[part 1 of 3: package /Svc_Dem]
AUTOSAR XML (schema 00047)
package /Svc_Dem
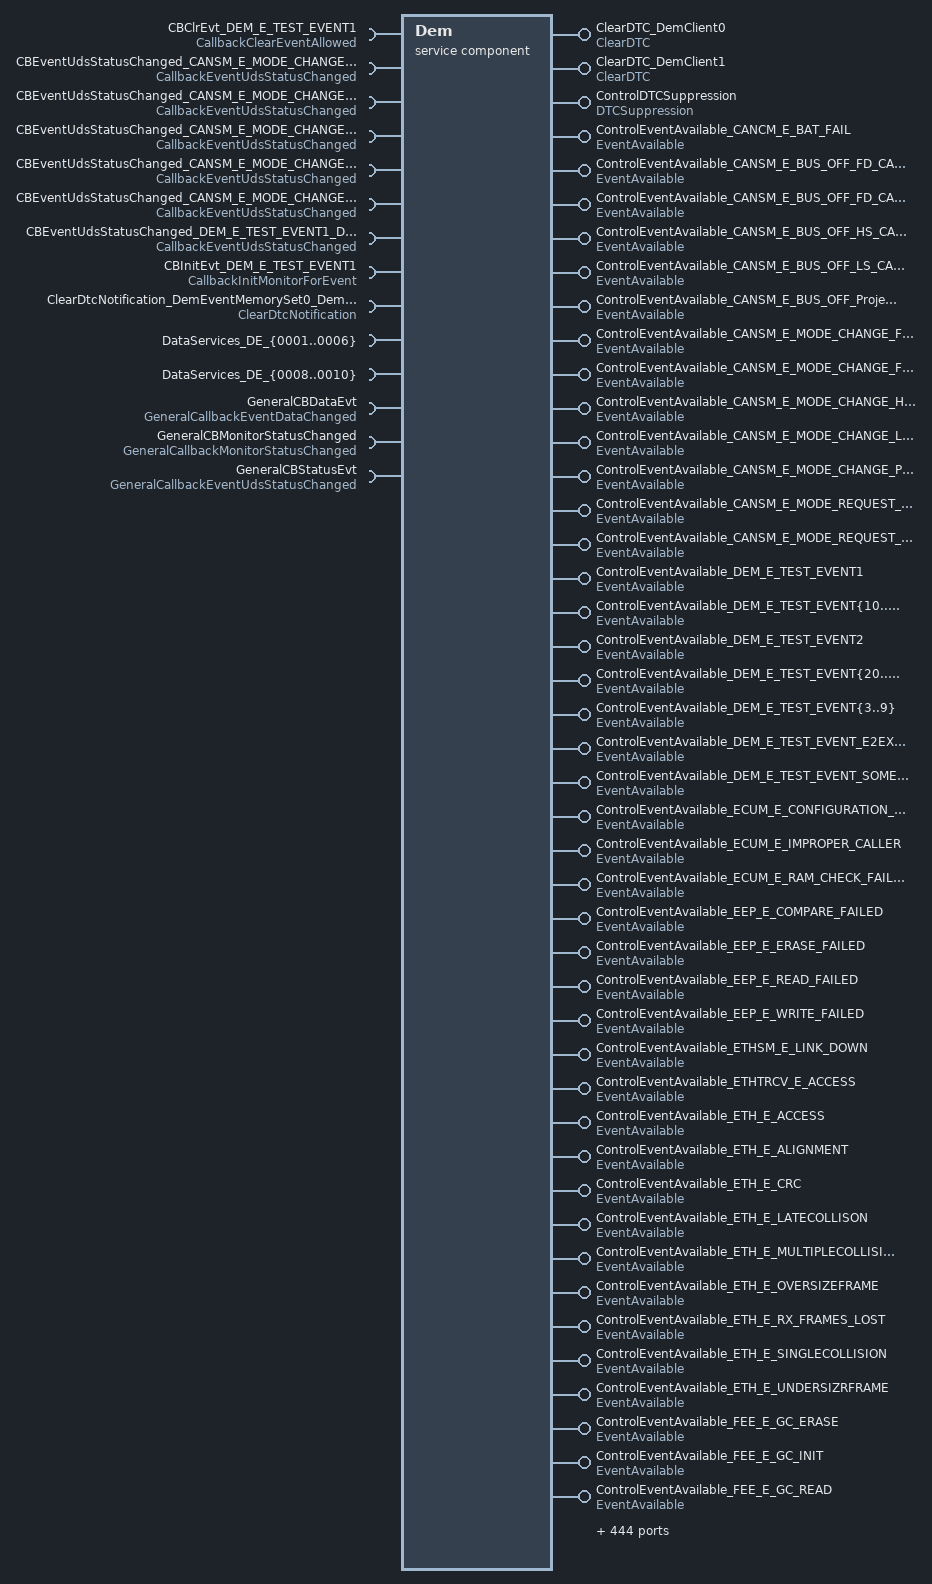
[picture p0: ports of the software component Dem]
  service sw component type Dem
    8 x require port:
      CBClrEvt_DEM_E_TEST_EVENT1: client-com-spec=ClearEventAllowed, required-interface=CallbackClearEventAllowed
      CBEventUdsStatusChanged_CANSM_E_MODE_CHANGE_FD_CAN1_DemCallbackEventUdsStatusChanged0: client-com-spec=CallbackEventUdsStatusChanged, required-interface=CallbackEventUdsStatusChanged
      CBEventUdsStatusChanged_CANSM_E_MODE_CHANGE_FD_CAN2_DemCallbackEventUdsStatusChanged0: client-com-spec=CallbackEventUdsStatusChanged, required-interface=CallbackEventUdsStatusChanged
      CBEventUdsStatusChanged_CANSM_E_MODE_CHANGE_HS_CAN1_DemCallbackEventUdsStatusChanged0: client-com-spec=CallbackEventUdsStatusChanged, required-interface=CallbackEventUdsStatusChanged
      CBEventUdsStatusChanged_CANSM_E_MODE_CHANGE_LS_CAN1_DemCallbackEventUdsStatusChanged0: client-com-spec=CallbackEventUdsStatusChanged, required-interface=CallbackEventUdsStatusChanged
      CBEventUdsStatusChanged_CANSM_E_MODE_CHANGE_Project_DemCallbackEventUdsStatusChanged0: client-com-spec=CallbackEventUdsStatusChanged, required-interface=CallbackEventUdsStatusChanged
      CBEventUdsStatusChanged_DEM_E_TEST_EVENT1_DemCallbackEventUdsStatusChanged0: client-com-spec=CallbackEventUdsStatusChanged, required-interface=CallbackEventUdsStatusChanged
      CBInitEvt_DEM_E_TEST_EVENT1: client-com-spec=InitMonitorForEvent, required-interface=CallbackInitMonitorForEvent
    provide port ClearDTC_DemClient0: provided-com-specs=[{operation=ClearDTC, queue-length=1}, {operation=SelectDTC, queue-length=1}], provided-interface=ClearDTC  # This port provides the Supervision interface of DemClient0 to a SWC.
    provide port ClearDTC_DemClient1: provided-com-specs=[{operation=ClearDTC, queue-length=1}, {operation=SelectDTC, queue-length=1}], provided-interface=ClearDTC  # This port provides the Supervision interface of DemClient1 to a SWC.
    require port ClearDtcNotification_DemEventMemorySet0_DemClearDTCNotification0: client-com-spec=ClearDtcNotification, required-interface=ClearDtcNotification
    108 x provide port:
      ControlDTCSuppression: provided-com-specs=[{operation=GetDTCSuppression, queue-length=1}, {operation=SetDTCSuppression, queue-length=1}], provided-interface=DTCSuppression  # This port provides the Supervision interface of ControlDTCSuppression to a SWC.
      ControlEventAvailable_CANCM_E_BAT_FAIL: server-com-spec{operation=SetEventAvailable, queue-length=1}, provided-interface=EventAvailable  # This port provides the Supervision interface of CANCM_E_BAT_FAIL to a SWC.
      ControlEventAvailable_CANSM_E_BUS_OFF_FD_CAN1: server-com-spec{operation=SetEventAvailable, queue-length=1}, provided-interface=EventAvailable  # This port provides the Supervision interface of CANSM_E_BUS_OFF_FD_CAN1 to a SWC.
      ControlEventAvailable_CANSM_E_BUS_OFF_FD_CAN2: server-com-spec{operation=SetEventAvailable, queue-length=1}, provided-interface=EventAvailable  # This port provides the Supervision interface of CANSM_E_BUS_OFF_FD_CAN2 to a SWC.
      ControlEventAvailable_CANSM_E_BUS_OFF_HS_CAN1: server-com-spec{operation=SetEventAvailable, queue-length=1}, provided-interface=EventAvailable  # This port provides the Supervision interface of CANSM_E_BUS_OFF_HS_CAN1 to a SWC.
      ControlEventAvailable_CANSM_E_BUS_OFF_LS_CAN1: server-com-spec{operation=SetEventAvailable, queue-length=1}, provided-interface=EventAvailable  # This port provides the Supervision interface of CANSM_E_BUS_OFF_LS_CAN1 to a SWC.
      ControlEventAvailable_CANSM_E_BUS_OFF_Project: server-com-spec{operation=SetEventAvailable, queue-length=1}, provided-interface=EventAvailable  # This port provides the Supervision interface of CANSM_E_BUS_OFF_Project to a SWC.
      ControlEventAvailable_CANSM_E_MODE_CHANGE_FD_CAN1: server-com-spec{operation=SetEventAvailable, queue-length=1}, provided-interface=EventAvailable  # This port provides the Supervision interface of CANSM_E_MODE_CHANGE_FD_CAN1 to a SWC.
      ControlEventAvailable_CANSM_E_MODE_CHANGE_FD_CAN2: server-com-spec{operation=SetEventAvailable, queue-length=1}, provided-interface=EventAvailable  # This port provides the Supervision interface of CANSM_E_MODE_CHANGE_FD_CAN2 to a SWC.
      ControlEventAvailable_CANSM_E_MODE_CHANGE_HS_CAN1: server-com-spec{operation=SetEventAvailable, queue-length=1}, provided-interface=EventAvailable  # This port provides the Supervision interface of CANSM_E_MODE_CHANGE_HS_CAN1 to a SWC.
      ControlEventAvailable_CANSM_E_MODE_CHANGE_LS_CAN1: server-com-spec{operation=SetEventAvailable, queue-length=1}, provided-interface=EventAvailable  # This port provides the Supervision interface of CANSM_E_MODE_CHANGE_LS_CAN1 to a SWC.
      ControlEventAvailable_CANSM_E_MODE_CHANGE_Project: server-com-spec{operation=SetEventAvailable, queue-length=1}, provided-interface=EventAvailable  # This port provides the Supervision interface of CANSM_E_MODE_CHANGE_Project to a SWC.
      ControlEventAvailable_CANSM_E_MODE_REQUEST_TIMEOUT_FD_CAN1: server-com-spec{operation=SetEventAvailable, queue-length=1}, provided-interface=EventAvailable  # This port provides the Supervision interface of CANSM_E_MODE_REQUEST_TIMEOUT_FD_CAN1 to a SWC.
      ControlEventAvailable_CANSM_E_MODE_REQUEST_TIMEOUT_HS_CAN1: server-com-spec{operation=SetEventAvailable, queue-length=1}, provided-interface=EventAvailable  # This port provides the Supervision interface of CANSM_E_MODE_REQUEST_TIMEOUT_HS_CAN1 to a SWC.
      ControlEventAvailable_DEM_E_TEST_EVENT1: server-com-spec{operation=SetEventAvailable, queue-length=1}, provided-interface=EventAvailable  # This port provides the Supervision interface of DEM_E_TEST_EVENT1 to a SWC.
      ControlEventAvailable_DEM_E_TEST_EVENT{10..19}: server-com-spec{operation=SetEventAvailable, queue-length=1}, provided-interface=EventAvailable  # This port provides the Supervision interface of DEM_E_TEST_EVENT{10..19} to a SWC.
      ControlEventAvailable_DEM_E_TEST_EVENT2: server-com-spec{operation=SetEventAvailable, queue-length=1}, provided-interface=EventAvailable  # This port provides the Supervision interface of DEM_E_TEST_EVENT2 to a SWC.
      ControlEventAvailable_DEM_E_TEST_EVENT{20..22}: server-com-spec{operation=SetEventAvailable, queue-length=1}, provided-interface=EventAvailable  # This port provides the Supervision interface of DEM_E_TEST_EVENT{20..22} to a SWC.
      ControlEventAvailable_DEM_E_TEST_EVENT{3..9}: server-com-spec{operation=SetEventAvailable, queue-length=1}, provided-interface=EventAvailable  # This port provides the Supervision interface of DEM_E_TEST_EVENT{3..9} to a SWC.
      ControlEventAvailable_DEM_E_TEST_EVENT_E2EXF_MALFORMED_MESSAGE: server-com-spec{operation=SetEventAvailable, queue-length=1}, provided-interface=EventAvailable  # This port provides the Supervision interface of DEM_E_TEST_EVENT_E2EXF_MALFORMED_MESSAGE to a SWC.
      ControlEventAvailable_DEM_E_TEST_EVENT_SOMEIPXF_MALFORMED_MESSAGE: server-com-spec{operation=SetEventAvailable, queue-length=1}, provided-interface=EventAvailable  # This port provides the Supervision interface of DEM_E_TEST_EVENT_SOMEIPXF_MALFORMED_MESSAGE to a SWC.
      ControlEventAvailable_ECUM_E_CONFIGURATION_DATA_INCONSISTENT: server-com-spec{operation=SetEventAvailable, queue-length=1}, provided-interface=EventAvailable  # This port provides the Supervision interface of ECUM_E_CONFIGURATION_DATA_INCONSISTENT to a SWC.
      ControlEventAvailable_ECUM_E_IMPROPER_CALLER: server-com-spec{operation=SetEventAvailable, queue-length=1}, provided-interface=EventAvailable  # This port provides the Supervision interface of ECUM_E_IMPROPER_CALLER to a SWC.
      ControlEventAvailable_ECUM_E_RAM_CHECK_FAILED: server-com-spec{operation=SetEventAvailable, queue-length=1}, provided-interface=EventAvailable  # This port provides the Supervision interface of ECUM_E_RAM_CHECK_FAILED to a SWC.
      ControlEventAvailable_EEP_E_COMPARE_FAILED: server-com-spec{operation=SetEventAvailable, queue-length=1}, provided-interface=EventAvailable  # This port provides the Supervision interface of EEP_E_COMPARE_FAILED to a SWC.
      ControlEventAvailable_EEP_E_ERASE_FAILED: server-com-spec{operation=SetEventAvailable, queue-length=1}, provided-interface=EventAvailable  # This port provides the Supervision interface of EEP_E_ERASE_FAILED to a SWC.
      ControlEventAvailable_EEP_E_READ_FAILED: server-com-spec{operation=SetEventAvailable, queue-length=1}, provided-interface=EventAvailable  # This port provides the Supervision interface of EEP_E_READ_FAILED to a SWC.
      ControlEventAvailable_EEP_E_WRITE_FAILED: server-com-spec{operation=SetEventAvailable, queue-length=1}, provided-interface=EventAvailable  # This port provides the Supervision interface of EEP_E_WRITE_FAILED to a SWC.
      ControlEventAvailable_ETHSM_E_LINK_DOWN: server-com-spec{operation=SetEventAvailable, queue-length=1}, provided-interface=EventAvailable  # This port provides the Supervision interface of ETHSM_E_LINK_DOWN to a SWC.
      ControlEventAvailable_ETHTRCV_E_ACCESS: server-com-spec{operation=SetEventAvailable, queue-length=1}, provided-interface=EventAvailable  # This port provides the Supervision interface of ETHTRCV_E_ACCESS to a SWC.
      ControlEventAvailable_ETH_E_ACCESS: server-com-spec{operation=SetEventAvailable, queue-length=1}, provided-interface=EventAvailable  # This port provides the Supervision interface of ETH_E_ACCESS to a SWC.
      ControlEventAvailable_ETH_E_ALIGNMENT: server-com-spec{operation=SetEventAvailable, queue-length=1}, provided-interface=EventAvailable  # This port provides the Supervision interface of ETH_E_ALIGNMENT to a SWC.
      ControlEventAvailable_ETH_E_CRC: server-com-spec{operation=SetEventAvailable, queue-length=1}, provided-interface=EventAvailable  # This port provides the Supervision interface of ETH_E_CRC to a SWC.
      ControlEventAvailable_ETH_E_LATECOLLISON: server-com-spec{operation=SetEventAvailable, queue-length=1}, provided-interface=EventAvailable  # This port provides the Supervision interface of ETH_E_LATECOLLISON to a SWC.
      ControlEventAvailable_ETH_E_MULTIPLECOLLISION: server-com-spec{operation=SetEventAvailable, queue-length=1}, provided-interface=EventAvailable  # This port provides the Supervision interface of ETH_E_MULTIPLECOLLISION to a SWC.
      ControlEventAvailable_ETH_E_OVERSIZEFRAME: server-com-spec{operation=SetEventAvailable, queue-length=1}, provided-interface=EventAvailable  # This port provides the Supervision interface of ETH_E_OVERSIZEFRAME to a SWC.
      ControlEventAvailable_ETH_E_RX_FRAMES_LOST: server-com-spec{operation=SetEventAvailable, queue-length=1}, provided-interface=EventAvailable  # This port provides the Supervision interface of ETH_E_RX_FRAMES_LOST to a SWC.
      ControlEventAvailable_ETH_E_SINGLECOLLISION: server-com-spec{operation=SetEventAvailable, queue-length=1}, provided-interface=EventAvailable  # This port provides the Supervision interface of ETH_E_SINGLECOLLISION to a SWC.
      ControlEventAvailable_ETH_E_UNDERSIZRFRAME: server-com-spec{operation=SetEventAvailable, queue-length=1}, provided-interface=EventAvailable  # This port provides the Supervision interface of ETH_E_UNDERSIZRFRAME to a SWC.
      ControlEventAvailable_FEE_E_GC_ERASE: server-com-spec{operation=SetEventAvailable, queue-length=1}, provided-interface=EventAvailable  # This port provides the Supervision interface of FEE_E_GC_ERASE to a SWC.
      ControlEventAvailable_FEE_E_GC_INIT: server-com-spec{operation=SetEventAvailable, queue-length=1}, provided-interface=EventAvailable  # This port provides the Supervision interface of FEE_E_GC_INIT to a SWC.
      ControlEventAvailable_FEE_E_GC_READ: server-com-spec{operation=SetEventAvailable, queue-length=1}, provided-interface=EventAvailable  # This port provides the Supervision interface of FEE_E_GC_READ to a SWC.
      ControlEventAvailable_FEE_E_GC_TRIG: server-com-spec{operation=SetEventAvailable, queue-length=1}, provided-interface=EventAvailable  # This port provides the Supervision interface of FEE_E_GC_TRIG to a SWC.
      ControlEventAvailable_FEE_E_GC_WRITE: server-com-spec{operation=SetEventAvailable, queue-length=1}, provided-interface=EventAvailable  # This port provides the Supervision interface of FEE_E_GC_WRITE to a SWC.
      ControlEventAvailable_FEE_E_INVALIDATE: server-com-spec{operation=SetEventAvailable, queue-length=1}, provided-interface=EventAvailable  # This port provides the Supervision interface of FEE_E_INVALIDATE to a SWC.
      ControlEventAvailable_FEE_E_READ: server-com-spec{operation=SetEventAvailable, queue-length=1}, provided-interface=EventAvailable  # This port provides the Supervision interface of FEE_E_READ to a SWC.
      ControlEventAvailable_FEE_E_UNCONFIG_BLK_EXCEEDED: server-com-spec{operation=SetEventAvailable, queue-length=1}, provided-interface=EventAvailable  # This port provides the Supervision interface of FEE_E_UNCONFIG_BLK_EXCEEDED to a SWC.
      ControlEventAvailable_FEE_E_WRITE: server-com-spec{operation=SetEventAvailable, queue-length=1}, provided-interface=EventAvailable  # This port provides the Supervision interface of FEE_E_WRITE to a SWC.
      ControlEventAvailable_FEE_E_WRITE_CYCLES_EXHAUSTED: server-com-spec{operation=SetEventAvailable, queue-length=1}, provided-interface=EventAvailable  # This port provides the Supervision interface of FEE_E_WRITE_CYCLES_EXHAUSTED to a SWC.
      ControlEventAvailable_FLS_E_COMPARE_FAILED: server-com-spec{operation=SetEventAvailable, queue-length=1}, provided-interface=EventAvailable  # This port provides the Supervision interface of FLS_E_COMPARE_FAILED to a SWC.
      ControlEventAvailable_FLS_E_ERASE_FAILED: server-com-spec{operation=SetEventAvailable, queue-length=1}, provided-interface=EventAvailable  # This port provides the Supervision interface of FLS_E_ERASE_FAILED to a SWC.
      ControlEventAvailable_FLS_E_READ_FAILED: server-com-spec{operation=SetEventAvailable, queue-length=1}, provided-interface=EventAvailable  # This port provides the Supervision interface of FLS_E_READ_FAILED to a SWC.
      ControlEventAvailable_FLS_E_UNEXPECTED_FLASH_ID: server-com-spec{operation=SetEventAvailable, queue-length=1}, provided-interface=EventAvailable  # This port provides the Supervision interface of FLS_E_UNEXPECTED_FLASH_ID to a SWC.
      ControlEventAvailable_FLS_E_WRITE_FAILED: server-com-spec{operation=SetEventAvailable, queue-length=1}, provided-interface=EventAvailable  # This port provides the Supervision interface of FLS_E_WRITE_FAILED to a SWC.
      ControlEventAvailable_IOHWAB_E_BUSY: server-com-spec{operation=SetEventAvailable, queue-length=1}, provided-interface=EventAvailable  # This port provides the Supervision interface of IOHWAB_E_BUSY to a SWC.
      ControlEventAvailable_IOHWAB_E_PROC_FAIL: server-com-spec{operation=SetEventAvailable, queue-length=1}, provided-interface=EventAvailable  # This port provides the Supervision interface of IOHWAB_E_PROC_FAIL to a SWC.
      ControlEventAvailable_IOHWAB_E_SETUP_FAIL: server-com-spec{operation=SetEventAvailable, queue-length=1}, provided-interface=EventAvailable  # This port provides the Supervision interface of IOHWAB_E_SETUP_FAIL to a SWC.
      ControlEventAvailable_IOHWAB_E_WRONG_PARAM: server-com-spec{operation=SetEventAvailable, queue-length=1}, provided-interface=EventAvailable  # This port provides the Supervision interface of IOHWAB_E_WRONG_PARAM to a SWC.
      ControlEventAvailable_IOHWAB_E_WRONG_SETTING: server-com-spec{operation=SetEventAvailable, queue-length=1}, provided-interface=EventAvailable  # This port provides the Supervision interface of IOHWAB_E_WRONG_SETTING to a SWC.
      ControlEventAvailable_IOHWAB_E_WRONG_STATE: server-com-spec{operation=SetEventAvailable, queue-length=1}, provided-interface=EventAvailable  # This port provides the Supervision interface of IOHWAB_E_WRONG_STATE to a SWC.
      ControlEventAvailable_MCU_E_CCU6_CLC_DISABLE_ERR: server-com-spec{operation=SetEventAvailable, queue-length=1}, provided-interface=EventAvailable  # This port provides the Supervision interface of MCU_E_CCU6_CLC_DISABLE_ERR to a SWC.
      ControlEventAvailable_MCU_E_CCU6_CLC_ENABLE_ERR: server-com-spec{operation=SetEventAvailable, queue-length=1}, provided-interface=EventAvailable  # This port provides the Supervision interface of MCU_E_CCU6_CLC_ENABLE_ERR to a SWC.
      ControlEventAvailable_MCU_E_CCUCON_UPDATE_ERR: server-com-spec{operation=SetEventAvailable, queue-length=1}, provided-interface=EventAvailable  # This port provides the Supervision interface of MCU_E_CCUCON_UPDATE_ERR to a SWC.
      ControlEventAvailable_MCU_E_CLOCK_FAILURE: server-com-spec{operation=SetEventAvailable, queue-length=1}, provided-interface=EventAvailable  # This port provides the Supervision interface of MCU_E_CLOCK_FAILURE to a SWC.
      ControlEventAvailable_MCU_E_CONVCTRL_CLC_DISABLE_ERR: server-com-spec{operation=SetEventAvailable, queue-length=1}, provided-interface=EventAvailable  # This port provides the Supervision interface of MCU_E_CONVCTRL_CLC_DISABLE_ERR to a SWC.
      ControlEventAvailable_MCU_E_CONVCTRL_CLC_ENABLE_ERR: server-com-spec{operation=SetEventAvailable, queue-length=1}, provided-interface=EventAvailable  # This port provides the Supervision interface of MCU_E_CONVCTRL_CLC_ENABLE_ERR to a SWC.
      ControlEventAvailable_MCU_E_GPT12_CLC_DISABLE_ERR: server-com-spec{operation=SetEventAvailable, queue-length=1}, provided-interface=EventAvailable  # This port provides the Supervision interface of MCU_E_GPT12_CLC_DISABLE_ERR to a SWC.
      ControlEventAvailable_MCU_E_GPT12_CLC_ENABLE_ERR: server-com-spec{operation=SetEventAvailable, queue-length=1}, provided-interface=EventAvailable  # This port provides the Supervision interface of MCU_E_GPT12_CLC_ENABLE_ERR to a SWC.
      ControlEventAvailable_MCU_E_GTM_CLC_DISABLE_ERR: server-com-spec{operation=SetEventAvailable, queue-length=1}, provided-interface=EventAvailable  # This port provides the Supervision interface of MCU_E_GTM_CLC_DISABLE_ERR to a SWC.
      ControlEventAvailable_MCU_E_GTM_CLC_ENABLE_ERR: server-com-spec{operation=SetEventAvailable, queue-length=1}, provided-interface=EventAvailable  # This port provides the Supervision interface of MCU_E_GTM_CLC_ENABLE_ERR to a SWC.
      ControlEventAvailable_MCU_E_OSC_FAILURE: server-com-spec{operation=SetEventAvailable, queue-length=1}, provided-interface=EventAvailable  # This port provides the Supervision interface of MCU_E_OSC_FAILURE to a SWC.
      ControlEventAvailable_MCU_E_PERIPHERAL_PLL_LOCK_LOSS: server-com-spec{operation=SetEventAvailable, queue-length=1}, provided-interface=EventAvailable  # This port provides the Supervision interface of MCU_E_PERIPHERAL_PLL_LOCK_LOSS to a SWC.
      ControlEventAvailable_MCU_E_PERIPHERAL_PLL_TIMEOUT_ERR: server-com-spec{operation=SetEventAvailable, queue-length=1}, provided-interface=EventAvailable  # This port provides the Supervision interface of MCU_E_PERIPHERAL_PLL_TIMEOUT_ERR to a SWC.
      ControlEventAvailable_MCU_E_PMSWCR_UPDATE_ERR: server-com-spec{operation=SetEventAvailable, queue-length=1}, provided-interface=EventAvailable  # This port provides the Supervision interface of MCU_E_PMSWCR_UPDATE_ERR to a SWC.
      ControlEventAvailable_MCU_E_SYSTEM_PLL_LOCK_LOSS: server-com-spec{operation=SetEventAvailable, queue-length=1}, provided-interface=EventAvailable  # This port provides the Supervision interface of MCU_E_SYSTEM_PLL_LOCK_LOSS to a SWC.
      ControlEventAvailable_MCU_E_SYSTEM_PLL_TIMEOUT_ERR: server-com-spec{operation=SetEventAvailable, queue-length=1}, provided-interface=EventAvailable  # This port provides the Supervision interface of MCU_E_SYSTEM_PLL_TIMEOUT_ERR to a SWC.
      ControlEventAvailable_NVM_E_INTEGRITY_FAILED: server-com-spec{operation=SetEventAvailable, queue-length=1}, provided-interface=EventAvailable  # This port provides the Supervision interface of NVM_E_INTEGRITY_FAILED to a SWC.
      ControlEventAvailable_NVM_E_LOSS_OF_REDUNDANCY: server-com-spec{operation=SetEventAvailable, queue-length=1}, provided-interface=EventAvailable  # This port provides the Supervision interface of NVM_E_LOSS_OF_REDUNDANCY to a SWC.
      ControlEventAvailable_NVM_E_QUEUE_OVERFLOW: server-com-spec{operation=SetEventAvailable, queue-length=1}, provided-interface=EventAvailable  # This port provides the Supervision interface of NVM_E_QUEUE_OVERFLOW to a SWC.
      ControlEventAvailable_NVM_E_REQ_FAILED: server-com-spec{operation=SetEventAvailable, queue-length=1}, provided-interface=EventAvailable  # This port provides the Supervision interface of NVM_E_REQ_FAILED to a SWC.
      ControlEventAvailable_NVM_E_VERIFY_FAILED: server-com-spec{operation=SetEventAvailable, queue-length=1}, provided-interface=EventAvailable  # This port provides the Supervision interface of NVM_E_VERIFY_FAILED to a SWC.
      ControlEventAvailable_NVM_E_WRITE_PROTECTED: server-com-spec{operation=SetEventAvailable, queue-length=1}, provided-interface=EventAvailable  # This port provides the Supervision interface of NVM_E_WRITE_PROTECTED to a SWC.
      ControlEventAvailable_NVM_E_WRONG_BLOCK_ID: server-com-spec{operation=SetEventAvailable, queue-length=1}, provided-interface=EventAvailable  # This port provides the Supervision interface of NVM_E_WRONG_BLOCK_ID to a SWC.
      ControlEventAvailable_SPI_E_HARDWARE_ERROR: server-com-spec{operation=SetEventAvailable, queue-length=1}, provided-interface=EventAvailable  # This port provides the Supervision interface of SPI_E_HARDWARE_ERROR to a SWC.
      ControlEventAvailable_WDGM_E_IMPROPER_CALLER: server-com-spec{operation=SetEventAvailable, queue-length=1}, provided-interface=EventAvailable  # This port provides the Supervision interface of WDGM_E_IMPROPER_CALLER to a SWC.
      ControlEventAvailable_WDGM_E_MONITORING: server-com-spec{operation=SetEventAvailable, queue-length=1}, provided-interface=EventAvailable  # This port provides the Supervision interface of WDGM_E_MONITORING to a SWC.
      ControlEventAvailable_WDGM_E_SET_MODE: server-com-spec{operation=SetEventAvailable, queue-length=1}, provided-interface=EventAvailable  # This port provides the Supervision interface of WDGM_E_SET_MODE to a SWC.
      ControlEventAvailable_WDG_76_ACW_E_DISABLE_REJECTED: server-com-spec{operation=SetEventAvailable, queue-length=1}, provided-interface=EventAvailable  # This port provides the Supervision interface of WDG_76_ACW_E_DISABLE_REJECTED to a SWC.
      ControlEventAvailable_WDG_76_ACW_E_MODE_FAILED: server-com-spec{operation=SetEventAvailable, queue-length=1}, provided-interface=EventAvailable  # This port provides the Supervision interface of WDG_76_ACW_E_MODE_FAILED to a SWC.
      ControlEventAvailable_WDG_E_DISABLE_REJECTED: server-com-spec{operation=SetEventAvailable, queue-length=1}, provided-interface=EventAvailable  # This port provides the Supervision interface of WDG_E_DISABLE_REJECTED to a SWC.
      ControlEventAvailable_WDG_E_MODE_FAILED: server-com-spec{operation=SetEventAvailable, queue-length=1}, provided-interface=EventAvailable  # This port provides the Supervision interface of WDG_E_MODE_FAILED to a SWC.
    9 x require port:
      DataServices_DE_{0001..0006}: client-com-spec=DataServices_DE_{0001..0006}/ReadData, required-interface=DataServices_DE_{0001..0006}
      DataServices_DE_{0008..0010}: client-com-spec=DataServices_DE_{0008..0010}/ReadData, required-interface=DataServices_DE_{0008..0010}
    429 x provide port:
      DiagnosticMonitor_MonitorData_CANCM_E_BAT_FAIL: server-com-spec{operation=DiagnosticMonitor_MonitorData/SetEventStatusWithMonitorData, queue-length=1}, provided-interface=DiagnosticMonitor_MonitorData  # This port provides the Supervision interface of CANCM_E_BAT_FAIL to a SWC.
      DiagnosticMonitor_MonitorData_CANSM_E_BUS_OFF_FD_CAN1: server-com-spec{operation=DiagnosticMonitor_MonitorData/SetEventStatusWithMonitorData, queue-length=1}, provided-interface=DiagnosticMonitor_MonitorData  # This port provides the Supervision interface of CANSM_E_BUS_OFF_FD_CAN1 to a SWC.
      DiagnosticMonitor_MonitorData_CANSM_E_BUS_OFF_FD_CAN2: server-com-spec{operation=DiagnosticMonitor_MonitorData/SetEventStatusWithMonitorData, queue-length=1}, provided-interface=DiagnosticMonitor_MonitorData  # This port provides the Supervision interface of CANSM_E_BUS_OFF_FD_CAN2 to a SWC.
      DiagnosticMonitor_MonitorData_CANSM_E_BUS_OFF_HS_CAN1: server-com-spec{operation=DiagnosticMonitor_MonitorData/SetEventStatusWithMonitorData, queue-length=1}, provided-interface=DiagnosticMonitor_MonitorData  # This port provides the Supervision interface of CANSM_E_BUS_OFF_HS_CAN1 to a SWC.
      DiagnosticMonitor_MonitorData_CANSM_E_BUS_OFF_LS_CAN1: server-com-spec{operation=DiagnosticMonitor_MonitorData/SetEventStatusWithMonitorData, queue-length=1}, provided-interface=DiagnosticMonitor_MonitorData  # This port provides the Supervision interface of CANSM_E_BUS_OFF_LS_CAN1 to a SWC.
      DiagnosticMonitor_MonitorData_CANSM_E_BUS_OFF_Project: server-com-spec{operation=DiagnosticMonitor_MonitorData/SetEventStatusWithMonitorData, queue-length=1}, provided-interface=DiagnosticMonitor_MonitorData  # This port provides the Supervision interface of CANSM_E_BUS_OFF_Project to a SWC.
      DiagnosticMonitor_MonitorData_CANSM_E_MODE_CHANGE_FD_CAN1: server-com-spec{operation=DiagnosticMonitor_MonitorData/SetEventStatusWithMonitorData, queue-length=1}, provided-interface=DiagnosticMonitor_MonitorData  # This port provides the Supervision interface of CANSM_E_MODE_CHANGE_FD_CAN1 to a SWC.
      DiagnosticMonitor_MonitorData_CANSM_E_MODE_CHANGE_FD_CAN2: server-com-spec{operation=DiagnosticMonitor_MonitorData/SetEventStatusWithMonitorData, queue-length=1}, provided-interface=DiagnosticMonitor_MonitorData  # This port provides the Supervision interface of CANSM_E_MODE_CHANGE_FD_CAN2 to a SWC.
      DiagnosticMonitor_MonitorData_CANSM_E_MODE_CHANGE_HS_CAN1: server-com-spec{operation=DiagnosticMonitor_MonitorData/SetEventStatusWithMonitorData, queue-length=1}, provided-interface=DiagnosticMonitor_MonitorData  # This port provides the Supervision interface of CANSM_E_MODE_CHANGE_HS_CAN1 to a SWC.
      DiagnosticMonitor_MonitorData_CANSM_E_MODE_CHANGE_LS_CAN1: server-com-spec{operation=DiagnosticMonitor_MonitorData/SetEventStatusWithMonitorData, queue-length=1}, provided-interface=DiagnosticMonitor_MonitorData  # This port provides the Supervision interface of CANSM_E_MODE_CHANGE_LS_CAN1 to a SWC.
      DiagnosticMonitor_MonitorData_CANSM_E_MODE_CHANGE_Project: server-com-spec{operation=DiagnosticMonitor_MonitorData/SetEventStatusWithMonitorData, queue-length=1}, provided-interface=DiagnosticMonitor_MonitorData  # This port provides the Supervision interface of CANSM_E_MODE_CHANGE_Project to a SWC.
      DiagnosticMonitor_MonitorData_CANSM_E_MODE_REQUEST_TIMEOUT_FD_CAN1: server-com-spec{operation=DiagnosticMonitor_MonitorData/SetEventStatusWithMonitorData, queue-length=1}, provided-interface=DiagnosticMonitor_MonitorData  # This port provides the Supervision interface of CANSM_E_MODE_REQUEST_TIMEOUT_FD_CAN1 to a SWC.
      DiagnosticMonitor_MonitorData_CANSM_E_MODE_REQUEST_TIMEOUT_HS_CAN1: server-com-spec{operation=DiagnosticMonitor_MonitorData/SetEventStatusWithMonitorData, queue-length=1}, provided-interface=DiagnosticMonitor_MonitorData  # This port provides the Supervision interface of CANSM_E_MODE_REQUEST_TIMEOUT_HS_CAN1 to a SWC.
      DiagnosticMonitor_MonitorData_DEM_E_TEST_EVENT1: server-com-spec{operation=DiagnosticMonitor_MonitorData/SetEventStatusWithMonitorData, queue-length=1}, provided-interface=DiagnosticMonitor_MonitorData  # This port provides the Supervision interface of DEM_E_TEST_EVENT1 to a SWC.
      DiagnosticMonitor_MonitorData_DEM_E_TEST_EVENT{10..19}: server-com-spec{operation=DiagnosticMonitor_MonitorData/SetEventStatusWithMonitorData, queue-length=1}, provided-interface=DiagnosticMonitor_MonitorData  # This port provides the Supervision interface of DEM_E_TEST_EVENT{10..19} to a SWC.
      DiagnosticMonitor_MonitorData_DEM_E_TEST_EVENT2: server-com-spec{operation=DiagnosticMonitor_MonitorData/SetEventStatusWithMonitorData, queue-length=1}, provided-interface=DiagnosticMonitor_MonitorData  # This port provides the Supervision interface of DEM_E_TEST_EVENT2 to a SWC.
      DiagnosticMonitor_MonitorData_DEM_E_TEST_EVENT{20..22}: server-com-spec{operation=DiagnosticMonitor_MonitorData/SetEventStatusWithMonitorData, queue-length=1}, provided-interface=DiagnosticMonitor_MonitorData  # This port provides the Supervision interface of DEM_E_TEST_EVENT{20..22} to a SWC.
      DiagnosticMonitor_MonitorData_DEM_E_TEST_EVENT{3..9}: server-com-spec{operation=DiagnosticMonitor_MonitorData/SetEventStatusWithMonitorData, queue-length=1}, provided-interface=DiagnosticMonitor_MonitorData  # This port provides the Supervision interface of DEM_E_TEST_EVENT{3..9} to a SWC.
      DiagnosticMonitor_MonitorData_DEM_E_TEST_EVENT_E2EXF_MALFORMED_MESSAGE: server-com-spec{operation=DiagnosticMonitor_MonitorData/SetEventStatusWithMonitorData, queue-length=1}, provided-interface=DiagnosticMonitor_MonitorData  # This port provides the Supervision interface of DEM_E_TEST_EVENT_E2EXF_MALFORMED_MESSAGE to a SWC.
      DiagnosticMonitor_MonitorData_DEM_E_TEST_EVENT_SOMEIPXF_MALFORMED_MESSAGE: server-com-spec{operation=DiagnosticMonitor_MonitorData/SetEventStatusWithMonitorData, queue-length=1}, provided-interface=DiagnosticMonitor_MonitorData  # This port provides the Supervision interface of DEM_E_TEST_EVENT_SOMEIPXF_MALFORMED_MESSAGE to a SWC.
      DiagnosticMonitor_MonitorData_ECUM_E_CONFIGURATION_DATA_INCONSISTENT: server-com-spec{operation=DiagnosticMonitor_MonitorData/SetEventStatusWithMonitorData, queue-length=1}, provided-interface=DiagnosticMonitor_MonitorData  # This port provides the Supervision interface of ECUM_E_CONFIGURATION_DATA_INCONSISTENT to a SWC.
      DiagnosticMonitor_MonitorData_ECUM_E_IMPROPER_CALLER: server-com-spec{operation=DiagnosticMonitor_MonitorData/SetEventStatusWithMonitorData, queue-length=1}, provided-interface=DiagnosticMonitor_MonitorData  # This port provides the Supervision interface of ECUM_E_IMPROPER_CALLER to a SWC.
      DiagnosticMonitor_MonitorData_ECUM_E_RAM_CHECK_FAILED: server-com-spec{operation=DiagnosticMonitor_MonitorData/SetEventStatusWithMonitorData, queue-length=1}, provided-interface=DiagnosticMonitor_MonitorData  # This port provides the Supervision interface of ECUM_E_RAM_CHECK_FAILED to a SWC.
      DiagnosticMonitor_MonitorData_EEP_E_COMPARE_FAILED: server-com-spec{operation=DiagnosticMonitor_MonitorData/SetEventStatusWithMonitorData, queue-length=1}, provided-interface=DiagnosticMonitor_MonitorData  # This port provides the Supervision interface of EEP_E_COMPARE_FAILED to a SWC.
      DiagnosticMonitor_MonitorData_EEP_E_ERASE_FAILED: server-com-spec{operation=DiagnosticMonitor_MonitorData/SetEventStatusWithMonitorData, queue-length=1}, provided-interface=DiagnosticMonitor_MonitorData  # This port provides the Supervision interface of EEP_E_ERASE_FAILED to a SWC.
      DiagnosticMonitor_MonitorData_EEP_E_READ_FAILED: server-com-spec{operation=DiagnosticMonitor_MonitorData/SetEventStatusWithMonitorData, queue-length=1}, provided-interface=DiagnosticMonitor_MonitorData  # This port provides the Supervision interface of EEP_E_READ_FAILED to a SWC.
      DiagnosticMonitor_MonitorData_EEP_E_WRITE_FAILED: server-com-spec{operation=DiagnosticMonitor_MonitorData/SetEventStatusWithMonitorData, queue-length=1}, provided-interface=DiagnosticMonitor_MonitorData  # This port provides the Supervision interface of EEP_E_WRITE_FAILED to a SWC.
      DiagnosticMonitor_MonitorData_ETHSM_E_LINK_DOWN: server-com-spec{operation=DiagnosticMonitor_MonitorData/SetEventStatusWithMonitorData, queue-length=1}, provided-interface=DiagnosticMonitor_MonitorData  # This port provides the Supervision interface of ETHSM_E_LINK_DOWN to a SWC.
      DiagnosticMonitor_MonitorData_ETHTRCV_E_ACCESS: server-com-spec{operation=DiagnosticMonitor_MonitorData/SetEventStatusWithMonitorData, queue-length=1}, provided-interface=DiagnosticMonitor_MonitorData  # This port provides the Supervision interface of ETHTRCV_E_ACCESS to a SWC.
      DiagnosticMonitor_MonitorData_ETH_E_ACCESS: server-com-spec{operation=DiagnosticMonitor_MonitorData/SetEventStatusWithMonitorData, queue-length=1}, provided-interface=DiagnosticMonitor_MonitorData  # This port provides the Supervision interface of ETH_E_ACCESS to a SWC.
      DiagnosticMonitor_MonitorData_ETH_E_ALIGNMENT: server-com-spec{operation=DiagnosticMonitor_MonitorData/SetEventStatusWithMonitorData, queue-length=1}, provided-interface=DiagnosticMonitor_MonitorData  # This port provides the Supervision interface of ETH_E_ALIGNMENT to a SWC.
      DiagnosticMonitor_MonitorData_ETH_E_CRC: server-com-spec{operation=DiagnosticMonitor_MonitorData/SetEventStatusWithMonitorData, queue-length=1}, provided-interface=DiagnosticMonitor_MonitorData  # This port provides the Supervision interface of ETH_E_CRC to a SWC.
      DiagnosticMonitor_MonitorData_ETH_E_LATECOLLISON: server-com-spec{operation=DiagnosticMonitor_MonitorData/SetEventStatusWithMonitorData, queue-length=1}, provided-interface=DiagnosticMonitor_MonitorData  # This port provides the Supervision interface of ETH_E_LATECOLLISON to a SWC.
      DiagnosticMonitor_MonitorData_ETH_E_MULTIPLECOLLISION: server-com-spec{operation=DiagnosticMonitor_MonitorData/SetEventStatusWithMonitorData, queue-length=1}, provided-interface=DiagnosticMonitor_MonitorData  # This port provides the Supervision interface of ETH_E_MULTIPLECOLLISION to a SWC.
      DiagnosticMonitor_MonitorData_ETH_E_OVERSIZEFRAME: server-com-spec{operation=DiagnosticMonitor_MonitorData/SetEventStatusWithMonitorData, queue-length=1}, provided-interface=DiagnosticMonitor_MonitorData  # This port provides the Supervision interface of ETH_E_OVERSIZEFRAME to a SWC.
      DiagnosticMonitor_MonitorData_ETH_E_RX_FRAMES_LOST: server-com-spec{operation=DiagnosticMonitor_MonitorData/SetEventStatusWithMonitorData, queue-length=1}, provided-interface=DiagnosticMonitor_MonitorData  # This port provides the Supervision interface of ETH_E_RX_FRAMES_LOST to a SWC.
      DiagnosticMonitor_MonitorData_ETH_E_SINGLECOLLISION: server-com-spec{operation=DiagnosticMonitor_MonitorData/SetEventStatusWithMonitorData, queue-length=1}, provided-interface=DiagnosticMonitor_MonitorData  # This port provides the Supervision interface of ETH_E_SINGLECOLLISION to a SWC.
      DiagnosticMonitor_MonitorData_ETH_E_UNDERSIZRFRAME: server-com-spec{operation=DiagnosticMonitor_MonitorData/SetEventStatusWithMonitorData, queue-length=1}, provided-interface=DiagnosticMonitor_MonitorData  # This port provides the Supervision interface of ETH_E_UNDERSIZRFRAME to a SWC.
      DiagnosticMonitor_MonitorData_FEE_E_GC_ERASE: server-com-spec{operation=DiagnosticMonitor_MonitorData/SetEventStatusWithMonitorData, queue-length=1}, provided-interface=DiagnosticMonitor_MonitorData  # This port provides the Supervision interface of FEE_E_GC_ERASE to a SWC.
      DiagnosticMonitor_MonitorData_FEE_E_GC_INIT: server-com-spec{operation=DiagnosticMonitor_MonitorData/SetEventStatusWithMonitorData, queue-length=1}, provided-interface=DiagnosticMonitor_MonitorData  # This port provides the Supervision interface of FEE_E_GC_INIT to a SWC.
      DiagnosticMonitor_MonitorData_FEE_E_GC_READ: server-com-spec{operation=DiagnosticMonitor_MonitorData/SetEventStatusWithMonitorData, queue-length=1}, provided-interface=DiagnosticMonitor_MonitorData  # This port provides the Supervision interface of FEE_E_GC_READ to a SWC.
      DiagnosticMonitor_MonitorData_FEE_E_GC_TRIG: server-com-spec{operation=DiagnosticMonitor_MonitorData/SetEventStatusWithMonitorData, queue-length=1}, provided-interface=DiagnosticMonitor_MonitorData  # This port provides the Supervision interface of FEE_E_GC_TRIG to a SWC.
      DiagnosticMonitor_MonitorData_FEE_E_GC_WRITE: server-com-spec{operation=DiagnosticMonitor_MonitorData/SetEventStatusWithMonitorData, queue-length=1}, provided-interface=DiagnosticMonitor_MonitorData  # This port provides the Supervision interface of FEE_E_GC_WRITE to a SWC.
      DiagnosticMonitor_MonitorData_FEE_E_INVALIDATE: server-com-spec{operation=DiagnosticMonitor_MonitorData/SetEventStatusWithMonitorData, queue-length=1}, provided-interface=DiagnosticMonitor_MonitorData  # This port provides the Supervision interface of FEE_E_INVALIDATE to a SWC.
      DiagnosticMonitor_MonitorData_FEE_E_READ: server-com-spec{operation=DiagnosticMonitor_MonitorData/SetEventStatusWithMonitorData, queue-length=1}, provided-interface=DiagnosticMonitor_MonitorData  # This port provides the Supervision interface of FEE_E_READ to a SWC.
      DiagnosticMonitor_MonitorData_FEE_E_UNCONFIG_BLK_EXCEEDED: server-com-spec{operation=DiagnosticMonitor_MonitorData/SetEventStatusWithMonitorData, queue-length=1}, provided-interface=DiagnosticMonitor_MonitorData  # This port provides the Supervision interface of FEE_E_UNCONFIG_BLK_EXCEEDED to a SWC.
      DiagnosticMonitor_MonitorData_FEE_E_WRITE: server-com-spec{operation=DiagnosticMonitor_MonitorData/SetEventStatusWithMonitorData, queue-length=1}, provided-interface=DiagnosticMonitor_MonitorData  # This port provides the Supervision interface of FEE_E_WRITE to a SWC.
      DiagnosticMonitor_MonitorData_FEE_E_WRITE_CYCLES_EXHAUSTED: server-com-spec{operation=DiagnosticMonitor_MonitorData/SetEventStatusWithMonitorData, queue-length=1}, provided-interface=DiagnosticMonitor_MonitorData  # This port provides the Supervision interface of FEE_E_WRITE_CYCLES_EXHAUSTED to a SWC.
      DiagnosticMonitor_MonitorData_FLS_E_COMPARE_FAILED: server-com-spec{operation=DiagnosticMonitor_MonitorData/SetEventStatusWithMonitorData, queue-length=1}, provided-interface=DiagnosticMonitor_MonitorData  # This port provides the Supervision interface of FLS_E_COMPARE_FAILED to a SWC.
      DiagnosticMonitor_MonitorData_FLS_E_ERASE_FAILED: server-com-spec{operation=DiagnosticMonitor_MonitorData/SetEventStatusWithMonitorData, queue-length=1}, provided-interface=DiagnosticMonitor_MonitorData  # This port provides the Supervision interface of FLS_E_ERASE_FAILED to a SWC.
      DiagnosticMonitor_MonitorData_FLS_E_READ_FAILED: server-com-spec{operation=DiagnosticMonitor_MonitorData/SetEventStatusWithMonitorData, queue-length=1}, provided-interface=DiagnosticMonitor_MonitorData  # This port provides the Supervision interface of FLS_E_READ_FAILED to a SWC.
      DiagnosticMonitor_MonitorData_FLS_E_UNEXPECTED_FLASH_ID: server-com-spec{operation=DiagnosticMonitor_MonitorData/SetEventStatusWithMonitorData, queue-length=1}, provided-interface=DiagnosticMonitor_MonitorData  # This port provides the Supervision interface of FLS_E_UNEXPECTED_FLASH_ID to a SWC.
      DiagnosticMonitor_MonitorData_FLS_E_WRITE_FAILED: server-com-spec{operation=DiagnosticMonitor_MonitorData/SetEventStatusWithMonitorData, queue-length=1}, provided-interface=DiagnosticMonitor_MonitorData  # This port provides the Supervision interface of FLS_E_WRITE_FAILED to a SWC.
      DiagnosticMonitor_MonitorData_IOHWAB_E_BUSY: server-com-spec{operation=DiagnosticMonitor_MonitorData/SetEventStatusWithMonitorData, queue-length=1}, provided-interface=DiagnosticMonitor_MonitorData  # This port provides the Supervision interface of IOHWAB_E_BUSY to a SWC.
      DiagnosticMonitor_MonitorData_IOHWAB_E_PROC_FAIL: server-com-spec{operation=DiagnosticMonitor_MonitorData/SetEventStatusWithMonitorData, queue-length=1}, provided-interface=DiagnosticMonitor_MonitorData  # This port provides the Supervision interface of IOHWAB_E_PROC_FAIL to a SWC.
      DiagnosticMonitor_MonitorData_IOHWAB_E_SETUP_FAIL: server-com-spec{operation=DiagnosticMonitor_MonitorData/SetEventStatusWithMonitorData, queue-length=1}, provided-interface=DiagnosticMonitor_MonitorData  # This port provides the Supervision interface of IOHWAB_E_SETUP_FAIL to a SWC.
      DiagnosticMonitor_MonitorData_IOHWAB_E_WRONG_PARAM: server-com-spec{operation=DiagnosticMonitor_MonitorData/SetEventStatusWithMonitorData, queue-length=1}, provided-interface=DiagnosticMonitor_MonitorData  # This port provides the Supervision interface of IOHWAB_E_WRONG_PARAM to a SWC.
      DiagnosticMonitor_MonitorData_IOHWAB_E_WRONG_SETTING: server-com-spec{operation=DiagnosticMonitor_MonitorData/SetEventStatusWithMonitorData, queue-length=1}, provided-interface=DiagnosticMonitor_MonitorData  # This port provides the Supervision interface of IOHWAB_E_WRONG_SETTING to a SWC.
      DiagnosticMonitor_MonitorData_IOHWAB_E_WRONG_STATE: server-com-spec{operation=DiagnosticMonitor_MonitorData/SetEventStatusWithMonitorData, queue-length=1}, provided-interface=DiagnosticMonitor_MonitorData  # This port provides the Supervision interface of IOHWAB_E_WRONG_STATE to a SWC.
      DiagnosticMonitor_MonitorData_MCU_E_CCU6_CLC_DISABLE_ERR: server-com-spec{operation=DiagnosticMonitor_MonitorData/SetEventStatusWithMonitorData, queue-length=1}, provided-interface=DiagnosticMonitor_MonitorData  # This port provides the Supervision interface of MCU_E_CCU6_CLC_DISABLE_ERR to a SWC.
      DiagnosticMonitor_MonitorData_MCU_E_CCU6_CLC_ENABLE_ERR: server-com-spec{operation=DiagnosticMonitor_MonitorData/SetEventStatusWithMonitorData, queue-length=1}, provided-interface=DiagnosticMonitor_MonitorData  # This port provides the Supervision interface of MCU_E_CCU6_CLC_ENABLE_ERR to a SWC.
      DiagnosticMonitor_MonitorData_MCU_E_CCUCON_UPDATE_ERR: server-com-spec{operation=DiagnosticMonitor_MonitorData/SetEventStatusWithMonitorData, queue-length=1}, provided-interface=DiagnosticMonitor_MonitorData  # This port provides the Supervision interface of MCU_E_CCUCON_UPDATE_ERR to a SWC.
      DiagnosticMonitor_MonitorData_MCU_E_CLOCK_FAILURE: server-com-spec{operation=DiagnosticMonitor_MonitorData/SetEventStatusWithMonitorData, queue-length=1}, provided-interface=DiagnosticMonitor_MonitorData  # This port provides the Supervision interface of MCU_E_CLOCK_FAILURE to a SWC.
      DiagnosticMonitor_MonitorData_MCU_E_CONVCTRL_CLC_DISABLE_ERR: server-com-spec{operation=DiagnosticMonitor_MonitorData/SetEventStatusWithMonitorData, queue-length=1}, provided-interface=DiagnosticMonitor_MonitorData  # This port provides the Supervision interface of MCU_E_CONVCTRL_CLC_DISABLE_ERR to a SWC.
      DiagnosticMonitor_MonitorData_MCU_E_CONVCTRL_CLC_ENABLE_ERR: server-com-spec{operation=DiagnosticMonitor_MonitorData/SetEventStatusWithMonitorData, queue-length=1}, provided-interface=DiagnosticMonitor_MonitorData  # This port provides the Supervision interface of MCU_E_CONVCTRL_CLC_ENABLE_ERR to a SWC.
      DiagnosticMonitor_MonitorData_MCU_E_GPT12_CLC_DISABLE_ERR: server-com-spec{operation=DiagnosticMonitor_MonitorData/SetEventStatusWithMonitorData, queue-length=1}, provided-interface=DiagnosticMonitor_MonitorData  # This port provides the Supervision interface of MCU_E_GPT12_CLC_DISABLE_ERR to a SWC.
      DiagnosticMonitor_MonitorData_MCU_E_GPT12_CLC_ENABLE_ERR: server-com-spec{operation=DiagnosticMonitor_MonitorData/SetEventStatusWithMonitorData, queue-length=1}, provided-interface=DiagnosticMonitor_MonitorData  # This port provides the Supervision interface of MCU_E_GPT12_CLC_ENABLE_ERR to a SWC.
      DiagnosticMonitor_MonitorData_MCU_E_GTM_CLC_DISABLE_ERR: server-com-spec{operation=DiagnosticMonitor_MonitorData/SetEventStatusWithMonitorData, queue-length=1}, provided-interface=DiagnosticMonitor_MonitorData  # This port provides the Supervision interface of MCU_E_GTM_CLC_DISABLE_ERR to a SWC.
      DiagnosticMonitor_MonitorData_MCU_E_GTM_CLC_ENABLE_ERR: server-com-spec{operation=DiagnosticMonitor_MonitorData/SetEventStatusWithMonitorData, queue-length=1}, provided-interface=DiagnosticMonitor_MonitorData  # This port provides the Supervision interface of MCU_E_GTM_CLC_ENABLE_ERR to a SWC.
      DiagnosticMonitor_MonitorData_MCU_E_OSC_FAILURE: server-com-spec{operation=DiagnosticMonitor_MonitorData/SetEventStatusWithMonitorData, queue-length=1}, provided-interface=DiagnosticMonitor_MonitorData  # This port provides the Supervision interface of MCU_E_OSC_FAILURE to a SWC.
      DiagnosticMonitor_MonitorData_MCU_E_PERIPHERAL_PLL_LOCK_LOSS: server-com-spec{operation=DiagnosticMonitor_MonitorData/SetEventStatusWithMonitorData, queue-length=1}, provided-interface=DiagnosticMonitor_MonitorData  # This port provides the Supervision interface of MCU_E_PERIPHERAL_PLL_LOCK_LOSS to a SWC.
      DiagnosticMonitor_MonitorData_MCU_E_PERIPHERAL_PLL_TIMEOUT_ERR: server-com-spec{operation=DiagnosticMonitor_MonitorData/SetEventStatusWithMonitorData, queue-length=1}, provided-interface=DiagnosticMonitor_MonitorData  # This port provides the Supervision interface of MCU_E_PERIPHERAL_PLL_TIMEOUT_ERR to a SWC.
      DiagnosticMonitor_MonitorData_MCU_E_PMSWCR_UPDATE_ERR: server-com-spec{operation=DiagnosticMonitor_MonitorData/SetEventStatusWithMonitorData, queue-length=1}, provided-interface=DiagnosticMonitor_MonitorData  # This port provides the Supervision interface of MCU_E_PMSWCR_UPDATE_ERR to a SWC.
      DiagnosticMonitor_MonitorData_MCU_E_SYSTEM_PLL_LOCK_LOSS: server-com-spec{operation=DiagnosticMonitor_MonitorData/SetEventStatusWithMonitorData, queue-length=1}, provided-interface=DiagnosticMonitor_MonitorData  # This port provides the Supervision interface of MCU_E_SYSTEM_PLL_LOCK_LOSS to a SWC.
      DiagnosticMonitor_MonitorData_MCU_E_SYSTEM_PLL_TIMEOUT_ERR: server-com-spec{operation=DiagnosticMonitor_MonitorData/SetEventStatusWithMonitorData, queue-length=1}, provided-interface=DiagnosticMonitor_MonitorData  # This port provides the Supervision interface of MCU_E_SYSTEM_PLL_TIMEOUT_ERR to a SWC.
      DiagnosticMonitor_MonitorData_NVM_E_INTEGRITY_FAILED: server-com-spec{operation=DiagnosticMonitor_MonitorData/SetEventStatusWithMonitorData, queue-length=1}, provided-interface=DiagnosticMonitor_MonitorData  # This port provides the Supervision interface of NVM_E_INTEGRITY_FAILED to a SWC.
      DiagnosticMonitor_MonitorData_NVM_E_LOSS_OF_REDUNDANCY: server-com-spec{operation=DiagnosticMonitor_MonitorData/SetEventStatusWithMonitorData, queue-length=1}, provided-interface=DiagnosticMonitor_MonitorData  # This port provides the Supervision interface of NVM_E_LOSS_OF_REDUNDANCY to a SWC.
      DiagnosticMonitor_MonitorData_NVM_E_QUEUE_OVERFLOW: server-com-spec{operation=DiagnosticMonitor_MonitorData/SetEventStatusWithMonitorData, queue-length=1}, provided-interface=DiagnosticMonitor_MonitorData  # This port provides the Supervision interface of NVM_E_QUEUE_OVERFLOW to a SWC.
      DiagnosticMonitor_MonitorData_NVM_E_REQ_FAILED: server-com-spec{operation=DiagnosticMonitor_MonitorData/SetEventStatusWithMonitorData, queue-length=1}, provided-interface=DiagnosticMonitor_MonitorData  # This port provides the Supervision interface of NVM_E_REQ_FAILED to a SWC.
      DiagnosticMonitor_MonitorData_NVM_E_VERIFY_FAILED: server-com-spec{operation=DiagnosticMonitor_MonitorData/SetEventStatusWithMonitorData, queue-length=1}, provided-interface=DiagnosticMonitor_MonitorData  # This port provides the Supervision interface of NVM_E_VERIFY_FAILED to a SWC.
      DiagnosticMonitor_MonitorData_NVM_E_WRITE_PROTECTED: server-com-spec{operation=DiagnosticMonitor_MonitorData/SetEventStatusWithMonitorData, queue-length=1}, provided-interface=DiagnosticMonitor_MonitorData  # This port provides the Supervision interface of NVM_E_WRITE_PROTECTED to a SWC.
      DiagnosticMonitor_MonitorData_NVM_E_WRONG_BLOCK_ID: server-com-spec{operation=DiagnosticMonitor_MonitorData/SetEventStatusWithMonitorData, queue-length=1}, provided-interface=DiagnosticMonitor_MonitorData  # This port provides the Supervision interface of NVM_E_WRONG_BLOCK_ID to a SWC.
      DiagnosticMonitor_MonitorData_SPI_E_HARDWARE_ERROR: server-com-spec{operation=DiagnosticMonitor_MonitorData/SetEventStatusWithMonitorData, queue-length=1}, provided-interface=DiagnosticMonitor_MonitorData  # This port provides the Supervision interface of SPI_E_HARDWARE_ERROR to a SWC.
      DiagnosticMonitor_MonitorData_WDGM_E_IMPROPER_CALLER: server-com-spec{operation=DiagnosticMonitor_MonitorData/SetEventStatusWithMonitorData, queue-length=1}, provided-interface=DiagnosticMonitor_MonitorData  # This port provides the Supervision interface of WDGM_E_IMPROPER_CALLER to a SWC.
      DiagnosticMonitor_MonitorData_WDGM_E_MONITORING: server-com-spec{operation=DiagnosticMonitor_MonitorData/SetEventStatusWithMonitorData, queue-length=1}, provided-interface=DiagnosticMonitor_MonitorData  # This port provides the Supervision interface of WDGM_E_MONITORING to a SWC.
      DiagnosticMonitor_MonitorData_WDGM_E_SET_MODE: server-com-spec{operation=DiagnosticMonitor_MonitorData/SetEventStatusWithMonitorData, queue-length=1}, provided-interface=DiagnosticMonitor_MonitorData  # This port provides the Supervision interface of WDGM_E_SET_MODE to a SWC.
      DiagnosticMonitor_MonitorData_WDG_76_ACW_E_DISABLE_REJECTED: server-com-spec{operation=DiagnosticMonitor_MonitorData/SetEventStatusWithMonitorData, queue-length=1}, provided-interface=DiagnosticMonitor_MonitorData  # This port provides the Supervision interface of WDG_76_ACW_E_DISABLE_REJECTED to a SWC.
      DiagnosticMonitor_MonitorData_WDG_76_ACW_E_MODE_FAILED: server-com-spec{operation=DiagnosticMonitor_MonitorData/SetEventStatusWithMonitorData, queue-length=1}, provided-interface=DiagnosticMonitor_MonitorData  # This port provides the Supervision interface of WDG_76_ACW_E_MODE_FAILED to a SWC.
      DiagnosticMonitor_MonitorData_WDG_E_DISABLE_REJECTED: server-com-spec{operation=DiagnosticMonitor_MonitorData/SetEventStatusWithMonitorData, queue-length=1}, provided-interface=DiagnosticMonitor_MonitorData  # This port provides the Supervision interface of WDG_E_DISABLE_REJECTED to a SWC.
      DiagnosticMonitor_MonitorData_WDG_E_MODE_FAILED: server-com-spec{operation=DiagnosticMonitor_MonitorData/SetEventStatusWithMonitorData, queue-length=1}, provided-interface=DiagnosticMonitor_MonitorData  # This port provides the Supervision interface of WDG_E_MODE_FAILED to a SWC.
      EnableCond_DemEnableCondition0: server-com-spec{operation=SetEnableCondition, queue-length=1}, provided-interface=EnableCondition  # This port provides the Supervision interface of DemEnableCondition0 to a SWC.
      EventInfo_CANCM_E_BAT_FAIL: provided-interface=DiagnosticInfo  # This port provides the Supervision interface of CANCM_E_BAT_FAIL to a SWC.
        provided-com-specs:
          operation=DiagnosticInfo/GetDTCOfEvent, queue-length=1
          operation=DiagnosticInfo/GetDebouncingOfEvent, queue-length=1
          operation=GetEventExtendedDataRecordEx, queue-length=1
          operation=GetEventFreezeFrameDataEx, queue-length=1
          operation=DiagnosticInfo/GetEventUdsStatus, queue-length=1
          operation=DiagnosticInfo/GetFaultDetectionCounter, queue-length=1
          operation=DiagnosticInfo/GetMonitorStatus, queue-length=1
      EventInfo_CANSM_E_BUS_OFF_FD_CAN1: provided-interface=DiagnosticInfo  # This port provides the Supervision interface of CANSM_E_BUS_OFF_FD_CAN1 to a SWC.
        provided-com-specs:
          operation=DiagnosticInfo/GetDTCOfEvent, queue-length=1
          operation=DiagnosticInfo/GetDebouncingOfEvent, queue-length=1
          operation=GetEventExtendedDataRecordEx, queue-length=1
          operation=GetEventFreezeFrameDataEx, queue-length=1
          operation=DiagnosticInfo/GetEventUdsStatus, queue-length=1
          operation=DiagnosticInfo/GetFaultDetectionCounter, queue-length=1
          operation=DiagnosticInfo/GetMonitorStatus, queue-length=1
      EventInfo_CANSM_E_BUS_OFF_FD_CAN2: provided-interface=DiagnosticInfo  # This port provides the Supervision interface of CANSM_E_BUS_OFF_FD_CAN2 to a SWC.
        provided-com-specs:
          operation=DiagnosticInfo/GetDTCOfEvent, queue-length=1
          operation=DiagnosticInfo/GetDebouncingOfEvent, queue-length=1
          operation=GetEventExtendedDataRecordEx, queue-length=1
          operation=GetEventFreezeFrameDataEx, queue-length=1
          operation=DiagnosticInfo/GetEventUdsStatus, queue-length=1
          operation=DiagnosticInfo/GetFaultDetectionCounter, queue-length=1
          operation=DiagnosticInfo/GetMonitorStatus, queue-length=1
      EventInfo_CANSM_E_BUS_OFF_HS_CAN1: provided-interface=DiagnosticInfo  # This port provides the Supervision interface of CANSM_E_BUS_OFF_HS_CAN1 to a SWC.
        provided-com-specs:
          operation=DiagnosticInfo/GetDTCOfEvent, queue-length=1
          operation=DiagnosticInfo/GetDebouncingOfEvent, queue-length=1
          operation=GetEventExtendedDataRecordEx, queue-length=1
          operation=GetEventFreezeFrameDataEx, queue-length=1
          operation=DiagnosticInfo/GetEventUdsStatus, queue-length=1
          operation=DiagnosticInfo/GetFaultDetectionCounter, queue-length=1
          operation=DiagnosticInfo/GetMonitorStatus, queue-length=1
      EventInfo_CANSM_E_BUS_OFF_LS_CAN1: provided-interface=DiagnosticInfo  # This port provides the Supervision interface of CANSM_E_BUS_OFF_LS_CAN1 to a SWC.
        provided-com-specs:
          operation=DiagnosticInfo/GetDTCOfEvent, queue-length=1
          operation=DiagnosticInfo/GetDebouncingOfEvent, queue-length=1
          operation=GetEventExtendedDataRecordEx, queue-length=1
          operation=GetEventFreezeFrameDataEx, queue-length=1
          operation=DiagnosticInfo/GetEventUdsStatus, queue-length=1
          operation=DiagnosticInfo/GetFaultDetectionCounter, queue-length=1
          operation=DiagnosticInfo/GetMonitorStatus, queue-length=1
      EventInfo_CANSM_E_BUS_OFF_Project: provided-interface=DiagnosticInfo  # This port provides the Supervision interface of CANSM_E_BUS_OFF_Project to a SWC.
        provided-com-specs:
          operation=DiagnosticInfo/GetDTCOfEvent, queue-length=1
          operation=DiagnosticInfo/GetDebouncingOfEvent, queue-length=1
          operation=GetEventExtendedDataRecordEx, queue-length=1
          operation=GetEventFreezeFrameDataEx, queue-length=1
          operation=DiagnosticInfo/GetEventUdsStatus, queue-length=1
          operation=DiagnosticInfo/GetFaultDetectionCounter, queue-length=1
          operation=DiagnosticInfo/GetMonitorStatus, queue-length=1
      EventInfo_CANSM_E_MODE_CHANGE_FD_CAN1: provided-interface=DiagnosticInfo  # This port provides the Supervision interface of CANSM_E_MODE_CHANGE_FD_CAN1 to a SWC.
        provided-com-specs:
          operation=DiagnosticInfo/GetDTCOfEvent, queue-length=1
          operation=DiagnosticInfo/GetDebouncingOfEvent, queue-length=1
          operation=GetEventExtendedDataRecordEx, queue-length=1
          operation=GetEventFreezeFrameDataEx, queue-length=1
          operation=DiagnosticInfo/GetEventUdsStatus, queue-length=1
          operation=DiagnosticInfo/GetFaultDetectionCounter, queue-length=1
          operation=DiagnosticInfo/GetMonitorStatus, queue-length=1
      EventInfo_CANSM_E_MODE_CHANGE_FD_CAN2: provided-interface=DiagnosticInfo  # This port provides the Supervision interface of CANSM_E_MODE_CHANGE_FD_CAN2 to a SWC.
        provided-com-specs:
          operation=DiagnosticInfo/GetDTCOfEvent, queue-length=1
          operation=DiagnosticInfo/GetDebouncingOfEvent, queue-length=1
          operation=GetEventExtendedDataRecordEx, queue-length=1
          operation=GetEventFreezeFrameDataEx, queue-length=1
          operation=DiagnosticInfo/GetEventUdsStatus, queue-length=1
          operation=DiagnosticInfo/GetFaultDetectionCounter, queue-length=1
          operation=DiagnosticInfo/GetMonitorStatus, queue-length=1
      EventInfo_CANSM_E_MODE_CHANGE_HS_CAN1: provided-interface=DiagnosticInfo  # This port provides the Supervision interface of CANSM_E_MODE_CHANGE_HS_CAN1 to a SWC.
        provided-com-specs:
          operation=DiagnosticInfo/GetDTCOfEvent, queue-length=1
          operation=DiagnosticInfo/GetDebouncingOfEvent, queue-length=1
          operation=GetEventExtendedDataRecordEx, queue-length=1
          operation=GetEventFreezeFrameDataEx, queue-length=1
          operation=DiagnosticInfo/GetEventUdsStatus, queue-length=1
          operation=DiagnosticInfo/GetFaultDetectionCounter, queue-length=1
          operation=DiagnosticInfo/GetMonitorStatus, queue-length=1
      EventInfo_CANSM_E_MODE_CHANGE_LS_CAN1: provided-interface=DiagnosticInfo  # This port provides the Supervision interface of CANSM_E_MODE_CHANGE_LS_CAN1 to a SWC.
        provided-com-specs:
          operation=DiagnosticInfo/GetDTCOfEvent, queue-length=1
          operation=DiagnosticInfo/GetDebouncingOfEvent, queue-length=1
          operation=GetEventExtendedDataRecordEx, queue-length=1
          operation=GetEventFreezeFrameDataEx, queue-length=1
          operation=DiagnosticInfo/GetEventUdsStatus, queue-length=1
          operation=DiagnosticInfo/GetFaultDetectionCounter, queue-length=1
          operation=DiagnosticInfo/GetMonitorStatus, queue-length=1
      EventInfo_CANSM_E_MODE_CHANGE_Project: provided-interface=DiagnosticInfo  # This port provides the Supervision interface of CANSM_E_MODE_CHANGE_Project to a SWC.
        provided-com-specs:
          operation=DiagnosticInfo/GetDTCOfEvent, queue-length=1
          operation=DiagnosticInfo/GetDebouncingOfEvent, queue-length=1
          operation=GetEventExtendedDataRecordEx, queue-length=1
          operation=GetEventFreezeFrameDataEx, queue-length=1
          operation=DiagnosticInfo/GetEventUdsStatus, queue-length=1
          operation=DiagnosticInfo/GetFaultDetectionCounter, queue-length=1
          operation=DiagnosticInfo/GetMonitorStatus, queue-length=1
      EventInfo_CANSM_E_MODE_REQUEST_TIMEOUT_FD_CAN1: provided-interface=DiagnosticInfo  # This port provides the Supervision interface of CANSM_E_MODE_REQUEST_TIMEOUT_FD_CAN1 to a SWC.
        provided-com-specs:
          operation=DiagnosticInfo/GetDTCOfEvent, queue-length=1
          operation=DiagnosticInfo/GetDebouncingOfEvent, queue-length=1
          operation=GetEventExtendedDataRecordEx, queue-length=1
          operation=GetEventFreezeFrameDataEx, queue-length=1
          operation=DiagnosticInfo/GetEventUdsStatus, queue-length=1
          operation=DiagnosticInfo/GetFaultDetectionCounter, queue-length=1
          operation=DiagnosticInfo/GetMonitorStatus, queue-length=1
      EventInfo_CANSM_E_MODE_REQUEST_TIMEOUT_HS_CAN1: provided-interface=DiagnosticInfo  # This port provides the Supervision interface of CANSM_E_MODE_REQUEST_TIMEOUT_HS_CAN1 to a SWC.
        provided-com-specs:
          operation=DiagnosticInfo/GetDTCOfEvent, queue-length=1
          operation=DiagnosticInfo/GetDebouncingOfEvent, queue-length=1
          operation=GetEventExtendedDataRecordEx, queue-length=1
          operation=GetEventFreezeFrameDataEx, queue-length=1
          operation=DiagnosticInfo/GetEventUdsStatus, queue-length=1
          operation=DiagnosticInfo/GetFaultDetectionCounter, queue-length=1
          operation=DiagnosticInfo/GetMonitorStatus, queue-length=1
      EventInfo_DEM_E_TEST_EVENT1: provided-interface=DiagnosticInfo  # This port provides the Supervision interface of DEM_E_TEST_EVENT1 to a SWC.
        provided-com-specs:
          operation=DiagnosticInfo/GetDTCOfEvent, queue-length=1
          operation=DiagnosticInfo/GetDebouncingOfEvent, queue-length=1
          operation=GetEventExtendedDataRecordEx, queue-length=1
          operation=GetEventFreezeFrameDataEx, queue-length=1
          operation=DiagnosticInfo/GetEventUdsStatus, queue-length=1
          operation=DiagnosticInfo/GetFaultDetectionCounter, queue-length=1
          operation=DiagnosticInfo/GetMonitorStatus, queue-length=1
      EventInfo_DEM_E_TEST_EVENT10: provided-interface=DiagnosticInfo  # This port provides the Supervision interface of DEM_E_TEST_EVENT10 to a SWC.
        provided-com-specs:
          operation=DiagnosticInfo/GetDTCOfEvent, queue-length=1
          operation=DiagnosticInfo/GetDebouncingOfEvent, queue-length=1
          operation=GetEventExtendedDataRecordEx, queue-length=1
          operation=GetEventFreezeFrameDataEx, queue-length=1
          operation=DiagnosticInfo/GetEventUdsStatus, queue-length=1
          operation=DiagnosticInfo/GetFaultDetectionCounter, queue-length=1
          operation=DiagnosticInfo/GetMonitorStatus, queue-length=1
      EventInfo_DEM_E_TEST_EVENT11: provided-interface=DiagnosticInfo  # This port provides the Supervision interface of DEM_E_TEST_EVENT11 to a SWC.
        provided-com-specs:
          operation=DiagnosticInfo/GetDTCOfEvent, queue-length=1
          operation=DiagnosticInfo/GetDebouncingOfEvent, queue-length=1
          operation=GetEventExtendedDataRecordEx, queue-length=1
          operation=GetEventFreezeFrameDataEx, queue-length=1
          operation=DiagnosticInfo/GetEventUdsStatus, queue-length=1
          operation=DiagnosticInfo/GetFaultDetectionCounter, queue-length=1
          operation=DiagnosticInfo/GetMonitorStatus, queue-length=1
      EventInfo_DEM_E_TEST_EVENT12: provided-interface=DiagnosticInfo  # This port provides the Supervision interface of DEM_E_TEST_EVENT12 to a SWC.
        provided-com-specs:
          operation=DiagnosticInfo/GetDTCOfEvent, queue-length=1
          operation=DiagnosticInfo/GetDebouncingOfEvent, queue-length=1
          operation=GetEventExtendedDataRecordEx, queue-length=1
          operation=GetEventFreezeFrameDataEx, queue-length=1
          operation=DiagnosticInfo/GetEventUdsStatus, queue-length=1
          operation=DiagnosticInfo/GetFaultDetectionCounter, queue-length=1
          operation=DiagnosticInfo/GetMonitorStatus, queue-length=1
      EventInfo_DEM_E_TEST_EVENT13: provided-interface=DiagnosticInfo  # This port provides the Supervision interface of DEM_E_TEST_EVENT13 to a SWC.
        provided-com-specs:
          operation=DiagnosticInfo/GetDTCOfEvent, queue-length=1
          operation=DiagnosticInfo/GetDebouncingOfEvent, queue-length=1
          operation=GetEventExtendedDataRecordEx, queue-length=1
          operation=GetEventFreezeFrameDataEx, queue-length=1
          operation=DiagnosticInfo/GetEventUdsStatus, queue-length=1
          operation=DiagnosticInfo/GetFaultDetectionCounter, queue-length=1
          operation=DiagnosticInfo/GetMonitorStatus, queue-length=1
      EventInfo_DEM_E_TEST_EVENT14: provided-interface=DiagnosticInfo  # This port provides the Supervision interface of DEM_E_TEST_EVENT14 to a SWC.
        provided-com-specs:
          operation=DiagnosticInfo/GetDTCOfEvent, queue-length=1
          operation=DiagnosticInfo/GetDebouncingOfEvent, queue-length=1
          operation=GetEventExtendedDataRecordEx, queue-length=1
          operation=GetEventFreezeFrameDataEx, queue-length=1
          operation=DiagnosticInfo/GetEventUdsStatus, queue-length=1
          operation=DiagnosticInfo/GetFaultDetectionCounter, queue-length=1
          operation=DiagnosticInfo/GetMonitorStatus, queue-length=1
      EventInfo_DEM_E_TEST_EVENT15: provided-interface=DiagnosticInfo  # This port provides the Supervision interface of DEM_E_TEST_EVENT15 to a SWC.
        provided-com-specs:
          operation=DiagnosticInfo/GetDTCOfEvent, queue-length=1
          operation=DiagnosticInfo/GetDebouncingOfEvent, queue-length=1
          operation=GetEventExtendedDataRecordEx, queue-length=1
          operation=GetEventFreezeFrameDataEx, queue-length=1
          operation=DiagnosticInfo/GetEventUdsStatus, queue-length=1
          operation=DiagnosticInfo/GetFaultDetectionCounter, queue-length=1
          operation=DiagnosticInfo/GetMonitorStatus, queue-length=1
      EventInfo_DEM_E_TEST_EVENT16: provided-interface=DiagnosticInfo  # This port provides the Supervision interface of DEM_E_TEST_EVENT16 to a SWC.
        provided-com-specs:
          operation=DiagnosticInfo/GetDTCOfEvent, queue-length=1
          operation=DiagnosticInfo/GetDebouncingOfEvent, queue-length=1
          operation=GetEventExtendedDataRecordEx, queue-length=1
          operation=GetEventFreezeFrameDataEx, queue-length=1
          operation=DiagnosticInfo/GetEventUdsStatus, queue-length=1
          operation=DiagnosticInfo/GetFaultDetectionCounter, queue-length=1
          operation=DiagnosticInfo/GetMonitorStatus, queue-length=1
      EventInfo_DEM_E_TEST_EVENT17: provided-interface=DiagnosticInfo  # This port provides the Supervision interface of DEM_E_TEST_EVENT17 to a SWC.
        provided-com-specs:
          operation=DiagnosticInfo/GetDTCOfEvent, queue-length=1
          operation=DiagnosticInfo/GetDebouncingOfEvent, queue-length=1
          operation=GetEventExtendedDataRecordEx, queue-length=1
          operation=GetEventFreezeFrameDataEx, queue-length=1
          operation=DiagnosticInfo/GetEventUdsStatus, queue-length=1
          operation=DiagnosticInfo/GetFaultDetectionCounter, queue-length=1
          operation=DiagnosticInfo/GetMonitorStatus, queue-length=1
      EventInfo_DEM_E_TEST_EVENT18: provided-interface=DiagnosticInfo  # This port provides the Supervision interface of DEM_E_TEST_EVENT18 to a SWC.
        provided-com-specs:
          operation=DiagnosticInfo/GetDTCOfEvent, queue-length=1
          operation=DiagnosticInfo/GetDebouncingOfEvent, queue-length=1
          operation=GetEventExtendedDataRecordEx, queue-length=1
          operation=GetEventFreezeFrameDataEx, queue-length=1
          operation=DiagnosticInfo/GetEventUdsStatus, queue-length=1
          operation=DiagnosticInfo/GetFaultDetectionCounter, queue-length=1
          operation=DiagnosticInfo/GetMonitorStatus, queue-length=1
      EventInfo_DEM_E_TEST_EVENT19: provided-interface=DiagnosticInfo  # This port provides the Supervision interface of DEM_E_TEST_EVENT19 to a SWC.
        provided-com-specs:
          operation=DiagnosticInfo/GetDTCOfEvent, queue-length=1
          operation=DiagnosticInfo/GetDebouncingOfEvent, queue-length=1
          operation=GetEventExtendedDataRecordEx, queue-length=1
          operation=GetEventFreezeFrameDataEx, queue-length=1
          operation=DiagnosticInfo/GetEventUdsStatus, queue-length=1
          operation=DiagnosticInfo/GetFaultDetectionCounter, queue-length=1
          operation=DiagnosticInfo/GetMonitorStatus, queue-length=1
      EventInfo_DEM_E_TEST_EVENT2: provided-interface=DiagnosticInfo  # This port provides the Supervision interface of DEM_E_TEST_EVENT2 to a SWC.
        provided-com-specs:
          operation=DiagnosticInfo/GetDTCOfEvent, queue-length=1
          operation=DiagnosticInfo/GetDebouncingOfEvent, queue-length=1
          operation=GetEventExtendedDataRecordEx, queue-length=1
          operation=GetEventFreezeFrameDataEx, queue-length=1
          operation=DiagnosticInfo/GetEventUdsStatus, queue-length=1
          operation=DiagnosticInfo/GetFaultDetectionCounter, queue-length=1
          operation=DiagnosticInfo/GetMonitorStatus, queue-length=1
      EventInfo_DEM_E_TEST_EVENT20: provided-interface=DiagnosticInfo  # This port provides the Supervision interface of DEM_E_TEST_EVENT20 to a SWC.
        provided-com-specs:
          operation=DiagnosticInfo/GetDTCOfEvent, queue-length=1
          operation=DiagnosticInfo/GetDebouncingOfEvent, queue-length=1
          operation=GetEventExtendedDataRecordEx, queue-length=1
          operation=GetEventFreezeFrameDataEx, queue-length=1
          operation=DiagnosticInfo/GetEventUdsStatus, queue-length=1
          operation=DiagnosticInfo/GetFaultDetectionCounter, queue-length=1
          operation=DiagnosticInfo/GetMonitorStatus, queue-length=1
      EventInfo_DEM_E_TEST_EVENT21: provided-interface=DiagnosticInfo  # This port provides the Supervision interface of DEM_E_TEST_EVENT21 to a SWC.
        provided-com-specs:
          operation=DiagnosticInfo/GetDTCOfEvent, queue-length=1
          operation=DiagnosticInfo/GetDebouncingOfEvent, queue-length=1
          operation=GetEventExtendedDataRecordEx, queue-length=1
          operation=GetEventFreezeFrameDataEx, queue-length=1
          operation=DiagnosticInfo/GetEventUdsStatus, queue-length=1
          operation=DiagnosticInfo/GetFaultDetectionCounter, queue-length=1
          operation=DiagnosticInfo/GetMonitorStatus, queue-length=1
      EventInfo_DEM_E_TEST_EVENT22: provided-interface=DiagnosticInfo  # This port provides the Supervision interface of DEM_E_TEST_EVENT22 to a SWC.
        provided-com-specs:
          operation=DiagnosticInfo/GetDTCOfEvent, queue-length=1
          operation=DiagnosticInfo/GetDebouncingOfEvent, queue-length=1
          operation=GetEventExtendedDataRecordEx, queue-length=1
          operation=GetEventFreezeFrameDataEx, queue-length=1
          operation=DiagnosticInfo/GetEventUdsStatus, queue-length=1
          operation=DiagnosticInfo/GetFaultDetectionCounter, queue-length=1
          operation=DiagnosticInfo/GetMonitorStatus, queue-length=1
      EventInfo_DEM_E_TEST_EVENT3: provided-interface=DiagnosticInfo  # This port provides the Supervision interface of DEM_E_TEST_EVENT3 to a SWC.
        provided-com-specs:
          operation=DiagnosticInfo/GetDTCOfEvent, queue-length=1
          operation=DiagnosticInfo/GetDebouncingOfEvent, queue-length=1
          operation=GetEventExtendedDataRecordEx, queue-length=1
          operation=GetEventFreezeFrameDataEx, queue-length=1
          operation=DiagnosticInfo/GetEventUdsStatus, queue-length=1
          operation=DiagnosticInfo/GetFaultDetectionCounter, queue-length=1
          operation=DiagnosticInfo/GetMonitorStatus, queue-length=1
      EventInfo_DEM_E_TEST_EVENT4: provided-interface=DiagnosticInfo  # This port provides the Supervision interface of DEM_E_TEST_EVENT4 to a SWC.
        provided-com-specs:
          operation=DiagnosticInfo/GetDTCOfEvent, queue-length=1
          operation=DiagnosticInfo/GetDebouncingOfEvent, queue-length=1
          operation=GetEventExtendedDataRecordEx, queue-length=1
          operation=GetEventFreezeFrameDataEx, queue-length=1
          operation=DiagnosticInfo/GetEventUdsStatus, queue-length=1
          operation=DiagnosticInfo/GetFaultDetectionCounter, queue-length=1
          operation=DiagnosticInfo/GetMonitorStatus, queue-length=1
      EventInfo_DEM_E_TEST_EVENT5: provided-interface=DiagnosticInfo  # This port provides the Supervision interface of DEM_E_TEST_EVENT5 to a SWC.
        provided-com-specs:
          operation=DiagnosticInfo/GetDTCOfEvent, queue-length=1
          operation=DiagnosticInfo/GetDebouncingOfEvent, queue-length=1
          operation=GetEventExtendedDataRecordEx, queue-length=1
          operation=GetEventFreezeFrameDataEx, queue-length=1
          operation=DiagnosticInfo/GetEventUdsStatus, queue-length=1
          operation=DiagnosticInfo/GetFaultDetectionCounter, queue-length=1
          operation=DiagnosticInfo/GetMonitorStatus, queue-length=1
      EventInfo_DEM_E_TEST_EVENT6: provided-interface=DiagnosticInfo  # This port provides the Supervision interface of DEM_E_TEST_EVENT6 to a SWC.
        provided-com-specs:
          operation=DiagnosticInfo/GetDTCOfEvent, queue-length=1
          operation=DiagnosticInfo/GetDebouncingOfEvent, queue-length=1
          operation=GetEventExtendedDataRecordEx, queue-length=1
          operation=GetEventFreezeFrameDataEx, queue-length=1
          operation=DiagnosticInfo/GetEventUdsStatus, queue-length=1
          operation=DiagnosticInfo/GetFaultDetectionCounter, queue-length=1
          operation=DiagnosticInfo/GetMonitorStatus, queue-length=1
      EventInfo_DEM_E_TEST_EVENT7: provided-interface=DiagnosticInfo  # This port provides the Supervision interface of DEM_E_TEST_EVENT7 to a SWC.
        provided-com-specs:
          operation=DiagnosticInfo/GetDTCOfEvent, queue-length=1
          operation=DiagnosticInfo/GetDebouncingOfEvent, queue-length=1
          operation=GetEventExtendedDataRecordEx, queue-length=1
          operation=GetEventFreezeFrameDataEx, queue-length=1
          operation=DiagnosticInfo/GetEventUdsStatus, queue-length=1
          operation=DiagnosticInfo/GetFaultDetectionCounter, queue-length=1
          operation=DiagnosticInfo/GetMonitorStatus, queue-length=1
      EventInfo_DEM_E_TEST_EVENT8: provided-interface=DiagnosticInfo  # This port provides the Supervision interface of DEM_E_TEST_EVENT8 to a SWC.
        provided-com-specs:
          operation=DiagnosticInfo/GetDTCOfEvent, queue-length=1
          operation=DiagnosticInfo/GetDebouncingOfEvent, queue-length=1
          operation=GetEventExtendedDataRecordEx, queue-length=1
          operation=GetEventFreezeFrameDataEx, queue-length=1
          operation=DiagnosticInfo/GetEventUdsStatus, queue-length=1
          operation=DiagnosticInfo/GetFaultDetectionCounter, queue-length=1
          operation=DiagnosticInfo/GetMonitorStatus, queue-length=1
      EventInfo_DEM_E_TEST_EVENT9: provided-interface=DiagnosticInfo  # This port provides the Supervision interface of DEM_E_TEST_EVENT9 to a SWC.
        provided-com-specs:
          operation=DiagnosticInfo/GetDTCOfEvent, queue-length=1
          operation=DiagnosticInfo/GetDebouncingOfEvent, queue-length=1
          operation=GetEventExtendedDataRecordEx, queue-length=1
          operation=GetEventFreezeFrameDataEx, queue-length=1
          operation=DiagnosticInfo/GetEventUdsStatus, queue-length=1
          operation=DiagnosticInfo/GetFaultDetectionCounter, queue-length=1
          operation=DiagnosticInfo/GetMonitorStatus, queue-length=1
      EventInfo_DEM_E_TEST_EVENT_E2EXF_MALFORMED_MESSAGE: provided-interface=DiagnosticInfo  # This port provides the Supervision interface of DEM_E_TEST_EVENT_E2EXF_MALFORMED_MESSAGE to a SWC.
        provided-com-specs:
          operation=DiagnosticInfo/GetDTCOfEvent, queue-length=1
          operation=DiagnosticInfo/GetDebouncingOfEvent, queue-length=1
          operation=GetEventExtendedDataRecordEx, queue-length=1
          operation=GetEventFreezeFrameDataEx, queue-length=1
          operation=DiagnosticInfo/GetEventUdsStatus, queue-length=1
          operation=DiagnosticInfo/GetFaultDetectionCounter, queue-length=1
          operation=DiagnosticInfo/GetMonitorStatus, queue-length=1
      EventInfo_DEM_E_TEST_EVENT_SOMEIPXF_MALFORMED_MESSAGE: provided-interface=DiagnosticInfo  # This port provides the Supervision interface of DEM_E_TEST_EVENT_SOMEIPXF_MALFORMED_MESSAGE to a SWC.
        provided-com-specs:
          operation=DiagnosticInfo/GetDTCOfEvent, queue-length=1
          operation=DiagnosticInfo/GetDebouncingOfEvent, queue-length=1
          operation=GetEventExtendedDataRecordEx, queue-length=1
          operation=GetEventFreezeFrameDataEx, queue-length=1
          operation=DiagnosticInfo/GetEventUdsStatus, queue-length=1
          operation=DiagnosticInfo/GetFaultDetectionCounter, queue-length=1
          operation=DiagnosticInfo/GetMonitorStatus, queue-length=1
      EventInfo_ECUM_E_CONFIGURATION_DATA_INCONSISTENT: provided-interface=DiagnosticInfo  # This port provides the Supervision interface of ECUM_E_CONFIGURATION_DATA_INCONSISTENT to a SWC.
        provided-com-specs:
          operation=DiagnosticInfo/GetDTCOfEvent, queue-length=1
          operation=DiagnosticInfo/GetDebouncingOfEvent, queue-length=1
          operation=GetEventExtendedDataRecordEx, queue-length=1
          operation=GetEventFreezeFrameDataEx, queue-length=1
          operation=DiagnosticInfo/GetEventUdsStatus, queue-length=1
          operation=DiagnosticInfo/GetFaultDetectionCounter, queue-length=1
          operation=DiagnosticInfo/GetMonitorStatus, queue-length=1
      EventInfo_ECUM_E_IMPROPER_CALLER: provided-interface=DiagnosticInfo  # This port provides the Supervision interface of ECUM_E_IMPROPER_CALLER to a SWC.
        provided-com-specs:
          operation=DiagnosticInfo/GetDTCOfEvent, queue-length=1
          operation=DiagnosticInfo/GetDebouncingOfEvent, queue-length=1
          operation=GetEventExtendedDataRecordEx, queue-length=1
          operation=GetEventFreezeFrameDataEx, queue-length=1
          operation=DiagnosticInfo/GetEventUdsStatus, queue-length=1
          operation=DiagnosticInfo/GetFaultDetectionCounter, queue-length=1
          operation=DiagnosticInfo/GetMonitorStatus, queue-length=1
      EventInfo_ECUM_E_RAM_CHECK_FAILED: provided-interface=DiagnosticInfo  # This port provides the Supervision interface of ECUM_E_RAM_CHECK_FAILED to a SWC.
        provided-com-specs:
          operation=DiagnosticInfo/GetDTCOfEvent, queue-length=1
          operation=DiagnosticInfo/GetDebouncingOfEvent, queue-length=1
          operation=GetEventExtendedDataRecordEx, queue-length=1
          operation=GetEventFreezeFrameDataEx, queue-length=1
          operation=DiagnosticInfo/GetEventUdsStatus, queue-length=1
          operation=DiagnosticInfo/GetFaultDetectionCounter, queue-length=1
          operation=DiagnosticInfo/GetMonitorStatus, queue-length=1
      EventInfo_EEP_E_COMPARE_FAILED: provided-interface=DiagnosticInfo  # This port provides the Supervision interface of EEP_E_COMPARE_FAILED to a SWC.
        provided-com-specs:
          operation=DiagnosticInfo/GetDTCOfEvent, queue-length=1
          operation=DiagnosticInfo/GetDebouncingOfEvent, queue-length=1
          operation=GetEventExtendedDataRecordEx, queue-length=1
          operation=GetEventFreezeFrameDataEx, queue-length=1
          operation=DiagnosticInfo/GetEventUdsStatus, queue-length=1
          operation=DiagnosticInfo/GetFaultDetectionCounter, queue-length=1
          operation=DiagnosticInfo/GetMonitorStatus, queue-length=1
      EventInfo_EEP_E_ERASE_FAILED: provided-interface=DiagnosticInfo  # This port provides the Supervision interface of EEP_E_ERASE_FAILED to a SWC.
        provided-com-specs:
          operation=DiagnosticInfo/GetDTCOfEvent, queue-length=1
          operation=DiagnosticInfo/GetDebouncingOfEvent, queue-length=1
          operation=GetEventExtendedDataRecordEx, queue-length=1
          operation=GetEventFreezeFrameDataEx, queue-length=1
          operation=DiagnosticInfo/GetEventUdsStatus, queue-length=1
          operation=DiagnosticInfo/GetFaultDetectionCounter, queue-length=1
          operation=DiagnosticInfo/GetMonitorStatus, queue-length=1
      EventInfo_EEP_E_READ_FAILED: provided-interface=DiagnosticInfo  # This port provides the Supervision interface of EEP_E_READ_FAILED to a SWC.
        provided-com-specs:
          operation=DiagnosticInfo/GetDTCOfEvent, queue-length=1
          operation=DiagnosticInfo/GetDebouncingOfEvent, queue-length=1
          operation=GetEventExtendedDataRecordEx, queue-length=1
          operation=GetEventFreezeFrameDataEx, queue-length=1
          operation=DiagnosticInfo/GetEventUdsStatus, queue-length=1
          operation=DiagnosticInfo/GetFaultDetectionCounter, queue-length=1
          operation=DiagnosticInfo/GetMonitorStatus, queue-length=1
      EventInfo_EEP_E_WRITE_FAILED: provided-interface=DiagnosticInfo  # This port provides the Supervision interface of EEP_E_WRITE_FAILED to a SWC.
        provided-com-specs:
          operation=DiagnosticInfo/GetDTCOfEvent, queue-length=1
          operation=DiagnosticInfo/GetDebouncingOfEvent, queue-length=1
          operation=GetEventExtendedDataRecordEx, queue-length=1
          operation=GetEventFreezeFrameDataEx, queue-length=1
          operation=DiagnosticInfo/GetEventUdsStatus, queue-length=1
          operation=DiagnosticInfo/GetFaultDetectionCounter, queue-length=1
          operation=DiagnosticInfo/GetMonitorStatus, queue-length=1
      EventInfo_ETHSM_E_LINK_DOWN: provided-interface=DiagnosticInfo  # This port provides the Supervision interface of ETHSM_E_LINK_DOWN to a SWC.
        provided-com-specs:
          operation=DiagnosticInfo/GetDTCOfEvent, queue-length=1
          operation=DiagnosticInfo/GetDebouncingOfEvent, queue-length=1
          operation=GetEventExtendedDataRecordEx, queue-length=1
          operation=GetEventFreezeFrameDataEx, queue-length=1
          operation=DiagnosticInfo/GetEventUdsStatus, queue-length=1
          operation=DiagnosticInfo/GetFaultDetectionCounter, queue-length=1
          operation=DiagnosticInfo/GetMonitorStatus, queue-length=1
      EventInfo_ETHTRCV_E_ACCESS: provided-interface=DiagnosticInfo  # This port provides the Supervision interface of ETHTRCV_E_ACCESS to a SWC.
        provided-com-specs:
          operation=DiagnosticInfo/GetDTCOfEvent, queue-length=1
          operation=DiagnosticInfo/GetDebouncingOfEvent, queue-length=1
          operation=GetEventExtendedDataRecordEx, queue-length=1
          operation=GetEventFreezeFrameDataEx, queue-length=1
          operation=DiagnosticInfo/GetEventUdsStatus, queue-length=1
          operation=DiagnosticInfo/GetFaultDetectionCounter, queue-length=1
          operation=DiagnosticInfo/GetMonitorStatus, queue-length=1
      EventInfo_ETH_E_ACCESS: provided-interface=DiagnosticInfo  # This port provides the Supervision interface of ETH_E_ACCESS to a SWC.
        provided-com-specs:
          operation=DiagnosticInfo/GetDTCOfEvent, queue-length=1
          operation=DiagnosticInfo/GetDebouncingOfEvent, queue-length=1
          operation=GetEventExtendedDataRecordEx, queue-length=1
          operation=GetEventFreezeFrameDataEx, queue-length=1
          operation=DiagnosticInfo/GetEventUdsStatus, queue-length=1
          operation=DiagnosticInfo/GetFaultDetectionCounter, queue-length=1
          operation=DiagnosticInfo/GetMonitorStatus, queue-length=1
      EventInfo_ETH_E_ALIGNMENT: provided-interface=DiagnosticInfo  # This port provides the Supervision interface of ETH_E_ALIGNMENT to a SWC.
        provided-com-specs:
          operation=DiagnosticInfo/GetDTCOfEvent, queue-length=1
          operation=DiagnosticInfo/GetDebouncingOfEvent, queue-length=1
          operation=GetEventExtendedDataRecordEx, queue-length=1
          operation=GetEventFreezeFrameDataEx, queue-length=1
          operation=DiagnosticInfo/GetEventUdsStatus, queue-length=1
          operation=DiagnosticInfo/GetFaultDetectionCounter, queue-length=1
          operation=DiagnosticInfo/GetMonitorStatus, queue-length=1
      EventInfo_ETH_E_CRC: provided-interface=DiagnosticInfo  # This port provides the Supervision interface of ETH_E_CRC to a SWC.
        provided-com-specs:
          operation=DiagnosticInfo/GetDTCOfEvent, queue-length=1
          operation=DiagnosticInfo/GetDebouncingOfEvent, queue-length=1
          operation=GetEventExtendedDataRecordEx, queue-length=1
          operation=GetEventFreezeFrameDataEx, queue-length=1
          operation=DiagnosticInfo/GetEventUdsStatus, queue-length=1
          operation=DiagnosticInfo/GetFaultDetectionCounter, queue-length=1
          operation=DiagnosticInfo/GetMonitorStatus, queue-length=1
      EventInfo_ETH_E_LATECOLLISON: provided-interface=DiagnosticInfo  # This port provides the Supervision interface of ETH_E_LATECOLLISON to a SWC.
        provided-com-specs:
          operation=DiagnosticInfo/GetDTCOfEvent, queue-length=1
          operation=DiagnosticInfo/GetDebouncingOfEvent, queue-length=1
          operation=GetEventExtendedDataRecordEx, queue-length=1
          operation=GetEventFreezeFrameDataEx, queue-length=1
          operation=DiagnosticInfo/GetEventUdsStatus, queue-length=1
          operation=DiagnosticInfo/GetFaultDetectionCounter, queue-length=1
          operation=DiagnosticInfo/GetMonitorStatus, queue-length=1
      EventInfo_ETH_E_MULTIPLECOLLISION: provided-interface=DiagnosticInfo  # This port provides the Supervision interface of ETH_E_MULTIPLECOLLISION to a SWC.
        provided-com-specs:
          operation=DiagnosticInfo/GetDTCOfEvent, queue-length=1
          operation=DiagnosticInfo/GetDebouncingOfEvent, queue-length=1
          operation=GetEventExtendedDataRecordEx, queue-length=1
          operation=GetEventFreezeFrameDataEx, queue-length=1
          operation=DiagnosticInfo/GetEventUdsStatus, queue-length=1
          operation=DiagnosticInfo/GetFaultDetectionCounter, queue-length=1
          operation=DiagnosticInfo/GetMonitorStatus, queue-length=1
      EventInfo_ETH_E_OVERSIZEFRAME: provided-interface=DiagnosticInfo  # This port provides the Supervision interface of ETH_E_OVERSIZEFRAME to a SWC.
        provided-com-specs:
          operation=DiagnosticInfo/GetDTCOfEvent, queue-length=1
          operation=DiagnosticInfo/GetDebouncingOfEvent, queue-length=1
          operation=GetEventExtendedDataRecordEx, queue-length=1
          operation=GetEventFreezeFrameDataEx, queue-length=1
          operation=DiagnosticInfo/GetEventUdsStatus, queue-length=1
          operation=DiagnosticInfo/GetFaultDetectionCounter, queue-length=1
          operation=DiagnosticInfo/GetMonitorStatus, queue-length=1
      EventInfo_ETH_E_RX_FRAMES_LOST: provided-interface=DiagnosticInfo  # This port provides the Supervision interface of ETH_E_RX_FRAMES_LOST to a SWC.
        provided-com-specs:
          operation=DiagnosticInfo/GetDTCOfEvent, queue-length=1
          operation=DiagnosticInfo/GetDebouncingOfEvent, queue-length=1
          operation=GetEventExtendedDataRecordEx, queue-length=1
          operation=GetEventFreezeFrameDataEx, queue-length=1
          operation=DiagnosticInfo/GetEventUdsStatus, queue-length=1
          operation=DiagnosticInfo/GetFaultDetectionCounter, queue-length=1
          operation=DiagnosticInfo/GetMonitorStatus, queue-length=1
      EventInfo_ETH_E_SINGLECOLLISION: provided-interface=DiagnosticInfo  # This port provides the Supervision interface of ETH_E_SINGLECOLLISION to a SWC.
        provided-com-specs:
          operation=DiagnosticInfo/GetDTCOfEvent, queue-length=1
          operation=DiagnosticInfo/GetDebouncingOfEvent, queue-length=1
          operation=GetEventExtendedDataRecordEx, queue-length=1
          operation=GetEventFreezeFrameDataEx, queue-length=1
          operation=DiagnosticInfo/GetEventUdsStatus, queue-length=1
          operation=DiagnosticInfo/GetFaultDetectionCounter, queue-length=1
          operation=DiagnosticInfo/GetMonitorStatus, queue-length=1
      EventInfo_ETH_E_UNDERSIZRFRAME: provided-interface=DiagnosticInfo  # This port provides the Supervision interface of ETH_E_UNDERSIZRFRAME to a SWC.
        provided-com-specs:
          operation=DiagnosticInfo/GetDTCOfEvent, queue-length=1
          operation=DiagnosticInfo/GetDebouncingOfEvent, queue-length=1
          operation=GetEventExtendedDataRecordEx, queue-length=1
          operation=GetEventFreezeFrameDataEx, queue-length=1
          operation=DiagnosticInfo/GetEventUdsStatus, queue-length=1
          operation=DiagnosticInfo/GetFaultDetectionCounter, queue-length=1
          operation=DiagnosticInfo/GetMonitorStatus, queue-length=1
      EventInfo_FEE_E_GC_ERASE: provided-interface=DiagnosticInfo  # This port provides the Supervision interface of FEE_E_GC_ERASE to a SWC.
        provided-com-specs:
          operation=DiagnosticInfo/GetDTCOfEvent, queue-length=1
          operation=DiagnosticInfo/GetDebouncingOfEvent, queue-length=1
          operation=GetEventExtendedDataRecordEx, queue-length=1
          operation=GetEventFreezeFrameDataEx, queue-length=1
          operation=DiagnosticInfo/GetEventUdsStatus, queue-length=1
          operation=DiagnosticInfo/GetFaultDetectionCounter, queue-length=1
          operation=DiagnosticInfo/GetMonitorStatus, queue-length=1
      EventInfo_FEE_E_GC_INIT: provided-interface=DiagnosticInfo  # This port provides the Supervision interface of FEE_E_GC_INIT to a SWC.
        provided-com-specs:
          operation=DiagnosticInfo/GetDTCOfEvent, queue-length=1
          operation=DiagnosticInfo/GetDebouncingOfEvent, queue-length=1
          operation=GetEventExtendedDataRecordEx, queue-length=1
          operation=GetEventFreezeFrameDataEx, queue-length=1
          operation=DiagnosticInfo/GetEventUdsStatus, queue-length=1
          operation=DiagnosticInfo/GetFaultDetectionCounter, queue-length=1
          operation=DiagnosticInfo/GetMonitorStatus, queue-length=1
      EventInfo_FEE_E_GC_READ: provided-interface=DiagnosticInfo  # This port provides the Supervision interface of FEE_E_GC_READ to a SWC.
        provided-com-specs:
          operation=DiagnosticInfo/GetDTCOfEvent, queue-length=1
          operation=DiagnosticInfo/GetDebouncingOfEvent, queue-length=1
          operation=GetEventExtendedDataRecordEx, queue-length=1
          operation=GetEventFreezeFrameDataEx, queue-length=1
          operation=DiagnosticInfo/GetEventUdsStatus, queue-length=1
          operation=DiagnosticInfo/GetFaultDetectionCounter, queue-length=1
          operation=DiagnosticInfo/GetMonitorStatus, queue-length=1
      EventInfo_FEE_E_GC_TRIG: provided-interface=DiagnosticInfo  # This port provides the Supervision interface of FEE_E_GC_TRIG to a SWC.
        provided-com-specs:
          operation=DiagnosticInfo/GetDTCOfEvent, queue-length=1
          operation=DiagnosticInfo/GetDebouncingOfEvent, queue-length=1
          operation=GetEventExtendedDataRecordEx, queue-length=1
          operation=GetEventFreezeFrameDataEx, queue-length=1
          operation=DiagnosticInfo/GetEventUdsStatus, queue-length=1
          operation=DiagnosticInfo/GetFaultDetectionCounter, queue-length=1
          operation=DiagnosticInfo/GetMonitorStatus, queue-length=1
      EventInfo_FEE_E_GC_WRITE: provided-interface=DiagnosticInfo  # This port provides the Supervision interface of FEE_E_GC_WRITE to a SWC.
        provided-com-specs:
          operation=DiagnosticInfo/GetDTCOfEvent, queue-length=1
          operation=DiagnosticInfo/GetDebouncingOfEvent, queue-length=1
          operation=GetEventExtendedDataRecordEx, queue-length=1
          operation=GetEventFreezeFrameDataEx, queue-length=1
          operation=DiagnosticInfo/GetEventUdsStatus, queue-length=1
          operation=DiagnosticInfo/GetFaultDetectionCounter, queue-length=1
          operation=DiagnosticInfo/GetMonitorStatus, queue-length=1
      EventInfo_FEE_E_INVALIDATE: provided-interface=DiagnosticInfo  # This port provides the Supervision interface of FEE_E_INVALIDATE to a SWC.
        provided-com-specs:
          operation=DiagnosticInfo/GetDTCOfEvent, queue-length=1
          operation=DiagnosticInfo/GetDebouncingOfEvent, queue-length=1
          operation=GetEventExtendedDataRecordEx, queue-length=1
          operation=GetEventFreezeFrameDataEx, queue-length=1
          operation=DiagnosticInfo/GetEventUdsStatus, queue-length=1
          operation=DiagnosticInfo/GetFaultDetectionCounter, queue-length=1
          operation=DiagnosticInfo/GetMonitorStatus, queue-length=1
      EventInfo_FEE_E_READ: provided-interface=DiagnosticInfo  # This port provides the Supervision interface of FEE_E_READ to a SWC.
        provided-com-specs:
          operation=DiagnosticInfo/GetDTCOfEvent, queue-length=1
          operation=DiagnosticInfo/GetDebouncingOfEvent, queue-length=1
          operation=GetEventExtendedDataRecordEx, queue-length=1
          operation=GetEventFreezeFrameDataEx, queue-length=1
          operation=DiagnosticInfo/GetEventUdsStatus, queue-length=1
          operation=DiagnosticInfo/GetFaultDetectionCounter, queue-length=1
          operation=DiagnosticInfo/GetMonitorStatus, queue-length=1
      EventInfo_FEE_E_UNCONFIG_BLK_EXCEEDED: provided-interface=DiagnosticInfo  # This port provides the Supervision interface of FEE_E_UNCONFIG_BLK_EXCEEDED to a SWC.
        provided-com-specs:
          operation=DiagnosticInfo/GetDTCOfEvent, queue-length=1
          operation=DiagnosticInfo/GetDebouncingOfEvent, queue-length=1
          operation=GetEventExtendedDataRecordEx, queue-length=1
          operation=GetEventFreezeFrameDataEx, queue-length=1
          operation=DiagnosticInfo/GetEventUdsStatus, queue-length=1
          operation=DiagnosticInfo/GetFaultDetectionCounter, queue-length=1
          operation=DiagnosticInfo/GetMonitorStatus, queue-length=1
      EventInfo_FEE_E_WRITE: provided-interface=DiagnosticInfo  # This port provides the Supervision interface of FEE_E_WRITE to a SWC.
        provided-com-specs:
          operation=DiagnosticInfo/GetDTCOfEvent, queue-length=1
          operation=DiagnosticInfo/GetDebouncingOfEvent, queue-length=1
          operation=GetEventExtendedDataRecordEx, queue-length=1
          operation=GetEventFreezeFrameDataEx, queue-length=1
          operation=DiagnosticInfo/GetEventUdsStatus, queue-length=1
          operation=DiagnosticInfo/GetFaultDetectionCounter, queue-length=1
          operation=DiagnosticInfo/GetMonitorStatus, queue-length=1
      EventInfo_FEE_E_WRITE_CYCLES_EXHAUSTED: provided-interface=DiagnosticInfo  # This port provides the Supervision interface of FEE_E_WRITE_CYCLES_EXHAUSTED to a SWC.
        provided-com-specs:
          operation=DiagnosticInfo/GetDTCOfEvent, queue-length=1
          operation=DiagnosticInfo/GetDebouncingOfEvent, queue-length=1
          operation=GetEventExtendedDataRecordEx, queue-length=1
          operation=GetEventFreezeFrameDataEx, queue-length=1
          operation=DiagnosticInfo/GetEventUdsStatus, queue-length=1
          operation=DiagnosticInfo/GetFaultDetectionCounter, queue-length=1
          operation=DiagnosticInfo/GetMonitorStatus, queue-length=1
      EventInfo_FLS_E_COMPARE_FAILED: provided-interface=DiagnosticInfo  # This port provides the Supervision interface of FLS_E_COMPARE_FAILED to a SWC.
        provided-com-specs:
          operation=DiagnosticInfo/GetDTCOfEvent, queue-length=1
          operation=DiagnosticInfo/GetDebouncingOfEvent, queue-length=1
          operation=GetEventExtendedDataRecordEx, queue-length=1
          operation=GetEventFreezeFrameDataEx, queue-length=1
          operation=DiagnosticInfo/GetEventUdsStatus, queue-length=1
          operation=DiagnosticInfo/GetFaultDetectionCounter, queue-length=1
          operation=DiagnosticInfo/GetMonitorStatus, queue-length=1
      EventInfo_FLS_E_ERASE_FAILED: provided-interface=DiagnosticInfo  # This port provides the Supervision interface of FLS_E_ERASE_FAILED to a SWC.
        provided-com-specs:
          operation=DiagnosticInfo/GetDTCOfEvent, queue-length=1
          operation=DiagnosticInfo/GetDebouncingOfEvent, queue-length=1
          operation=GetEventExtendedDataRecordEx, queue-length=1
          operation=GetEventFreezeFrameDataEx, queue-length=1
          operation=DiagnosticInfo/GetEventUdsStatus, queue-length=1
          operation=DiagnosticInfo/GetFaultDetectionCounter, queue-length=1
          operation=DiagnosticInfo/GetMonitorStatus, queue-length=1
      EventInfo_FLS_E_READ_FAILED: provided-interface=DiagnosticInfo  # This port provides the Supervision interface of FLS_E_READ_FAILED to a SWC.
        provided-com-specs:
          operation=DiagnosticInfo/GetDTCOfEvent, queue-length=1
          operation=DiagnosticInfo/GetDebouncingOfEvent, queue-length=1
          operation=GetEventExtendedDataRecordEx, queue-length=1
          operation=GetEventFreezeFrameDataEx, queue-length=1
          operation=DiagnosticInfo/GetEventUdsStatus, queue-length=1
          operation=DiagnosticInfo/GetFaultDetectionCounter, queue-length=1
          operation=DiagnosticInfo/GetMonitorStatus, queue-length=1
      EventInfo_FLS_E_UNEXPECTED_FLASH_ID: provided-interface=DiagnosticInfo  # This port provides the Supervision interface of FLS_E_UNEXPECTED_FLASH_ID to a SWC.
        provided-com-specs:
          operation=DiagnosticInfo/GetDTCOfEvent, queue-length=1
          operation=DiagnosticInfo/GetDebouncingOfEvent, queue-length=1
          operation=GetEventExtendedDataRecordEx, queue-length=1
          operation=GetEventFreezeFrameDataEx, queue-length=1
          operation=DiagnosticInfo/GetEventUdsStatus, queue-length=1
          operation=DiagnosticInfo/GetFaultDetectionCounter, queue-length=1
          operation=DiagnosticInfo/GetMonitorStatus, queue-length=1
      EventInfo_FLS_E_WRITE_FAILED: provided-interface=DiagnosticInfo  # This port provides the Supervision interface of FLS_E_WRITE_FAILED to a SWC.
        provided-com-specs:
          operation=DiagnosticInfo/GetDTCOfEvent, queue-length=1
          operation=DiagnosticInfo/GetDebouncingOfEvent, queue-length=1
          operation=GetEventExtendedDataRecordEx, queue-length=1
          operation=GetEventFreezeFrameDataEx, queue-length=1
          operation=DiagnosticInfo/GetEventUdsStatus, queue-length=1
          operation=DiagnosticInfo/GetFaultDetectionCounter, queue-length=1
          operation=DiagnosticInfo/GetMonitorStatus, queue-length=1
      EventInfo_IOHWAB_E_BUSY: provided-interface=DiagnosticInfo  # This port provides the Supervision interface of IOHWAB_E_BUSY to a SWC.
        provided-com-specs:
          operation=DiagnosticInfo/GetDTCOfEvent, queue-length=1
          operation=DiagnosticInfo/GetDebouncingOfEvent, queue-length=1
          operation=GetEventExtendedDataRecordEx, queue-length=1
          operation=GetEventFreezeFrameDataEx, queue-length=1
          operation=DiagnosticInfo/GetEventUdsStatus, queue-length=1
          operation=DiagnosticInfo/GetFaultDetectionCounter, queue-length=1
          operation=DiagnosticInfo/GetMonitorStatus, queue-length=1
      EventInfo_IOHWAB_E_PROC_FAIL: provided-interface=DiagnosticInfo  # This port provides the Supervision interface of IOHWAB_E_PROC_FAIL to a SWC.
        provided-com-specs:
          operation=DiagnosticInfo/GetDTCOfEvent, queue-length=1
          operation=DiagnosticInfo/GetDebouncingOfEvent, queue-length=1
          operation=GetEventExtendedDataRecordEx, queue-length=1
          operation=GetEventFreezeFrameDataEx, queue-length=1
          operation=DiagnosticInfo/GetEventUdsStatus, queue-length=1
          operation=DiagnosticInfo/GetFaultDetectionCounter, queue-length=1
          operation=DiagnosticInfo/GetMonitorStatus, queue-length=1
      EventInfo_IOHWAB_E_SETUP_FAIL: provided-interface=DiagnosticInfo  # This port provides the Supervision interface of IOHWAB_E_SETUP_FAIL to a SWC.
        provided-com-specs:
          operation=DiagnosticInfo/GetDTCOfEvent, queue-length=1
          operation=DiagnosticInfo/GetDebouncingOfEvent, queue-length=1
          operation=GetEventExtendedDataRecordEx, queue-length=1
          operation=GetEventFreezeFrameDataEx, queue-length=1
          operation=DiagnosticInfo/GetEventUdsStatus, queue-length=1
          operation=DiagnosticInfo/GetFaultDetectionCounter, queue-length=1
          operation=DiagnosticInfo/GetMonitorStatus, queue-length=1
      EventInfo_IOHWAB_E_WRONG_PARAM: provided-interface=DiagnosticInfo  # This port provides the Supervision interface of IOHWAB_E_WRONG_PARAM to a SWC.
        provided-com-specs:
          operation=DiagnosticInfo/GetDTCOfEvent, queue-length=1
          operation=DiagnosticInfo/GetDebouncingOfEvent, queue-length=1
          operation=GetEventExtendedDataRecordEx, queue-length=1
          operation=GetEventFreezeFrameDataEx, queue-length=1
          operation=DiagnosticInfo/GetEventUdsStatus, queue-length=1
          operation=DiagnosticInfo/GetFaultDetectionCounter, queue-length=1
          operation=DiagnosticInfo/GetMonitorStatus, queue-length=1
      EventInfo_IOHWAB_E_WRONG_SETTING: provided-interface=DiagnosticInfo  # This port provides the Supervision interface of IOHWAB_E_WRONG_SETTING to a SWC.
        provided-com-specs:
          operation=DiagnosticInfo/GetDTCOfEvent, queue-length=1
          operation=DiagnosticInfo/GetDebouncingOfEvent, queue-length=1
          operation=GetEventExtendedDataRecordEx, queue-length=1
          operation=GetEventFreezeFrameDataEx, queue-length=1
          operation=DiagnosticInfo/GetEventUdsStatus, queue-length=1
          operation=DiagnosticInfo/GetFaultDetectionCounter, queue-length=1
          operation=DiagnosticInfo/GetMonitorStatus, queue-length=1
      EventInfo_IOHWAB_E_WRONG_STATE: provided-interface=DiagnosticInfo  # This port provides the Supervision interface of IOHWAB_E_WRONG_STATE to a SWC.
        provided-com-specs:
          operation=DiagnosticInfo/GetDTCOfEvent, queue-length=1
          operation=DiagnosticInfo/GetDebouncingOfEvent, queue-length=1
          operation=GetEventExtendedDataRecordEx, queue-length=1
          operation=GetEventFreezeFrameDataEx, queue-length=1
          operation=DiagnosticInfo/GetEventUdsStatus, queue-length=1
          operation=DiagnosticInfo/GetFaultDetectionCounter, queue-length=1
          operation=DiagnosticInfo/GetMonitorStatus, queue-length=1
      EventInfo_MCU_E_CCU6_CLC_DISABLE_ERR: provided-interface=DiagnosticInfo  # This port provides the Supervision interface of MCU_E_CCU6_CLC_DISABLE_ERR to a SWC.
        provided-com-specs:
          operation=DiagnosticInfo/GetDTCOfEvent, queue-length=1
          operation=DiagnosticInfo/GetDebouncingOfEvent, queue-length=1
          operation=GetEventExtendedDataRecordEx, queue-length=1
          operation=GetEventFreezeFrameDataEx, queue-length=1
          operation=DiagnosticInfo/GetEventUdsStatus, queue-length=1
          operation=DiagnosticInfo/GetFaultDetectionCounter, queue-length=1
          operation=DiagnosticInfo/GetMonitorStatus, queue-length=1
      EventInfo_MCU_E_CCU6_CLC_ENABLE_ERR: provided-interface=DiagnosticInfo  # This port provides the Supervision interface of MCU_E_CCU6_CLC_ENABLE_ERR to a SWC.
        provided-com-specs:
          operation=DiagnosticInfo/GetDTCOfEvent, queue-length=1
          operation=DiagnosticInfo/GetDebouncingOfEvent, queue-length=1
          operation=GetEventExtendedDataRecordEx, queue-length=1
          operation=GetEventFreezeFrameDataEx, queue-length=1
          operation=DiagnosticInfo/GetEventUdsStatus, queue-length=1
          operation=DiagnosticInfo/GetFaultDetectionCounter, queue-length=1
          operation=DiagnosticInfo/GetMonitorStatus, queue-length=1
      EventInfo_MCU_E_CCUCON_UPDATE_ERR: provided-interface=DiagnosticInfo  # This port provides the Supervision interface of MCU_E_CCUCON_UPDATE_ERR to a SWC.
        provided-com-specs:
          operation=DiagnosticInfo/GetDTCOfEvent, queue-length=1
          operation=DiagnosticInfo/GetDebouncingOfEvent, queue-length=1
          operation=GetEventExtendedDataRecordEx, queue-length=1
          operation=GetEventFreezeFrameDataEx, queue-length=1
          operation=DiagnosticInfo/GetEventUdsStatus, queue-length=1
          operation=DiagnosticInfo/GetFaultDetectionCounter, queue-length=1
          operation=DiagnosticInfo/GetMonitorStatus, queue-length=1
      EventInfo_MCU_E_CLOCK_FAILURE: provided-interface=DiagnosticInfo  # This port provides the Supervision interface of MCU_E_CLOCK_FAILURE to a SWC.
        provided-com-specs:
          operation=DiagnosticInfo/GetDTCOfEvent, queue-length=1
          operation=DiagnosticInfo/GetDebouncingOfEvent, queue-length=1
          operation=GetEventExtendedDataRecordEx, queue-length=1
          operation=GetEventFreezeFrameDataEx, queue-length=1
          operation=DiagnosticInfo/GetEventUdsStatus, queue-length=1
          operation=DiagnosticInfo/GetFaultDetectionCounter, queue-length=1
          operation=DiagnosticInfo/GetMonitorStatus, queue-length=1
      EventInfo_MCU_E_CONVCTRL_CLC_DISABLE_ERR: provided-interface=DiagnosticInfo  # This port provides the Supervision interface of MCU_E_CONVCTRL_CLC_DISABLE_ERR to a SWC.
        provided-com-specs:
          operation=DiagnosticInfo/GetDTCOfEvent, queue-length=1
          operation=DiagnosticInfo/GetDebouncingOfEvent, queue-length=1
          operation=GetEventExtendedDataRecordEx, queue-length=1
          operation=GetEventFreezeFrameDataEx, queue-length=1
          operation=DiagnosticInfo/GetEventUdsStatus, queue-length=1
          operation=DiagnosticInfo/GetFaultDetectionCounter, queue-length=1
          operation=DiagnosticInfo/GetMonitorStatus, queue-length=1
      EventInfo_MCU_E_CONVCTRL_CLC_ENABLE_ERR: provided-interface=DiagnosticInfo  # This port provides the Supervision interface of MCU_E_CONVCTRL_CLC_ENABLE_ERR to a SWC.
        provided-com-specs:
          operation=DiagnosticInfo/GetDTCOfEvent, queue-length=1
          operation=DiagnosticInfo/GetDebouncingOfEvent, queue-length=1
          operation=GetEventExtendedDataRecordEx, queue-length=1
          operation=GetEventFreezeFrameDataEx, queue-length=1
          operation=DiagnosticInfo/GetEventUdsStatus, queue-length=1
          operation=DiagnosticInfo/GetFaultDetectionCounter, queue-length=1
          operation=DiagnosticInfo/GetMonitorStatus, queue-length=1
      EventInfo_MCU_E_GPT12_CLC_DISABLE_ERR: provided-interface=DiagnosticInfo  # This port provides the Supervision interface of MCU_E_GPT12_CLC_DISABLE_ERR to a SWC.
        provided-com-specs:
          operation=DiagnosticInfo/GetDTCOfEvent, queue-length=1
          operation=DiagnosticInfo/GetDebouncingOfEvent, queue-length=1
          operation=GetEventExtendedDataRecordEx, queue-length=1
          operation=GetEventFreezeFrameDataEx, queue-length=1
          operation=DiagnosticInfo/GetEventUdsStatus, queue-length=1
          operation=DiagnosticInfo/GetFaultDetectionCounter, queue-length=1
          operation=DiagnosticInfo/GetMonitorStatus, queue-length=1
      EventInfo_MCU_E_GPT12_CLC_ENABLE_ERR: provided-interface=DiagnosticInfo  # This port provides the Supervision interface of MCU_E_GPT12_CLC_ENABLE_ERR to a SWC.
        provided-com-specs:
          operation=DiagnosticInfo/GetDTCOfEvent, queue-length=1
          operation=DiagnosticInfo/GetDebouncingOfEvent, queue-length=1
          operation=GetEventExtendedDataRecordEx, queue-length=1
          operation=GetEventFreezeFrameDataEx, queue-length=1
          operation=DiagnosticInfo/GetEventUdsStatus, queue-length=1
          operation=DiagnosticInfo/GetFaultDetectionCounter, queue-length=1
          operation=DiagnosticInfo/GetMonitorStatus, queue-length=1
      EventInfo_MCU_E_GTM_CLC_DISABLE_ERR: provided-interface=DiagnosticInfo  # This port provides the Supervision interface of MCU_E_GTM_CLC_DISABLE_ERR to a SWC.
        provided-com-specs:
          operation=DiagnosticInfo/GetDTCOfEvent, queue-length=1
          operation=DiagnosticInfo/GetDebouncingOfEvent, queue-length=1
          operation=GetEventExtendedDataRecordEx, queue-length=1
          operation=GetEventFreezeFrameDataEx, queue-length=1
          operation=DiagnosticInfo/GetEventUdsStatus, queue-length=1
          operation=DiagnosticInfo/GetFaultDetectionCounter, queue-length=1
          operation=DiagnosticInfo/GetMonitorStatus, queue-length=1
      EventInfo_MCU_E_GTM_CLC_ENABLE_ERR: provided-interface=DiagnosticInfo  # This port provides the Supervision interface of MCU_E_GTM_CLC_ENABLE_ERR to a SWC.
        provided-com-specs:
          operation=DiagnosticInfo/GetDTCOfEvent, queue-length=1
          operation=DiagnosticInfo/GetDebouncingOfEvent, queue-length=1
          operation=GetEventExtendedDataRecordEx, queue-length=1
          operation=GetEventFreezeFrameDataEx, queue-length=1
          operation=DiagnosticInfo/GetEventUdsStatus, queue-length=1
          operation=DiagnosticInfo/GetFaultDetectionCounter, queue-length=1
          operation=DiagnosticInfo/GetMonitorStatus, queue-length=1
      EventInfo_MCU_E_OSC_FAILURE: provided-interface=DiagnosticInfo  # This port provides the Supervision interface of MCU_E_OSC_FAILURE to a SWC.
        provided-com-specs:
          operation=DiagnosticInfo/GetDTCOfEvent, queue-length=1
          operation=DiagnosticInfo/GetDebouncingOfEvent, queue-length=1
          operation=GetEventExtendedDataRecordEx, queue-length=1
          operation=GetEventFreezeFrameDataEx, queue-length=1
          operation=DiagnosticInfo/GetEventUdsStatus, queue-length=1
          operation=DiagnosticInfo/GetFaultDetectionCounter, queue-length=1
          operation=DiagnosticInfo/GetMonitorStatus, queue-length=1
      EventInfo_MCU_E_PERIPHERAL_PLL_LOCK_LOSS: provided-interface=DiagnosticInfo  # This port provides the Supervision interface of MCU_E_PERIPHERAL_PLL_LOCK_LOSS to a SWC.
        provided-com-specs:
          operation=DiagnosticInfo/GetDTCOfEvent, queue-length=1
          operation=DiagnosticInfo/GetDebouncingOfEvent, queue-length=1
          operation=GetEventExtendedDataRecordEx, queue-length=1
          operation=GetEventFreezeFrameDataEx, queue-length=1
          operation=DiagnosticInfo/GetEventUdsStatus, queue-length=1
          operation=DiagnosticInfo/GetFaultDetectionCounter, queue-length=1
          operation=DiagnosticInfo/GetMonitorStatus, queue-length=1
      EventInfo_MCU_E_PERIPHERAL_PLL_TIMEOUT_ERR: provided-interface=DiagnosticInfo  # This port provides the Supervision interface of MCU_E_PERIPHERAL_PLL_TIMEOUT_ERR to a SWC.
        provided-com-specs:
          operation=DiagnosticInfo/GetDTCOfEvent, queue-length=1
          operation=DiagnosticInfo/GetDebouncingOfEvent, queue-length=1
          operation=GetEventExtendedDataRecordEx, queue-length=1
          operation=GetEventFreezeFrameDataEx, queue-length=1
          operation=DiagnosticInfo/GetEventUdsStatus, queue-length=1
          operation=DiagnosticInfo/GetFaultDetectionCounter, queue-length=1
          operation=DiagnosticInfo/GetMonitorStatus, queue-length=1
      EventInfo_MCU_E_PMSWCR_UPDATE_ERR: provided-interface=DiagnosticInfo  # This port provides the Supervision interface of MCU_E_PMSWCR_UPDATE_ERR to a SWC.
        provided-com-specs:
          operation=DiagnosticInfo/GetDTCOfEvent, queue-length=1
          operation=DiagnosticInfo/GetDebouncingOfEvent, queue-length=1
          operation=GetEventExtendedDataRecordEx, queue-length=1
          operation=GetEventFreezeFrameDataEx, queue-length=1
          operation=DiagnosticInfo/GetEventUdsStatus, queue-length=1
          operation=DiagnosticInfo/GetFaultDetectionCounter, queue-length=1
          operation=DiagnosticInfo/GetMonitorStatus, queue-length=1
      EventInfo_MCU_E_SYSTEM_PLL_LOCK_LOSS: provided-interface=DiagnosticInfo  # This port provides the Supervision interface of MCU_E_SYSTEM_PLL_LOCK_LOSS to a SWC.
        provided-com-specs:
          operation=DiagnosticInfo/GetDTCOfEvent, queue-length=1
          operation=DiagnosticInfo/GetDebouncingOfEvent, queue-length=1
          operation=GetEventExtendedDataRecordEx, queue-length=1
          operation=GetEventFreezeFrameDataEx, queue-length=1
          operation=DiagnosticInfo/GetEventUdsStatus, queue-length=1
          operation=DiagnosticInfo/GetFaultDetectionCounter, queue-length=1
          operation=DiagnosticInfo/GetMonitorStatus, queue-length=1
      EventInfo_MCU_E_SYSTEM_PLL_TIMEOUT_ERR: provided-interface=DiagnosticInfo  # This port provides the Supervision interface of MCU_E_SYSTEM_PLL_TIMEOUT_ERR to a SWC.
        provided-com-specs:
          operation=DiagnosticInfo/GetDTCOfEvent, queue-length=1
          operation=DiagnosticInfo/GetDebouncingOfEvent, queue-length=1
          operation=GetEventExtendedDataRecordEx, queue-length=1
          operation=GetEventFreezeFrameDataEx, queue-length=1
          operation=DiagnosticInfo/GetEventUdsStatus, queue-length=1
          operation=DiagnosticInfo/GetFaultDetectionCounter, queue-length=1
          operation=DiagnosticInfo/GetMonitorStatus, queue-length=1
      EventInfo_NVM_E_INTEGRITY_FAILED: provided-interface=DiagnosticInfo  # This port provides the Supervision interface of NVM_E_INTEGRITY_FAILED to a SWC.
        provided-com-specs:
          operation=DiagnosticInfo/GetDTCOfEvent, queue-length=1
          operation=DiagnosticInfo/GetDebouncingOfEvent, queue-length=1
          operation=GetEventExtendedDataRecordEx, queue-length=1
          operation=GetEventFreezeFrameDataEx, queue-length=1
          operation=DiagnosticInfo/GetEventUdsStatus, queue-length=1
          operation=DiagnosticInfo/GetFaultDetectionCounter, queue-length=1
          operation=DiagnosticInfo/GetMonitorStatus, queue-length=1
      EventInfo_NVM_E_LOSS_OF_REDUNDANCY: provided-interface=DiagnosticInfo  # This port provides the Supervision interface of NVM_E_LOSS_OF_REDUNDANCY to a SWC.
        provided-com-specs:
          operation=DiagnosticInfo/GetDTCOfEvent, queue-length=1
          operation=DiagnosticInfo/GetDebouncingOfEvent, queue-length=1
          operation=GetEventExtendedDataRecordEx, queue-length=1
          operation=GetEventFreezeFrameDataEx, queue-length=1
          operation=DiagnosticInfo/GetEventUdsStatus, queue-length=1
          operation=DiagnosticInfo/GetFaultDetectionCounter, queue-length=1
          operation=DiagnosticInfo/GetMonitorStatus, queue-length=1
      EventInfo_NVM_E_QUEUE_OVERFLOW: provided-interface=DiagnosticInfo  # This port provides the Supervision interface of NVM_E_QUEUE_OVERFLOW to a SWC.
        provided-com-specs:
          operation=DiagnosticInfo/GetDTCOfEvent, queue-length=1
          operation=DiagnosticInfo/GetDebouncingOfEvent, queue-length=1
          operation=GetEventExtendedDataRecordEx, queue-length=1
          operation=GetEventFreezeFrameDataEx, queue-length=1
          operation=DiagnosticInfo/GetEventUdsStatus, queue-length=1
          operation=DiagnosticInfo/GetFaultDetectionCounter, queue-length=1
          operation=DiagnosticInfo/GetMonitorStatus, queue-length=1
      EventInfo_NVM_E_REQ_FAILED: provided-interface=DiagnosticInfo  # This port provides the Supervision interface of NVM_E_REQ_FAILED to a SWC.
        provided-com-specs:
          operation=DiagnosticInfo/GetDTCOfEvent, queue-length=1
          operation=DiagnosticInfo/GetDebouncingOfEvent, queue-length=1
          operation=GetEventExtendedDataRecordEx, queue-length=1
          operation=GetEventFreezeFrameDataEx, queue-length=1
          operation=DiagnosticInfo/GetEventUdsStatus, queue-length=1
          operation=DiagnosticInfo/GetFaultDetectionCounter, queue-length=1
          operation=DiagnosticInfo/GetMonitorStatus, queue-length=1
      EventInfo_NVM_E_VERIFY_FAILED: provided-interface=DiagnosticInfo  # This port provides the Supervision interface of NVM_E_VERIFY_FAILED to a SWC.
        provided-com-specs:
          operation=DiagnosticInfo/GetDTCOfEvent, queue-length=1
          operation=DiagnosticInfo/GetDebouncingOfEvent, queue-length=1
          operation=GetEventExtendedDataRecordEx, queue-length=1
          operation=GetEventFreezeFrameDataEx, queue-length=1
          operation=DiagnosticInfo/GetEventUdsStatus, queue-length=1
          operation=DiagnosticInfo/GetFaultDetectionCounter, queue-length=1
          operation=DiagnosticInfo/GetMonitorStatus, queue-length=1
      EventInfo_NVM_E_WRITE_PROTECTED: provided-interface=DiagnosticInfo  # This port provides the Supervision interface of NVM_E_WRITE_PROTECTED to a SWC.
        provided-com-specs:
          operation=DiagnosticInfo/GetDTCOfEvent, queue-length=1
          operation=DiagnosticInfo/GetDebouncingOfEvent, queue-length=1
          operation=GetEventExtendedDataRecordEx, queue-length=1
          operation=GetEventFreezeFrameDataEx, queue-length=1
          operation=DiagnosticInfo/GetEventUdsStatus, queue-length=1
          operation=DiagnosticInfo/GetFaultDetectionCounter, queue-length=1
          operation=DiagnosticInfo/GetMonitorStatus, queue-length=1
      EventInfo_NVM_E_WRONG_BLOCK_ID: provided-interface=DiagnosticInfo  # This port provides the Supervision interface of NVM_E_WRONG_BLOCK_ID to a SWC.
        provided-com-specs:
          operation=DiagnosticInfo/GetDTCOfEvent, queue-length=1
          operation=DiagnosticInfo/GetDebouncingOfEvent, queue-length=1
          operation=GetEventExtendedDataRecordEx, queue-length=1
          operation=GetEventFreezeFrameDataEx, queue-length=1
          operation=DiagnosticInfo/GetEventUdsStatus, queue-length=1
          operation=DiagnosticInfo/GetFaultDetectionCounter, queue-length=1
          operation=DiagnosticInfo/GetMonitorStatus, queue-length=1
      EventInfo_SPI_E_HARDWARE_ERROR: provided-interface=DiagnosticInfo  # This port provides the Supervision interface of SPI_E_HARDWARE_ERROR to a SWC.
        provided-com-specs:
          operation=DiagnosticInfo/GetDTCOfEvent, queue-length=1
          operation=DiagnosticInfo/GetDebouncingOfEvent, queue-length=1
          operation=GetEventExtendedDataRecordEx, queue-length=1
          operation=GetEventFreezeFrameDataEx, queue-length=1
          operation=DiagnosticInfo/GetEventUdsStatus, queue-length=1
          operation=DiagnosticInfo/GetFaultDetectionCounter, queue-length=1
          operation=DiagnosticInfo/GetMonitorStatus, queue-length=1
      EventInfo_WDGM_E_IMPROPER_CALLER: provided-interface=DiagnosticInfo  # This port provides the Supervision interface of WDGM_E_IMPROPER_CALLER to a SWC.
        provided-com-specs:
          operation=DiagnosticInfo/GetDTCOfEvent, queue-length=1
          operation=DiagnosticInfo/GetDebouncingOfEvent, queue-length=1
          operation=GetEventExtendedDataRecordEx, queue-length=1
          operation=GetEventFreezeFrameDataEx, queue-length=1
          operation=DiagnosticInfo/GetEventUdsStatus, queue-length=1
          operation=DiagnosticInfo/GetFaultDetectionCounter, queue-length=1
          operation=DiagnosticInfo/GetMonitorStatus, queue-length=1
      EventInfo_WDGM_E_MONITORING: provided-interface=DiagnosticInfo  # This port provides the Supervision interface of WDGM_E_MONITORING to a SWC.
        provided-com-specs:
          operation=DiagnosticInfo/GetDTCOfEvent, queue-length=1
          operation=DiagnosticInfo/GetDebouncingOfEvent, queue-length=1
          operation=GetEventExtendedDataRecordEx, queue-length=1
          operation=GetEventFreezeFrameDataEx, queue-length=1
          operation=DiagnosticInfo/GetEventUdsStatus, queue-length=1
          operation=DiagnosticInfo/GetFaultDetectionCounter, queue-length=1
          operation=DiagnosticInfo/GetMonitorStatus, queue-length=1
      EventInfo_WDGM_E_SET_MODE: provided-interface=DiagnosticInfo  # This port provides the Supervision interface of WDGM_E_SET_MODE to a SWC.
        provided-com-specs:
          operation=DiagnosticInfo/GetDTCOfEvent, queue-length=1
          operation=DiagnosticInfo/GetDebouncingOfEvent, queue-length=1
          operation=GetEventExtendedDataRecordEx, queue-length=1
          operation=GetEventFreezeFrameDataEx, queue-length=1
          operation=DiagnosticInfo/GetEventUdsStatus, queue-length=1
          operation=DiagnosticInfo/GetFaultDetectionCounter, queue-length=1
          operation=DiagnosticInfo/GetMonitorStatus, queue-length=1
      EventInfo_WDG_76_ACW_E_DISABLE_REJECTED: provided-interface=DiagnosticInfo  # This port provides the Supervision interface of WDG_76_ACW_E_DISABLE_REJECTED to a SWC.
        provided-com-specs:
          operation=DiagnosticInfo/GetDTCOfEvent, queue-length=1
          operation=DiagnosticInfo/GetDebouncingOfEvent, queue-length=1
          operation=GetEventExtendedDataRecordEx, queue-length=1
          operation=GetEventFreezeFrameDataEx, queue-length=1
          operation=DiagnosticInfo/GetEventUdsStatus, queue-length=1
          operation=DiagnosticInfo/GetFaultDetectionCounter, queue-length=1
          operation=DiagnosticInfo/GetMonitorStatus, queue-length=1
      EventInfo_WDG_76_ACW_E_MODE_FAILED: provided-interface=DiagnosticInfo  # This port provides the Supervision interface of WDG_76_ACW_E_MODE_FAILED to a SWC.
        provided-com-specs:
          operation=DiagnosticInfo/GetDTCOfEvent, queue-length=1
          operation=DiagnosticInfo/GetDebouncingOfEvent, queue-length=1
          operation=GetEventExtendedDataRecordEx, queue-length=1
          operation=GetEventFreezeFrameDataEx, queue-length=1
          operation=DiagnosticInfo/GetEventUdsStatus, queue-length=1
          operation=DiagnosticInfo/GetFaultDetectionCounter, queue-length=1
          operation=DiagnosticInfo/GetMonitorStatus, queue-length=1
      EventInfo_WDG_E_DISABLE_REJECTED: provided-interface=DiagnosticInfo  # This port provides the Supervision interface of WDG_E_DISABLE_REJECTED to a SWC.
        provided-com-specs:
          operation=DiagnosticInfo/GetDTCOfEvent, queue-length=1
          operation=DiagnosticInfo/GetDebouncingOfEvent, queue-length=1
          operation=GetEventExtendedDataRecordEx, queue-length=1
          operation=GetEventFreezeFrameDataEx, queue-length=1
          operation=DiagnosticInfo/GetEventUdsStatus, queue-length=1
          operation=DiagnosticInfo/GetFaultDetectionCounter, queue-length=1
          operation=DiagnosticInfo/GetMonitorStatus, queue-length=1
      EventInfo_WDG_E_MODE_FAILED: provided-interface=DiagnosticInfo  # This port provides the Supervision interface of WDG_E_MODE_FAILED to a SWC.
        provided-com-specs:
          operation=DiagnosticInfo/GetDTCOfEvent, queue-length=1
          operation=DiagnosticInfo/GetDebouncingOfEvent, queue-length=1
          operation=GetEventExtendedDataRecordEx, queue-length=1
          operation=GetEventFreezeFrameDataEx, queue-length=1
          operation=DiagnosticInfo/GetEventUdsStatus, queue-length=1
          operation=DiagnosticInfo/GetFaultDetectionCounter, queue-length=1
          operation=DiagnosticInfo/GetMonitorStatus, queue-length=1
      EventStatus_CANCM_E_BAT_FAIL: server-com-spec{operation=SetWIRStatus, queue-length=1}, provided-interface=EventStatus  # This port provides the Supervision interface of CANCM_E_BAT_FAIL to a SWC.
      EventStatus_CANSM_E_BUS_OFF_FD_CAN1: server-com-spec{operation=SetWIRStatus, queue-length=1}, provided-interface=EventStatus  # This port provides the Supervision interface of CANSM_E_BUS_OFF_FD_CAN1 to a SWC.
      EventStatus_CANSM_E_BUS_OFF_FD_CAN2: server-com-spec{operation=SetWIRStatus, queue-length=1}, provided-interface=EventStatus  # This port provides the Supervision interface of CANSM_E_BUS_OFF_FD_CAN2 to a SWC.
      EventStatus_CANSM_E_BUS_OFF_HS_CAN1: server-com-spec{operation=SetWIRStatus, queue-length=1}, provided-interface=EventStatus  # This port provides the Supervision interface of CANSM_E_BUS_OFF_HS_CAN1 to a SWC.
      EventStatus_CANSM_E_BUS_OFF_LS_CAN1: server-com-spec{operation=SetWIRStatus, queue-length=1}, provided-interface=EventStatus  # This port provides the Supervision interface of CANSM_E_BUS_OFF_LS_CAN1 to a SWC.
      EventStatus_CANSM_E_BUS_OFF_Project: server-com-spec{operation=SetWIRStatus, queue-length=1}, provided-interface=EventStatus  # This port provides the Supervision interface of CANSM_E_BUS_OFF_Project to a SWC.
      EventStatus_CANSM_E_MODE_CHANGE_FD_CAN1: server-com-spec{operation=SetWIRStatus, queue-length=1}, provided-interface=EventStatus  # This port provides the Supervision interface of CANSM_E_MODE_CHANGE_FD_CAN1 to a SWC.
      EventStatus_CANSM_E_MODE_CHANGE_FD_CAN2: server-com-spec{operation=SetWIRStatus, queue-length=1}, provided-interface=EventStatus  # This port provides the Supervision interface of CANSM_E_MODE_CHANGE_FD_CAN2 to a SWC.
      EventStatus_CANSM_E_MODE_CHANGE_HS_CAN1: server-com-spec{operation=SetWIRStatus, queue-length=1}, provided-interface=EventStatus  # This port provides the Supervision interface of CANSM_E_MODE_CHANGE_HS_CAN1 to a SWC.
      EventStatus_CANSM_E_MODE_CHANGE_LS_CAN1: server-com-spec{operation=SetWIRStatus, queue-length=1}, provided-interface=EventStatus  # This port provides the Supervision interface of CANSM_E_MODE_CHANGE_LS_CAN1 to a SWC.
      EventStatus_CANSM_E_MODE_CHANGE_Project: server-com-spec{operation=SetWIRStatus, queue-length=1}, provided-interface=EventStatus  # This port provides the Supervision interface of CANSM_E_MODE_CHANGE_Project to a SWC.
      EventStatus_CANSM_E_MODE_REQUEST_TIMEOUT_FD_CAN1: server-com-spec{operation=SetWIRStatus, queue-length=1}, provided-interface=EventStatus  # This port provides the Supervision interface of CANSM_E_MODE_REQUEST_TIMEOUT_FD_CAN1 to a SWC.
      EventStatus_CANSM_E_MODE_REQUEST_TIMEOUT_HS_CAN1: server-com-spec{operation=SetWIRStatus, queue-length=1}, provided-interface=EventStatus  # This port provides the Supervision interface of CANSM_E_MODE_REQUEST_TIMEOUT_HS_CAN1 to a SWC.
      EventStatus_DEM_E_TEST_EVENT1: server-com-spec{operation=SetWIRStatus, queue-length=1}, provided-interface=EventStatus  # This port provides the Supervision interface of DEM_E_TEST_EVENT1 to a SWC.
      EventStatus_DEM_E_TEST_EVENT{10..19}: server-com-spec{operation=SetWIRStatus, queue-length=1}, provided-interface=EventStatus  # This port provides the Supervision interface of DEM_E_TEST_EVENT{10..19} to a SWC.
      EventStatus_DEM_E_TEST_EVENT2: server-com-spec{operation=SetWIRStatus, queue-length=1}, provided-interface=EventStatus  # This port provides the Supervision interface of DEM_E_TEST_EVENT2 to a SWC.
      EventStatus_DEM_E_TEST_EVENT{20..22}: server-com-spec{operation=SetWIRStatus, queue-length=1}, provided-interface=EventStatus  # This port provides the Supervision interface of DEM_E_TEST_EVENT{20..22} to a SWC.
      EventStatus_DEM_E_TEST_EVENT{3..9}: server-com-spec{operation=SetWIRStatus, queue-length=1}, provided-interface=EventStatus  # This port provides the Supervision interface of DEM_E_TEST_EVENT{3..9} to a SWC.
      EventStatus_DEM_E_TEST_EVENT_E2EXF_MALFORMED_MESSAGE: server-com-spec{operation=SetWIRStatus, queue-length=1}, provided-interface=EventStatus  # This port provides the Supervision interface of DEM_E_TEST_EVENT_E2EXF_MALFORMED_MESSAGE to a SWC.
      EventStatus_DEM_E_TEST_EVENT_SOMEIPXF_MALFORMED_MESSAGE: server-com-spec{operation=SetWIRStatus, queue-length=1}, provided-interface=EventStatus  # This port provides the Supervision interface of DEM_E_TEST_EVENT_SOMEIPXF_MALFORMED_MESSAGE to a SWC.
      EventStatus_ECUM_E_CONFIGURATION_DATA_INCONSISTENT: server-com-spec{operation=SetWIRStatus, queue-length=1}, provided-interface=EventStatus  # This port provides the Supervision interface of ECUM_E_CONFIGURATION_DATA_INCONSISTENT to a SWC.
      EventStatus_ECUM_E_IMPROPER_CALLER: server-com-spec{operation=SetWIRStatus, queue-length=1}, provided-interface=EventStatus  # This port provides the Supervision interface of ECUM_E_IMPROPER_CALLER to a SWC.
      EventStatus_ECUM_E_RAM_CHECK_FAILED: server-com-spec{operation=SetWIRStatus, queue-length=1}, provided-interface=EventStatus  # This port provides the Supervision interface of ECUM_E_RAM_CHECK_FAILED to a SWC.
      EventStatus_EEP_E_COMPARE_FAILED: server-com-spec{operation=SetWIRStatus, queue-length=1}, provided-interface=EventStatus  # This port provides the Supervision interface of EEP_E_COMPARE_FAILED to a SWC.
      EventStatus_EEP_E_ERASE_FAILED: server-com-spec{operation=SetWIRStatus, queue-length=1}, provided-interface=EventStatus  # This port provides the Supervision interface of EEP_E_ERASE_FAILED to a SWC.
      EventStatus_EEP_E_READ_FAILED: server-com-spec{operation=SetWIRStatus, queue-length=1}, provided-interface=EventStatus  # This port provides the Supervision interface of EEP_E_READ_FAILED to a SWC.
      EventStatus_EEP_E_WRITE_FAILED: server-com-spec{operation=SetWIRStatus, queue-length=1}, provided-interface=EventStatus  # This port provides the Supervision interface of EEP_E_WRITE_FAILED to a SWC.
      EventStatus_ETHSM_E_LINK_DOWN: server-com-spec{operation=SetWIRStatus, queue-length=1}, provided-interface=EventStatus  # This port provides the Supervision interface of ETHSM_E_LINK_DOWN to a SWC.
      EventStatus_ETHTRCV_E_ACCESS: server-com-spec{operation=SetWIRStatus, queue-length=1}, provided-interface=EventStatus  # This port provides the Supervision interface of ETHTRCV_E_ACCESS to a SWC.
      EventStatus_ETH_E_ACCESS: server-com-spec{operation=SetWIRStatus, queue-length=1}, provided-interface=EventStatus  # This port provides the Supervision interface of ETH_E_ACCESS to a SWC.
      EventStatus_ETH_E_ALIGNMENT: server-com-spec{operation=SetWIRStatus, queue-length=1}, provided-interface=EventStatus  # This port provides the Supervision interface of ETH_E_ALIGNMENT to a SWC.
      EventStatus_ETH_E_CRC: server-com-spec{operation=SetWIRStatus, queue-length=1}, provided-interface=EventStatus  # This port provides the Supervision interface of ETH_E_CRC to a SWC.
      EventStatus_ETH_E_LATECOLLISON: server-com-spec{operation=SetWIRStatus, queue-length=1}, provided-interface=EventStatus  # This port provides the Supervision interface of ETH_E_LATECOLLISON to a SWC.
      EventStatus_ETH_E_MULTIPLECOLLISION: server-com-spec{operation=SetWIRStatus, queue-length=1}, provided-interface=EventStatus  # This port provides the Supervision interface of ETH_E_MULTIPLECOLLISION to a SWC.
      EventStatus_ETH_E_OVERSIZEFRAME: server-com-spec{operation=SetWIRStatus, queue-length=1}, provided-interface=EventStatus  # This port provides the Supervision interface of ETH_E_OVERSIZEFRAME to a SWC.
      EventStatus_ETH_E_RX_FRAMES_LOST: server-com-spec{operation=SetWIRStatus, queue-length=1}, provided-interface=EventStatus  # This port provides the Supervision interface of ETH_E_RX_FRAMES_LOST to a SWC.
      EventStatus_ETH_E_SINGLECOLLISION: server-com-spec{operation=SetWIRStatus, queue-length=1}, provided-interface=EventStatus  # This port provides the Supervision interface of ETH_E_SINGLECOLLISION to a SWC.
      EventStatus_ETH_E_UNDERSIZRFRAME: server-com-spec{operation=SetWIRStatus, queue-length=1}, provided-interface=EventStatus  # This port provides the Supervision interface of ETH_E_UNDERSIZRFRAME to a SWC.
      EventStatus_FEE_E_GC_ERASE: server-com-spec{operation=SetWIRStatus, queue-length=1}, provided-interface=EventStatus  # This port provides the Supervision interface of FEE_E_GC_ERASE to a SWC.
      EventStatus_FEE_E_GC_INIT: server-com-spec{operation=SetWIRStatus, queue-length=1}, provided-interface=EventStatus  # This port provides the Supervision interface of FEE_E_GC_INIT to a SWC.
      EventStatus_FEE_E_GC_READ: server-com-spec{operation=SetWIRStatus, queue-length=1}, provided-interface=EventStatus  # This port provides the Supervision interface of FEE_E_GC_READ to a SWC.
      EventStatus_FEE_E_GC_TRIG: server-com-spec{operation=SetWIRStatus, queue-length=1}, provided-interface=EventStatus  # This port provides the Supervision interface of FEE_E_GC_TRIG to a SWC.
      EventStatus_FEE_E_GC_WRITE: server-com-spec{operation=SetWIRStatus, queue-length=1}, provided-interface=EventStatus  # This port provides the Supervision interface of FEE_E_GC_WRITE to a SWC.
      EventStatus_FEE_E_INVALIDATE: server-com-spec{operation=SetWIRStatus, queue-length=1}, provided-interface=EventStatus  # This port provides the Supervision interface of FEE_E_INVALIDATE to a SWC.
      EventStatus_FEE_E_READ: server-com-spec{operation=SetWIRStatus, queue-length=1}, provided-interface=EventStatus  # This port provides the Supervision interface of FEE_E_READ to a SWC.
      EventStatus_FEE_E_UNCONFIG_BLK_EXCEEDED: server-com-spec{operation=SetWIRStatus, queue-length=1}, provided-interface=EventStatus  # This port provides the Supervision interface of FEE_E_UNCONFIG_BLK_EXCEEDED to a SWC.
      EventStatus_FEE_E_WRITE: server-com-spec{operation=SetWIRStatus, queue-length=1}, provided-interface=EventStatus  # This port provides the Supervision interface of FEE_E_WRITE to a SWC.
      EventStatus_FEE_E_WRITE_CYCLES_EXHAUSTED: server-com-spec{operation=SetWIRStatus, queue-length=1}, provided-interface=EventStatus  # This port provides the Supervision interface of FEE_E_WRITE_CYCLES_EXHAUSTED to a SWC.
      EventStatus_FLS_E_COMPARE_FAILED: server-com-spec{operation=SetWIRStatus, queue-length=1}, provided-interface=EventStatus  # This port provides the Supervision interface of FLS_E_COMPARE_FAILED to a SWC.
      EventStatus_FLS_E_ERASE_FAILED: server-com-spec{operation=SetWIRStatus, queue-length=1}, provided-interface=EventStatus  # This port provides the Supervision interface of FLS_E_ERASE_FAILED to a SWC.
      EventStatus_FLS_E_READ_FAILED: server-com-spec{operation=SetWIRStatus, queue-length=1}, provided-interface=EventStatus  # This port provides the Supervision interface of FLS_E_READ_FAILED to a SWC.
      EventStatus_FLS_E_UNEXPECTED_FLASH_ID: server-com-spec{operation=SetWIRStatus, queue-length=1}, provided-interface=EventStatus  # This port provides the Supervision interface of FLS_E_UNEXPECTED_FLASH_ID to a SWC.
      EventStatus_FLS_E_WRITE_FAILED: server-com-spec{operation=SetWIRStatus, queue-length=1}, provided-interface=EventStatus  # This port provides the Supervision interface of FLS_E_WRITE_FAILED to a SWC.
      EventStatus_IOHWAB_E_BUSY: server-com-spec{operation=SetWIRStatus, queue-length=1}, provided-interface=EventStatus  # This port provides the Supervision interface of IOHWAB_E_BUSY to a SWC.
      EventStatus_IOHWAB_E_PROC_FAIL: server-com-spec{operation=SetWIRStatus, queue-length=1}, provided-interface=EventStatus  # This port provides the Supervision interface of IOHWAB_E_PROC_FAIL to a SWC.
      EventStatus_IOHWAB_E_SETUP_FAIL: server-com-spec{operation=SetWIRStatus, queue-length=1}, provided-interface=EventStatus  # This port provides the Supervision interface of IOHWAB_E_SETUP_FAIL to a SWC.
      EventStatus_IOHWAB_E_WRONG_PARAM: server-com-spec{operation=SetWIRStatus, queue-length=1}, provided-interface=EventStatus  # This port provides the Supervision interface of IOHWAB_E_WRONG_PARAM to a SWC.
      EventStatus_IOHWAB_E_WRONG_SETTING: server-com-spec{operation=SetWIRStatus, queue-length=1}, provided-interface=EventStatus  # This port provides the Supervision interface of IOHWAB_E_WRONG_SETTING to a SWC.
      EventStatus_IOHWAB_E_WRONG_STATE: server-com-spec{operation=SetWIRStatus, queue-length=1}, provided-interface=EventStatus  # This port provides the Supervision interface of IOHWAB_E_WRONG_STATE to a SWC.
      EventStatus_MCU_E_CCU6_CLC_DISABLE_ERR: server-com-spec{operation=SetWIRStatus, queue-length=1}, provided-interface=EventStatus  # This port provides the Supervision interface of MCU_E_CCU6_CLC_DISABLE_ERR to a SWC.
      EventStatus_MCU_E_CCU6_CLC_ENABLE_ERR: server-com-spec{operation=SetWIRStatus, queue-length=1}, provided-interface=EventStatus  # This port provides the Supervision interface of MCU_E_CCU6_CLC_ENABLE_ERR to a SWC.
      EventStatus_MCU_E_CCUCON_UPDATE_ERR: server-com-spec{operation=SetWIRStatus, queue-length=1}, provided-interface=EventStatus  # This port provides the Supervision interface of MCU_E_CCUCON_UPDATE_ERR to a SWC.
      EventStatus_MCU_E_CLOCK_FAILURE: server-com-spec{operation=SetWIRStatus, queue-length=1}, provided-interface=EventStatus  # This port provides the Supervision interface of MCU_E_CLOCK_FAILURE to a SWC.
      EventStatus_MCU_E_CONVCTRL_CLC_DISABLE_ERR: server-com-spec{operation=SetWIRStatus, queue-length=1}, provided-interface=EventStatus  # This port provides the Supervision interface of MCU_E_CONVCTRL_CLC_DISABLE_ERR to a SWC.
      EventStatus_MCU_E_CONVCTRL_CLC_ENABLE_ERR: server-com-spec{operation=SetWIRStatus, queue-length=1}, provided-interface=EventStatus  # This port provides the Supervision interface of MCU_E_CONVCTRL_CLC_ENABLE_ERR to a SWC.
      EventStatus_MCU_E_GPT12_CLC_DISABLE_ERR: server-com-spec{operation=SetWIRStatus, queue-length=1}, provided-interface=EventStatus  # This port provides the Supervision interface of MCU_E_GPT12_CLC_DISABLE_ERR to a SWC.
      EventStatus_MCU_E_GPT12_CLC_ENABLE_ERR: server-com-spec{operation=SetWIRStatus, queue-length=1}, provided-interface=EventStatus  # This port provides the Supervision interface of MCU_E_GPT12_CLC_ENABLE_ERR to a SWC.
      EventStatus_MCU_E_GTM_CLC_DISABLE_ERR: server-com-spec{operation=SetWIRStatus, queue-length=1}, provided-interface=EventStatus  # This port provides the Supervision interface of MCU_E_GTM_CLC_DISABLE_ERR to a SWC.
      EventStatus_MCU_E_GTM_CLC_ENABLE_ERR: server-com-spec{operation=SetWIRStatus, queue-length=1}, provided-interface=EventStatus  # This port provides the Supervision interface of MCU_E_GTM_CLC_ENABLE_ERR to a SWC.
      EventStatus_MCU_E_OSC_FAILURE: server-com-spec{operation=SetWIRStatus, queue-length=1}, provided-interface=EventStatus  # This port provides the Supervision interface of MCU_E_OSC_FAILURE to a SWC.
      EventStatus_MCU_E_PERIPHERAL_PLL_LOCK_LOSS: server-com-spec{operation=SetWIRStatus, queue-length=1}, provided-interface=EventStatus  # This port provides the Supervision interface of MCU_E_PERIPHERAL_PLL_LOCK_LOSS to a SWC.
      EventStatus_MCU_E_PERIPHERAL_PLL_TIMEOUT_ERR: server-com-spec{operation=SetWIRStatus, queue-length=1}, provided-interface=EventStatus  # This port provides the Supervision interface of MCU_E_PERIPHERAL_PLL_TIMEOUT_ERR to a SWC.
      EventStatus_MCU_E_PMSWCR_UPDATE_ERR: server-com-spec{operation=SetWIRStatus, queue-length=1}, provided-interface=EventStatus  # This port provides the Supervision interface of MCU_E_PMSWCR_UPDATE_ERR to a SWC.
      EventStatus_MCU_E_SYSTEM_PLL_LOCK_LOSS: server-com-spec{operation=SetWIRStatus, queue-length=1}, provided-interface=EventStatus  # This port provides the Supervision interface of MCU_E_SYSTEM_PLL_LOCK_LOSS to a SWC.
      EventStatus_MCU_E_SYSTEM_PLL_TIMEOUT_ERR: server-com-spec{operation=SetWIRStatus, queue-length=1}, provided-interface=EventStatus  # This port provides the Supervision interface of MCU_E_SYSTEM_PLL_TIMEOUT_ERR to a SWC.
      EventStatus_NVM_E_INTEGRITY_FAILED: server-com-spec{operation=SetWIRStatus, queue-length=1}, provided-interface=EventStatus  # This port provides the Supervision interface of NVM_E_INTEGRITY_FAILED to a SWC.
      EventStatus_NVM_E_LOSS_OF_REDUNDANCY: server-com-spec{operation=SetWIRStatus, queue-length=1}, provided-interface=EventStatus  # This port provides the Supervision interface of NVM_E_LOSS_OF_REDUNDANCY to a SWC.
      EventStatus_NVM_E_QUEUE_OVERFLOW: server-com-spec{operation=SetWIRStatus, queue-length=1}, provided-interface=EventStatus  # This port provides the Supervision interface of NVM_E_QUEUE_OVERFLOW to a SWC.
      EventStatus_NVM_E_REQ_FAILED: server-com-spec{operation=SetWIRStatus, queue-length=1}, provided-interface=EventStatus  # This port provides the Supervision interface of NVM_E_REQ_FAILED to a SWC.
      EventStatus_NVM_E_VERIFY_FAILED: server-com-spec{operation=SetWIRStatus, queue-length=1}, provided-interface=EventStatus  # This port provides the Supervision interface of NVM_E_VERIFY_FAILED to a SWC.
      EventStatus_NVM_E_WRITE_PROTECTED: server-com-spec{operation=SetWIRStatus, queue-length=1}, provided-interface=EventStatus  # This port provides the Supervision interface of NVM_E_WRITE_PROTECTED to a SWC.
      EventStatus_NVM_E_WRONG_BLOCK_ID: server-com-spec{operation=SetWIRStatus, queue-length=1}, provided-interface=EventStatus  # This port provides the Supervision interface of NVM_E_WRONG_BLOCK_ID to a SWC.
      EventStatus_SPI_E_HARDWARE_ERROR: server-com-spec{operation=SetWIRStatus, queue-length=1}, provided-interface=EventStatus  # This port provides the Supervision interface of SPI_E_HARDWARE_ERROR to a SWC.
      EventStatus_WDGM_E_IMPROPER_CALLER: server-com-spec{operation=SetWIRStatus, queue-length=1}, provided-interface=EventStatus  # This port provides the Supervision interface of WDGM_E_IMPROPER_CALLER to a SWC.
      EventStatus_WDGM_E_MONITORING: server-com-spec{operation=SetWIRStatus, queue-length=1}, provided-interface=EventStatus  # This port provides the Supervision interface of WDGM_E_MONITORING to a SWC.
      EventStatus_WDGM_E_SET_MODE: server-com-spec{operation=SetWIRStatus, queue-length=1}, provided-interface=EventStatus  # This port provides the Supervision interface of WDGM_E_SET_MODE to a SWC.
      EventStatus_WDG_76_ACW_E_DISABLE_REJECTED: server-com-spec{operation=SetWIRStatus, queue-length=1}, provided-interface=EventStatus  # This port provides the Supervision interface of WDG_76_ACW_E_DISABLE_REJECTED to a SWC.
      EventStatus_WDG_76_ACW_E_MODE_FAILED: server-com-spec{operation=SetWIRStatus, queue-length=1}, provided-interface=EventStatus  # This port provides the Supervision interface of WDG_76_ACW_E_MODE_FAILED to a SWC.
      EventStatus_WDG_E_DISABLE_REJECTED: server-com-spec{operation=SetWIRStatus, queue-length=1}, provided-interface=EventStatus  # This port provides the Supervision interface of WDG_E_DISABLE_REJECTED to a SWC.
      EventStatus_WDG_E_MODE_FAILED: server-com-spec{operation=SetWIRStatus, queue-length=1}, provided-interface=EventStatus  # This port provides the Supervision interface of WDG_E_MODE_FAILED to a SWC.
      Event_CANCM_E_BAT_FAIL: provided-interface=DiagnosticMonitor  # This port provides the Supervision interface of CANCM_E_BAT_FAIL to a SWC.
        provided-com-specs:
          operation=ResetEventDebounceStatus, queue-length=1
          operation=ResetEventStatus, queue-length=1
          operation=SetEventStatus, queue-length=1
      Event_CANSM_E_BUS_OFF_FD_CAN1: provided-interface=DiagnosticMonitor  # This port provides the Supervision interface of CANSM_E_BUS_OFF_FD_CAN1 to a SWC.
        provided-com-specs:
          operation=ResetEventDebounceStatus, queue-length=1
          operation=ResetEventStatus, queue-length=1
          operation=SetEventStatus, queue-length=1
      Event_CANSM_E_BUS_OFF_FD_CAN2: provided-interface=DiagnosticMonitor  # This port provides the Supervision interface of CANSM_E_BUS_OFF_FD_CAN2 to a SWC.
        provided-com-specs:
          operation=ResetEventDebounceStatus, queue-length=1
          operation=ResetEventStatus, queue-length=1
          operation=SetEventStatus, queue-length=1
      Event_CANSM_E_BUS_OFF_HS_CAN1: provided-interface=DiagnosticMonitor  # This port provides the Supervision interface of CANSM_E_BUS_OFF_HS_CAN1 to a SWC.
        provided-com-specs:
          operation=ResetEventDebounceStatus, queue-length=1
          operation=ResetEventStatus, queue-length=1
          operation=SetEventStatus, queue-length=1
      Event_CANSM_E_BUS_OFF_LS_CAN1: provided-interface=DiagnosticMonitor  # This port provides the Supervision interface of CANSM_E_BUS_OFF_LS_CAN1 to a SWC.
        provided-com-specs:
          operation=ResetEventDebounceStatus, queue-length=1
          operation=ResetEventStatus, queue-length=1
          operation=SetEventStatus, queue-length=1
      Event_CANSM_E_BUS_OFF_Project: provided-interface=DiagnosticMonitor  # This port provides the Supervision interface of CANSM_E_BUS_OFF_Project to a SWC.
        provided-com-specs:
          operation=ResetEventDebounceStatus, queue-length=1
          operation=ResetEventStatus, queue-length=1
          operation=SetEventStatus, queue-length=1
      Event_CANSM_E_MODE_CHANGE_FD_CAN1: provided-interface=DiagnosticMonitor  # This port provides the Supervision interface of CANSM_E_MODE_CHANGE_FD_CAN1 to a SWC.
        provided-com-specs:
          operation=ResetEventDebounceStatus, queue-length=1
          operation=ResetEventStatus, queue-length=1
          operation=SetEventStatus, queue-length=1
      Event_CANSM_E_MODE_CHANGE_FD_CAN2: provided-interface=DiagnosticMonitor  # This port provides the Supervision interface of CANSM_E_MODE_CHANGE_FD_CAN2 to a SWC.
        provided-com-specs:
          operation=ResetEventDebounceStatus, queue-length=1
          operation=ResetEventStatus, queue-length=1
          operation=SetEventStatus, queue-length=1
      Event_CANSM_E_MODE_CHANGE_HS_CAN1: provided-interface=DiagnosticMonitor  # This port provides the Supervision interface of CANSM_E_MODE_CHANGE_HS_CAN1 to a SWC.
        provided-com-specs:
          operation=ResetEventDebounceStatus, queue-length=1
          operation=ResetEventStatus, queue-length=1
          operation=SetEventStatus, queue-length=1
      Event_CANSM_E_MODE_CHANGE_LS_CAN1: provided-interface=DiagnosticMonitor  # This port provides the Supervision interface of CANSM_E_MODE_CHANGE_LS_CAN1 to a SWC.
        provided-com-specs:
          operation=ResetEventDebounceStatus, queue-length=1
          operation=ResetEventStatus, queue-length=1
          operation=SetEventStatus, queue-length=1
      Event_CANSM_E_MODE_CHANGE_Project: provided-interface=DiagnosticMonitor  # This port provides the Supervision interface of CANSM_E_MODE_CHANGE_Project to a SWC.
        provided-com-specs:
          operation=ResetEventDebounceStatus, queue-length=1
          operation=ResetEventStatus, queue-length=1
          operation=SetEventStatus, queue-length=1
      Event_CANSM_E_MODE_REQUEST_TIMEOUT_FD_CAN1: provided-interface=DiagnosticMonitor  # This port provides the Supervision interface of CANSM_E_MODE_REQUEST_TIMEOUT_FD_CAN1 to a SWC.
        provided-com-specs:
          operation=ResetEventDebounceStatus, queue-length=1
          operation=ResetEventStatus, queue-length=1
          operation=SetEventStatus, queue-length=1
      Event_CANSM_E_MODE_REQUEST_TIMEOUT_HS_CAN1: provided-interface=DiagnosticMonitor  # This port provides the Supervision interface of CANSM_E_MODE_REQUEST_TIMEOUT_HS_CAN1 to a SWC.
        provided-com-specs:
          operation=ResetEventDebounceStatus, queue-length=1
          operation=ResetEventStatus, queue-length=1
          operation=SetEventStatus, queue-length=1
      Event_DEM_E_TEST_EVENT1: provided-interface=DiagnosticMonitor  # This port provides the Supervision interface of DEM_E_TEST_EVENT1 to a SWC.
        provided-com-specs:
          operation=ResetEventDebounceStatus, queue-length=1
          operation=ResetEventStatus, queue-length=1
          operation=SetEventStatus, queue-length=1
      Event_DEM_E_TEST_EVENT10: provided-interface=DiagnosticMonitor  # This port provides the Supervision interface of DEM_E_TEST_EVENT10 to a SWC.
        provided-com-specs:
          operation=ResetEventDebounceStatus, queue-length=1
          operation=ResetEventStatus, queue-length=1
          operation=SetEventStatus, queue-length=1
      Event_DEM_E_TEST_EVENT11: provided-interface=DiagnosticMonitor  # This port provides the Supervision interface of DEM_E_TEST_EVENT11 to a SWC.
        provided-com-specs:
          operation=ResetEventDebounceStatus, queue-length=1
          operation=ResetEventStatus, queue-length=1
          operation=SetEventStatus, queue-length=1
      Event_DEM_E_TEST_EVENT12: provided-interface=DiagnosticMonitor  # This port provides the Supervision interface of DEM_E_TEST_EVENT12 to a SWC.
        provided-com-specs:
          operation=ResetEventDebounceStatus, queue-length=1
          operation=ResetEventStatus, queue-length=1
          operation=SetEventStatus, queue-length=1
      Event_DEM_E_TEST_EVENT13: provided-interface=DiagnosticMonitor  # This port provides the Supervision interface of DEM_E_TEST_EVENT13 to a SWC.
        provided-com-specs:
          operation=ResetEventDebounceStatus, queue-length=1
          operation=ResetEventStatus, queue-length=1
          operation=SetEventStatus, queue-length=1
      Event_DEM_E_TEST_EVENT14: provided-interface=DiagnosticMonitor  # This port provides the Supervision interface of DEM_E_TEST_EVENT14 to a SWC.
        provided-com-specs:
          operation=ResetEventDebounceStatus, queue-length=1
          operation=ResetEventStatus, queue-length=1
          operation=SetEventStatus, queue-length=1
      Event_DEM_E_TEST_EVENT15: provided-interface=DiagnosticMonitor  # This port provides the Supervision interface of DEM_E_TEST_EVENT15 to a SWC.
        provided-com-specs:
          operation=ResetEventDebounceStatus, queue-length=1
          operation=ResetEventStatus, queue-length=1
          operation=SetEventStatus, queue-length=1
      Event_DEM_E_TEST_EVENT16: provided-interface=DiagnosticMonitor  # This port provides the Supervision interface of DEM_E_TEST_EVENT16 to a SWC.
        provided-com-specs:
          operation=ResetEventDebounceStatus, queue-length=1
          operation=ResetEventStatus, queue-length=1
          operation=SetEventStatus, queue-length=1
      Event_DEM_E_TEST_EVENT17: provided-interface=DiagnosticMonitor  # This port provides the Supervision interface of DEM_E_TEST_EVENT17 to a SWC.
        provided-com-specs:
          operation=ResetEventDebounceStatus, queue-length=1
          operation=ResetEventStatus, queue-length=1
          operation=SetEventStatus, queue-length=1
      Event_DEM_E_TEST_EVENT18: provided-interface=DiagnosticMonitor  # This port provides the Supervision interface of DEM_E_TEST_EVENT18 to a SWC.
        provided-com-specs:
          operation=ResetEventDebounceStatus, queue-length=1
          operation=ResetEventStatus, queue-length=1
          operation=SetEventStatus, queue-length=1
      Event_DEM_E_TEST_EVENT19: provided-interface=DiagnosticMonitor  # This port provides the Supervision interface of DEM_E_TEST_EVENT19 to a SWC.
        provided-com-specs:
          operation=ResetEventDebounceStatus, queue-length=1
          operation=ResetEventStatus, queue-length=1
          operation=SetEventStatus, queue-length=1
      Event_DEM_E_TEST_EVENT2: provided-interface=DiagnosticMonitor  # This port provides the Supervision interface of DEM_E_TEST_EVENT2 to a SWC.
        provided-com-specs:
          operation=ResetEventDebounceStatus, queue-length=1
          operation=ResetEventStatus, queue-length=1
          operation=SetEventStatus, queue-length=1
      Event_DEM_E_TEST_EVENT20: provided-interface=DiagnosticMonitor  # This port provides the Supervision interface of DEM_E_TEST_EVENT20 to a SWC.
        provided-com-specs:
          operation=ResetEventDebounceStatus, queue-length=1
          operation=ResetEventStatus, queue-length=1
          operation=SetEventStatus, queue-length=1
      Event_DEM_E_TEST_EVENT21: provided-interface=DiagnosticMonitor  # This port provides the Supervision interface of DEM_E_TEST_EVENT21 to a SWC.
        provided-com-specs:
          operation=ResetEventDebounceStatus, queue-length=1
          operation=ResetEventStatus, queue-length=1
          operation=SetEventStatus, queue-length=1
      Event_DEM_E_TEST_EVENT22: provided-interface=DiagnosticMonitor  # This port provides the Supervision interface of DEM_E_TEST_EVENT22 to a SWC.
        provided-com-specs:
          operation=ResetEventDebounceStatus, queue-length=1
          operation=ResetEventStatus, queue-length=1
          operation=SetEventStatus, queue-length=1
      Event_DEM_E_TEST_EVENT3: provided-interface=DiagnosticMonitor  # This port provides the Supervision interface of DEM_E_TEST_EVENT3 to a SWC.
        provided-com-specs:
          operation=ResetEventDebounceStatus, queue-length=1
          operation=ResetEventStatus, queue-length=1
          operation=SetEventStatus, queue-length=1
      Event_DEM_E_TEST_EVENT4: provided-interface=DiagnosticMonitor  # This port provides the Supervision interface of DEM_E_TEST_EVENT4 to a SWC.
        provided-com-specs:
          operation=ResetEventDebounceStatus, queue-length=1
          operation=ResetEventStatus, queue-length=1
          operation=SetEventStatus, queue-length=1
      Event_DEM_E_TEST_EVENT5: provided-interface=DiagnosticMonitor  # This port provides the Supervision interface of DEM_E_TEST_EVENT5 to a SWC.
        provided-com-specs:
          operation=ResetEventDebounceStatus, queue-length=1
          operation=ResetEventStatus, queue-length=1
          operation=SetEventStatus, queue-length=1
      Event_DEM_E_TEST_EVENT6: provided-interface=DiagnosticMonitor  # This port provides the Supervision interface of DEM_E_TEST_EVENT6 to a SWC.
        provided-com-specs:
          operation=ResetEventDebounceStatus, queue-length=1
          operation=ResetEventStatus, queue-length=1
          operation=SetEventStatus, queue-length=1
      Event_DEM_E_TEST_EVENT7: provided-interface=DiagnosticMonitor  # This port provides the Supervision interface of DEM_E_TEST_EVENT7 to a SWC.
        provided-com-specs:
          operation=ResetEventDebounceStatus, queue-length=1
          operation=ResetEventStatus, queue-length=1
          operation=SetEventStatus, queue-length=1
      Event_DEM_E_TEST_EVENT8: provided-interface=DiagnosticMonitor  # This port provides the Supervision interface of DEM_E_TEST_EVENT8 to a SWC.
        provided-com-specs:
          operation=ResetEventDebounceStatus, queue-length=1
          operation=ResetEventStatus, queue-length=1
          operation=SetEventStatus, queue-length=1
      Event_DEM_E_TEST_EVENT9: provided-interface=DiagnosticMonitor  # This port provides the Supervision interface of DEM_E_TEST_EVENT9 to a SWC.
        provided-com-specs:
          operation=ResetEventDebounceStatus, queue-length=1
          operation=ResetEventStatus, queue-length=1
          operation=SetEventStatus, queue-length=1
      Event_DEM_E_TEST_EVENT_E2EXF_MALFORMED_MESSAGE: provided-interface=DiagnosticMonitor  # This port provides the Supervision interface of DEM_E_TEST_EVENT_E2EXF_MALFORMED_MESSAGE to a SWC.
        provided-com-specs:
          operation=ResetEventDebounceStatus, queue-length=1
          operation=ResetEventStatus, queue-length=1
          operation=SetEventStatus, queue-length=1
      Event_DEM_E_TEST_EVENT_SOMEIPXF_MALFORMED_MESSAGE: provided-interface=DiagnosticMonitor  # This port provides the Supervision interface of DEM_E_TEST_EVENT_SOMEIPXF_MALFORMED_MESSAGE to a SWC.
        provided-com-specs:
          operation=ResetEventDebounceStatus, queue-length=1
          operation=ResetEventStatus, queue-length=1
          operation=SetEventStatus, queue-length=1
      Event_ECUM_E_CONFIGURATION_DATA_INCONSISTENT: provided-interface=DiagnosticMonitor  # This port provides the Supervision interface of ECUM_E_CONFIGURATION_DATA_INCONSISTENT to a SWC.
        provided-com-specs:
          operation=ResetEventDebounceStatus, queue-length=1
          operation=ResetEventStatus, queue-length=1
          operation=SetEventStatus, queue-length=1
      Event_ECUM_E_IMPROPER_CALLER: provided-interface=DiagnosticMonitor  # This port provides the Supervision interface of ECUM_E_IMPROPER_CALLER to a SWC.
        provided-com-specs:
          operation=ResetEventDebounceStatus, queue-length=1
          operation=ResetEventStatus, queue-length=1
          operation=SetEventStatus, queue-length=1
      Event_ECUM_E_RAM_CHECK_FAILED: provided-interface=DiagnosticMonitor  # This port provides the Supervision interface of ECUM_E_RAM_CHECK_FAILED to a SWC.
        provided-com-specs:
          operation=ResetEventDebounceStatus, queue-length=1
          operation=ResetEventStatus, queue-length=1
          operation=SetEventStatus, queue-length=1
      Event_EEP_E_COMPARE_FAILED: provided-interface=DiagnosticMonitor  # This port provides the Supervision interface of EEP_E_COMPARE_FAILED to a SWC.
        provided-com-specs:
          operation=ResetEventDebounceStatus, queue-length=1
          operation=ResetEventStatus, queue-length=1
          operation=SetEventStatus, queue-length=1
      Event_EEP_E_ERASE_FAILED: provided-interface=DiagnosticMonitor  # This port provides the Supervision interface of EEP_E_ERASE_FAILED to a SWC.
        provided-com-specs:
          operation=ResetEventDebounceStatus, queue-length=1
          operation=ResetEventStatus, queue-length=1
          operation=SetEventStatus, queue-length=1
      Event_EEP_E_READ_FAILED: provided-interface=DiagnosticMonitor  # This port provides the Supervision interface of EEP_E_READ_FAILED to a SWC.
        provided-com-specs:
          operation=ResetEventDebounceStatus, queue-length=1
          operation=ResetEventStatus, queue-length=1
          operation=SetEventStatus, queue-length=1
      Event_EEP_E_WRITE_FAILED: provided-interface=DiagnosticMonitor  # This port provides the Supervision interface of EEP_E_WRITE_FAILED to a SWC.
        provided-com-specs:
          operation=ResetEventDebounceStatus, queue-length=1
          operation=ResetEventStatus, queue-length=1
          operation=SetEventStatus, queue-length=1
      Event_ETHSM_E_LINK_DOWN: provided-interface=DiagnosticMonitor  # This port provides the Supervision interface of ETHSM_E_LINK_DOWN to a SWC.
        provided-com-specs:
          operation=ResetEventDebounceStatus, queue-length=1
          operation=ResetEventStatus, queue-length=1
          operation=SetEventStatus, queue-length=1
      Event_ETHTRCV_E_ACCESS: provided-interface=DiagnosticMonitor  # This port provides the Supervision interface of ETHTRCV_E_ACCESS to a SWC.
        provided-com-specs:
          operation=ResetEventDebounceStatus, queue-length=1
          operation=ResetEventStatus, queue-length=1
          operation=SetEventStatus, queue-length=1
      Event_ETH_E_ACCESS: provided-interface=DiagnosticMonitor  # This port provides the Supervision interface of ETH_E_ACCESS to a SWC.
        provided-com-specs:
          operation=ResetEventDebounceStatus, queue-length=1
          operation=ResetEventStatus, queue-length=1
          operation=SetEventStatus, queue-length=1
      Event_ETH_E_ALIGNMENT: provided-interface=DiagnosticMonitor  # This port provides the Supervision interface of ETH_E_ALIGNMENT to a SWC.
        provided-com-specs:
          operation=ResetEventDebounceStatus, queue-length=1
          operation=ResetEventStatus, queue-length=1
          operation=SetEventStatus, queue-length=1
      Event_ETH_E_CRC: provided-interface=DiagnosticMonitor  # This port provides the Supervision interface of ETH_E_CRC to a SWC.
        provided-com-specs:
          operation=ResetEventDebounceStatus, queue-length=1
          operation=ResetEventStatus, queue-length=1
          operation=SetEventStatus, queue-length=1
      Event_ETH_E_LATECOLLISON: provided-interface=DiagnosticMonitor  # This port provides the Supervision interface of ETH_E_LATECOLLISON to a SWC.
        provided-com-specs:
          operation=ResetEventDebounceStatus, queue-length=1
          operation=ResetEventStatus, queue-length=1
          operation=SetEventStatus, queue-length=1
      Event_ETH_E_MULTIPLECOLLISION: provided-interface=DiagnosticMonitor  # This port provides the Supervision interface of ETH_E_MULTIPLECOLLISION to a SWC.
        provided-com-specs:
          operation=ResetEventDebounceStatus, queue-length=1
          operation=ResetEventStatus, queue-length=1
          operation=SetEventStatus, queue-length=1
      Event_ETH_E_OVERSIZEFRAME: provided-interface=DiagnosticMonitor  # This port provides the Supervision interface of ETH_E_OVERSIZEFRAME to a SWC.
        provided-com-specs:
          operation=ResetEventDebounceStatus, queue-length=1
          operation=ResetEventStatus, queue-length=1
          operation=SetEventStatus, queue-length=1
      Event_ETH_E_RX_FRAMES_LOST: provided-interface=DiagnosticMonitor  # This port provides the Supervision interface of ETH_E_RX_FRAMES_LOST to a SWC.
        provided-com-specs:
          operation=ResetEventDebounceStatus, queue-length=1
          operation=ResetEventStatus, queue-length=1
          operation=SetEventStatus, queue-length=1
      Event_ETH_E_SINGLECOLLISION: provided-interface=DiagnosticMonitor  # This port provides the Supervision interface of ETH_E_SINGLECOLLISION to a SWC.
        provided-com-specs:
          operation=ResetEventDebounceStatus, queue-length=1
          operation=ResetEventStatus, queue-length=1
          operation=SetEventStatus, queue-length=1
      Event_ETH_E_UNDERSIZRFRAME: provided-interface=DiagnosticMonitor  # This port provides the Supervision interface of ETH_E_UNDERSIZRFRAME to a SWC.
        provided-com-specs:
          operation=ResetEventDebounceStatus, queue-length=1
          operation=ResetEventStatus, queue-length=1
          operation=SetEventStatus, queue-length=1
      Event_FEE_E_GC_ERASE: provided-interface=DiagnosticMonitor  # This port provides the Supervision interface of FEE_E_GC_ERASE to a SWC.
        provided-com-specs:
          operation=ResetEventDebounceStatus, queue-length=1
          operation=ResetEventStatus, queue-length=1
          operation=SetEventStatus, queue-length=1
      Event_FEE_E_GC_INIT: provided-interface=DiagnosticMonitor  # This port provides the Supervision interface of FEE_E_GC_INIT to a SWC.
        provided-com-specs:
          operation=ResetEventDebounceStatus, queue-length=1
          operation=ResetEventStatus, queue-length=1
          operation=SetEventStatus, queue-length=1
      Event_FEE_E_GC_READ: provided-interface=DiagnosticMonitor  # This port provides the Supervision interface of FEE_E_GC_READ to a SWC.
        provided-com-specs:
          operation=ResetEventDebounceStatus, queue-length=1
          operation=ResetEventStatus, queue-length=1
          operation=SetEventStatus, queue-length=1
      Event_FEE_E_GC_TRIG: provided-interface=DiagnosticMonitor  # This port provides the Supervision interface of FEE_E_GC_TRIG to a SWC.
        provided-com-specs:
          operation=ResetEventDebounceStatus, queue-length=1
          operation=ResetEventStatus, queue-length=1
          operation=SetEventStatus, queue-length=1
      Event_FEE_E_GC_WRITE: provided-interface=DiagnosticMonitor  # This port provides the Supervision interface of FEE_E_GC_WRITE to a SWC.
        provided-com-specs:
          operation=ResetEventDebounceStatus, queue-length=1
          operation=ResetEventStatus, queue-length=1
          operation=SetEventStatus, queue-length=1
      Event_FEE_E_INVALIDATE: provided-interface=DiagnosticMonitor  # This port provides the Supervision interface of FEE_E_INVALIDATE to a SWC.
        provided-com-specs:
          operation=ResetEventDebounceStatus, queue-length=1
          operation=ResetEventStatus, queue-length=1
          operation=SetEventStatus, queue-length=1
      Event_FEE_E_READ: provided-interface=DiagnosticMonitor  # This port provides the Supervision interface of FEE_E_READ to a SWC.
        provided-com-specs:
          operation=ResetEventDebounceStatus, queue-length=1
          operation=ResetEventStatus, queue-length=1
          operation=SetEventStatus, queue-length=1
      Event_FEE_E_UNCONFIG_BLK_EXCEEDED: provided-interface=DiagnosticMonitor  # This port provides the Supervision interface of FEE_E_UNCONFIG_BLK_EXCEEDED to a SWC.
        provided-com-specs:
          operation=ResetEventDebounceStatus, queue-length=1
          operation=ResetEventStatus, queue-length=1
          operation=SetEventStatus, queue-length=1
      Event_FEE_E_WRITE: provided-interface=DiagnosticMonitor  # This port provides the Supervision interface of FEE_E_WRITE to a SWC.
        provided-com-specs:
          operation=ResetEventDebounceStatus, queue-length=1
          operation=ResetEventStatus, queue-length=1
          operation=SetEventStatus, queue-length=1
      Event_FEE_E_WRITE_CYCLES_EXHAUSTED: provided-interface=DiagnosticMonitor  # This port provides the Supervision interface of FEE_E_WRITE_CYCLES_EXHAUSTED to a SWC.
        provided-com-specs:
          operation=ResetEventDebounceStatus, queue-length=1
          operation=ResetEventStatus, queue-length=1
          operation=SetEventStatus, queue-length=1
      Event_FLS_E_COMPARE_FAILED: provided-interface=DiagnosticMonitor  # This port provides the Supervision interface of FLS_E_COMPARE_FAILED to a SWC.
        provided-com-specs:
          operation=ResetEventDebounceStatus, queue-length=1
          operation=ResetEventStatus, queue-length=1
          operation=SetEventStatus, queue-length=1
      Event_FLS_E_ERASE_FAILED: provided-interface=DiagnosticMonitor  # This port provides the Supervision interface of FLS_E_ERASE_FAILED to a SWC.
        provided-com-specs:
          operation=ResetEventDebounceStatus, queue-length=1
          operation=ResetEventStatus, queue-length=1
          operation=SetEventStatus, queue-length=1
      Event_FLS_E_READ_FAILED: provided-interface=DiagnosticMonitor  # This port provides the Supervision interface of FLS_E_READ_FAILED to a SWC.
        provided-com-specs:
          operation=ResetEventDebounceStatus, queue-length=1
          operation=ResetEventStatus, queue-length=1
          operation=SetEventStatus, queue-length=1
      Event_FLS_E_UNEXPECTED_FLASH_ID: provided-interface=DiagnosticMonitor  # This port provides the Supervision interface of FLS_E_UNEXPECTED_FLASH_ID to a SWC.
        provided-com-specs:
          operation=ResetEventDebounceStatus, queue-length=1
          operation=ResetEventStatus, queue-length=1
          operation=SetEventStatus, queue-length=1
      Event_FLS_E_WRITE_FAILED: provided-interface=DiagnosticMonitor  # This port provides the Supervision interface of FLS_E_WRITE_FAILED to a SWC.
        provided-com-specs:
          operation=ResetEventDebounceStatus, queue-length=1
          operation=ResetEventStatus, queue-length=1
          operation=SetEventStatus, queue-length=1
      Event_IOHWAB_E_BUSY: provided-interface=DiagnosticMonitor  # This port provides the Supervision interface of IOHWAB_E_BUSY to a SWC.
        provided-com-specs:
          operation=ResetEventDebounceStatus, queue-length=1
          operation=ResetEventStatus, queue-length=1
          operation=SetEventStatus, queue-length=1
      Event_IOHWAB_E_PROC_FAIL: provided-interface=DiagnosticMonitor  # This port provides the Supervision interface of IOHWAB_E_PROC_FAIL to a SWC.
        provided-com-specs:
          operation=ResetEventDebounceStatus, queue-length=1
          operation=ResetEventStatus, queue-length=1
          operation=SetEventStatus, queue-length=1
      Event_IOHWAB_E_SETUP_FAIL: provided-interface=DiagnosticMonitor  # This port provides the Supervision interface of IOHWAB_E_SETUP_FAIL to a SWC.
        provided-com-specs:
          operation=ResetEventDebounceStatus, queue-length=1
          operation=ResetEventStatus, queue-length=1
          operation=SetEventStatus, queue-length=1
      Event_IOHWAB_E_WRONG_PARAM: provided-interface=DiagnosticMonitor  # This port provides the Supervision interface of IOHWAB_E_WRONG_PARAM to a SWC.
        provided-com-specs:
          operation=ResetEventDebounceStatus, queue-length=1
          operation=ResetEventStatus, queue-length=1
          operation=SetEventStatus, queue-length=1
      Event_IOHWAB_E_WRONG_SETTING: provided-interface=DiagnosticMonitor  # This port provides the Supervision interface of IOHWAB_E_WRONG_SETTING to a SWC.
        provided-com-specs:
          operation=ResetEventDebounceStatus, queue-length=1
          operation=ResetEventStatus, queue-length=1
          operation=SetEventStatus, queue-length=1
      Event_IOHWAB_E_WRONG_STATE: provided-interface=DiagnosticMonitor  # This port provides the Supervision interface of IOHWAB_E_WRONG_STATE to a SWC.
        provided-com-specs:
          operation=ResetEventDebounceStatus, queue-length=1
          operation=ResetEventStatus, queue-length=1
          operation=SetEventStatus, queue-length=1
      Event_MCU_E_CCU6_CLC_DISABLE_ERR: provided-interface=DiagnosticMonitor  # This port provides the Supervision interface of MCU_E_CCU6_CLC_DISABLE_ERR to a SWC.
        provided-com-specs:
          operation=ResetEventDebounceStatus, queue-length=1
          operation=ResetEventStatus, queue-length=1
          operation=SetEventStatus, queue-length=1
      Event_MCU_E_CCU6_CLC_ENABLE_ERR: provided-interface=DiagnosticMonitor  # This port provides the Supervision interface of MCU_E_CCU6_CLC_ENABLE_ERR to a SWC.
        provided-com-specs:
          operation=ResetEventDebounceStatus, queue-length=1
          operation=ResetEventStatus, queue-length=1
          operation=SetEventStatus, queue-length=1
      Event_MCU_E_CCUCON_UPDATE_ERR: provided-interface=DiagnosticMonitor  # This port provides the Supervision interface of MCU_E_CCUCON_UPDATE_ERR to a SWC.
        provided-com-specs:
          operation=ResetEventDebounceStatus, queue-length=1
          operation=ResetEventStatus, queue-length=1
          operation=SetEventStatus, queue-length=1
      Event_MCU_E_CLOCK_FAILURE: provided-interface=DiagnosticMonitor  # This port provides the Supervision interface of MCU_E_CLOCK_FAILURE to a SWC.
        provided-com-specs:
          operation=ResetEventDebounceStatus, queue-length=1
          operation=ResetEventStatus, queue-length=1
          operation=SetEventStatus, queue-length=1
      Event_MCU_E_CONVCTRL_CLC_DISABLE_ERR: provided-interface=DiagnosticMonitor  # This port provides the Supervision interface of MCU_E_CONVCTRL_CLC_DISABLE_ERR to a SWC.
        provided-com-specs:
          operation=ResetEventDebounceStatus, queue-length=1
          operation=ResetEventStatus, queue-length=1
          operation=SetEventStatus, queue-length=1
      Event_MCU_E_CONVCTRL_CLC_ENABLE_ERR: provided-interface=DiagnosticMonitor  # This port provides the Supervision interface of MCU_E_CONVCTRL_CLC_ENABLE_ERR to a SWC.
        provided-com-specs:
          operation=ResetEventDebounceStatus, queue-length=1
          operation=ResetEventStatus, queue-length=1
          operation=SetEventStatus, queue-length=1
      Event_MCU_E_GPT12_CLC_DISABLE_ERR: provided-interface=DiagnosticMonitor  # This port provides the Supervision interface of MCU_E_GPT12_CLC_DISABLE_ERR to a SWC.
        provided-com-specs:
          operation=ResetEventDebounceStatus, queue-length=1
          operation=ResetEventStatus, queue-length=1
          operation=SetEventStatus, queue-length=1
      Event_MCU_E_GPT12_CLC_ENABLE_ERR: provided-interface=DiagnosticMonitor  # This port provides the Supervision interface of MCU_E_GPT12_CLC_ENABLE_ERR to a SWC.
        provided-com-specs:
          operation=ResetEventDebounceStatus, queue-length=1
          operation=ResetEventStatus, queue-length=1
          operation=SetEventStatus, queue-length=1
      Event_MCU_E_GTM_CLC_DISABLE_ERR: provided-interface=DiagnosticMonitor  # This port provides the Supervision interface of MCU_E_GTM_CLC_DISABLE_ERR to a SWC.
        provided-com-specs:
          operation=ResetEventDebounceStatus, queue-length=1
          operation=ResetEventStatus, queue-length=1
          operation=SetEventStatus, queue-length=1
      Event_MCU_E_GTM_CLC_ENABLE_ERR: provided-interface=DiagnosticMonitor  # This port provides the Supervision interface of MCU_E_GTM_CLC_ENABLE_ERR to a SWC.
        provided-com-specs:
          operation=ResetEventDebounceStatus, queue-length=1
          operation=ResetEventStatus, queue-length=1
          operation=SetEventStatus, queue-length=1
      Event_MCU_E_OSC_FAILURE: provided-interface=DiagnosticMonitor  # This port provides the Supervision interface of MCU_E_OSC_FAILURE to a SWC.
        provided-com-specs:
          operation=ResetEventDebounceStatus, queue-length=1
          operation=ResetEventStatus, queue-length=1
          operation=SetEventStatus, queue-length=1
      Event_MCU_E_PERIPHERAL_PLL_LOCK_LOSS: provided-interface=DiagnosticMonitor  # This port provides the Supervision interface of MCU_E_PERIPHERAL_PLL_LOCK_LOSS to a SWC.
        provided-com-specs:
          operation=ResetEventDebounceStatus, queue-length=1
          operation=ResetEventStatus, queue-length=1
          operation=SetEventStatus, queue-length=1
      Event_MCU_E_PERIPHERAL_PLL_TIMEOUT_ERR: provided-interface=DiagnosticMonitor  # This port provides the Supervision interface of MCU_E_PERIPHERAL_PLL_TIMEOUT_ERR to a SWC.
        provided-com-specs:
          operation=ResetEventDebounceStatus, queue-length=1
          operation=ResetEventStatus, queue-length=1
          operation=SetEventStatus, queue-length=1
      Event_MCU_E_PMSWCR_UPDATE_ERR: provided-interface=DiagnosticMonitor  # This port provides the Supervision interface of MCU_E_PMSWCR_UPDATE_ERR to a SWC.
        provided-com-specs:
          operation=ResetEventDebounceStatus, queue-length=1
          operation=ResetEventStatus, queue-length=1
          operation=SetEventStatus, queue-length=1
      Event_MCU_E_SYSTEM_PLL_LOCK_LOSS: provided-interface=DiagnosticMonitor  # This port provides the Supervision interface of MCU_E_SYSTEM_PLL_LOCK_LOSS to a SWC.
        provided-com-specs:
          operation=ResetEventDebounceStatus, queue-length=1
          operation=ResetEventStatus, queue-length=1
          operation=SetEventStatus, queue-length=1
      Event_MCU_E_SYSTEM_PLL_TIMEOUT_ERR: provided-interface=DiagnosticMonitor  # This port provides the Supervision interface of MCU_E_SYSTEM_PLL_TIMEOUT_ERR to a SWC.
        provided-com-specs:
          operation=ResetEventDebounceStatus, queue-length=1
          operation=ResetEventStatus, queue-length=1
          operation=SetEventStatus, queue-length=1
      Event_NVM_E_INTEGRITY_FAILED: provided-interface=DiagnosticMonitor  # This port provides the Supervision interface of NVM_E_INTEGRITY_FAILED to a SWC.
        provided-com-specs:
          operation=ResetEventDebounceStatus, queue-length=1
          operation=ResetEventStatus, queue-length=1
          operation=SetEventStatus, queue-length=1
      Event_NVM_E_LOSS_OF_REDUNDANCY: provided-interface=DiagnosticMonitor  # This port provides the Supervision interface of NVM_E_LOSS_OF_REDUNDANCY to a SWC.
        provided-com-specs:
          operation=ResetEventDebounceStatus, queue-length=1
          operation=ResetEventStatus, queue-length=1
          operation=SetEventStatus, queue-length=1
      Event_NVM_E_QUEUE_OVERFLOW: provided-interface=DiagnosticMonitor  # This port provides the Supervision interface of NVM_E_QUEUE_OVERFLOW to a SWC.
        provided-com-specs:
          operation=ResetEventDebounceStatus, queue-length=1
          operation=ResetEventStatus, queue-length=1
          operation=SetEventStatus, queue-length=1
      Event_NVM_E_REQ_FAILED: provided-interface=DiagnosticMonitor  # This port provides the Supervision interface of NVM_E_REQ_FAILED to a SWC.
        provided-com-specs:
          operation=ResetEventDebounceStatus, queue-length=1
          operation=ResetEventStatus, queue-length=1
          operation=SetEventStatus, queue-length=1
      Event_NVM_E_VERIFY_FAILED: provided-interface=DiagnosticMonitor  # This port provides the Supervision interface of NVM_E_VERIFY_FAILED to a SWC.
        provided-com-specs:
          operation=ResetEventDebounceStatus, queue-length=1
          operation=ResetEventStatus, queue-length=1
          operation=SetEventStatus, queue-length=1
      Event_NVM_E_WRITE_PROTECTED: provided-interface=DiagnosticMonitor  # This port provides the Supervision interface of NVM_E_WRITE_PROTECTED to a SWC.
        provided-com-specs:
          operation=ResetEventDebounceStatus, queue-length=1
          operation=ResetEventStatus, queue-length=1
          operation=SetEventStatus, queue-length=1
      Event_NVM_E_WRONG_BLOCK_ID: provided-interface=DiagnosticMonitor  # This port provides the Supervision interface of NVM_E_WRONG_BLOCK_ID to a SWC.
        provided-com-specs:
          operation=ResetEventDebounceStatus, queue-length=1
          operation=ResetEventStatus, queue-length=1
          operation=SetEventStatus, queue-length=1
      Event_SPI_E_HARDWARE_ERROR: provided-interface=DiagnosticMonitor  # This port provides the Supervision interface of SPI_E_HARDWARE_ERROR to a SWC.
        provided-com-specs:
          operation=ResetEventDebounceStatus, queue-length=1
          operation=ResetEventStatus, queue-length=1
          operation=SetEventStatus, queue-length=1
      Event_WDGM_E_IMPROPER_CALLER: provided-interface=DiagnosticMonitor  # This port provides the Supervision interface of WDGM_E_IMPROPER_CALLER to a SWC.
        provided-com-specs:
          operation=ResetEventDebounceStatus, queue-length=1
          operation=ResetEventStatus, queue-length=1
          operation=SetEventStatus, queue-length=1
      Event_WDGM_E_MONITORING: provided-interface=DiagnosticMonitor  # This port provides the Supervision interface of WDGM_E_MONITORING to a SWC.
        provided-com-specs:
          operation=ResetEventDebounceStatus, queue-length=1
          operation=ResetEventStatus, queue-length=1
          operation=SetEventStatus, queue-length=1
      Event_WDGM_E_SET_MODE: provided-interface=DiagnosticMonitor  # This port provides the Supervision interface of WDGM_E_SET_MODE to a SWC.
        provided-com-specs:
          operation=ResetEventDebounceStatus, queue-length=1
          operation=ResetEventStatus, queue-length=1
          operation=SetEventStatus, queue-length=1
      Event_WDG_76_ACW_E_DISABLE_REJECTED: provided-interface=DiagnosticMonitor  # This port provides the Supervision interface of WDG_76_ACW_E_DISABLE_REJECTED to a SWC.
        provided-com-specs:
          operation=ResetEventDebounceStatus, queue-length=1
          operation=ResetEventStatus, queue-length=1
          operation=SetEventStatus, queue-length=1
      Event_WDG_76_ACW_E_MODE_FAILED: provided-interface=DiagnosticMonitor  # This port provides the Supervision interface of WDG_76_ACW_E_MODE_FAILED to a SWC.
        provided-com-specs:
          operation=ResetEventDebounceStatus, queue-length=1
          operation=ResetEventStatus, queue-length=1
          operation=SetEventStatus, queue-length=1
      Event_WDG_E_DISABLE_REJECTED: provided-interface=DiagnosticMonitor  # This port provides the Supervision interface of WDG_E_DISABLE_REJECTED to a SWC.
        provided-com-specs:
          operation=ResetEventDebounceStatus, queue-length=1
          operation=ResetEventStatus, queue-length=1
          operation=SetEventStatus, queue-length=1
      Event_WDG_E_MODE_FAILED: provided-interface=DiagnosticMonitor  # This port provides the Supervision interface of WDG_E_MODE_FAILED to a SWC.
        provided-com-specs:
          operation=ResetEventDebounceStatus, queue-length=1
          operation=ResetEventStatus, queue-length=1
          operation=SetEventStatus, queue-length=1
    require port GeneralCBDataEvt: client-com-spec=GeneralCallbackEventDataChanged/EventDataChanged, required-interface=GeneralCallbackEventDataChanged
    require port GeneralCBMonitorStatusChanged: client-com-spec=GeneralCallbackMonitorStatusChanged/MonitorStatusChanged, required-interface=GeneralCallbackMonitorStatusChanged
    require port GeneralCBStatusEvt: client-com-spec=GeneralCallbackEventUdsStatusChanged, required-interface=GeneralCallbackEventUdsStatusChanged
